VERSION ""

NS_ :

BS_:

BU_:

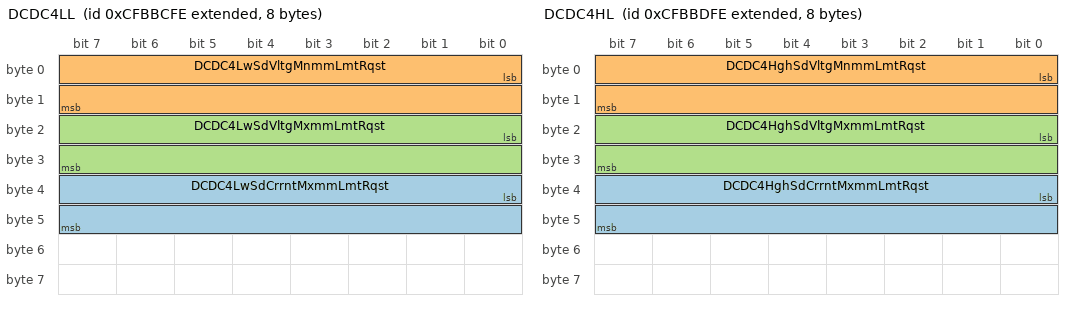
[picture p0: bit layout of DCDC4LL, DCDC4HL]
BO_ 2365308158 DCDC4LL: 8 Vector__XXX
 SG_ DCDC4LwSdCrrntMxmmLmtRqst : 32|16@1+ (0.05,0) [0|3212.75] "A" Vector__XXX
 SG_ DCDC4LwSdVltgMnmmLmtRqst : 0|16@1+ (0.01,0) [0|642.55] "V" Vector__XXX
 SG_ DCDC4LwSdVltgMxmmLmtRqst : 16|16@1+ (0.01,0) [0|642.55] "V" Vector__XXX

BO_ 2365308414 DCDC4HL: 8 Vector__XXX
 SG_ DCDC4HghSdCrrntMxmmLmtRqst : 32|16@1+ (0.05,0) [0|3212.75] "A" Vector__XXX
 SG_ DCDC4HghSdVltgMnmmLmtRqst : 0|16@1+ (0.05,0) [0|3212.75] "V" Vector__XXX
 SG_ DCDC4HghSdVltgMxmmLmtRqst : 16|16@1+ (0.05,0) [0|3212.75] "V" Vector__XXX

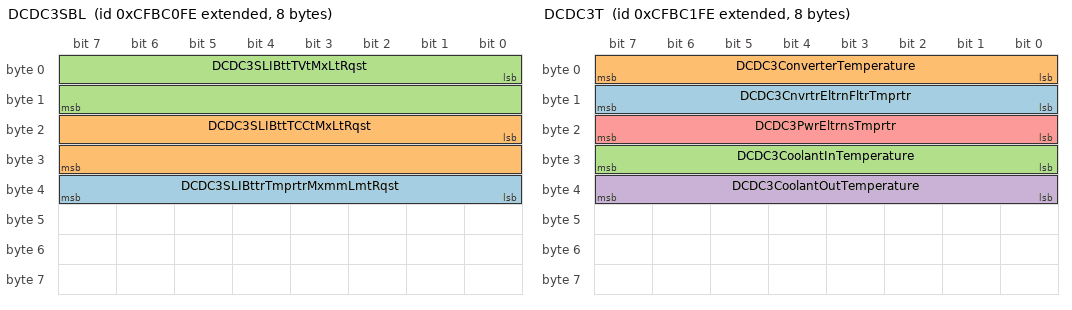
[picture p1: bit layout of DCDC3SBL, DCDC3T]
BO_ 2365309182 DCDC3SBL: 8 Vector__XXX
 SG_ DCDC3SLIBttrTmprtrMxmmLmtRqst : 32|8@1+ (1,-40) [-40|210] "degC" Vector__XXX
 SG_ DCDC3SLIBttTCCtMxLtRqst : 16|16@1+ (0.05,0) [0|3212.75] "A" Vector__XXX
 SG_ DCDC3SLIBttTVtMxLtRqst : 0|16@1+ (0.01,0) [0|642.55] "V" Vector__XXX

BO_ 2365309438 DCDC3T: 8 Vector__XXX
 SG_ DCDC3CnvrtrEltrnFltrTmprtr : 8|8@1+ (1,-40) [-40|210] "degC" Vector__XXX
 SG_ DCDC3ConverterTemperature : 0|8@1+ (1,-40) [-40|210] "degC" Vector__XXX
 SG_ DCDC3CoolantInTemperature : 24|8@1+ (1,-40) [-40|210] "degC" Vector__XXX
 SG_ DCDC3CoolantOutTemperature : 32|8@1+ (1,-40) [-40|210] "degC" Vector__XXX
 SG_ DCDC3PwrEltrnsTmprtr : 16|8@1+ (1,-40) [-40|210] "degC" Vector__XXX

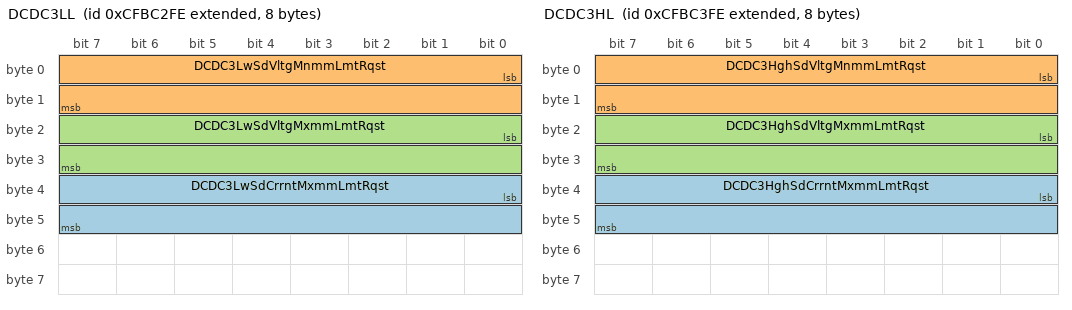
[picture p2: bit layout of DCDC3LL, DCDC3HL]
BO_ 2365309694 DCDC3LL: 8 Vector__XXX
 SG_ DCDC3LwSdCrrntMxmmLmtRqst : 32|16@1+ (0.05,0) [0|3212.75] "A" Vector__XXX
 SG_ DCDC3LwSdVltgMnmmLmtRqst : 0|16@1+ (0.01,0) [0|642.55] "V" Vector__XXX
 SG_ DCDC3LwSdVltgMxmmLmtRqst : 16|16@1+ (0.01,0) [0|642.55] "V" Vector__XXX

BO_ 2365309950 DCDC3HL: 8 Vector__XXX
 SG_ DCDC3HghSdCrrntMxmmLmtRqst : 32|16@1+ (0.05,0) [0|3212.75] "A" Vector__XXX
 SG_ DCDC3HghSdVltgMnmmLmtRqst : 0|16@1+ (0.05,0) [0|3212.75] "V" Vector__XXX
 SG_ DCDC3HghSdVltgMxmmLmtRqst : 16|16@1+ (0.05,0) [0|3212.75] "V" Vector__XXX

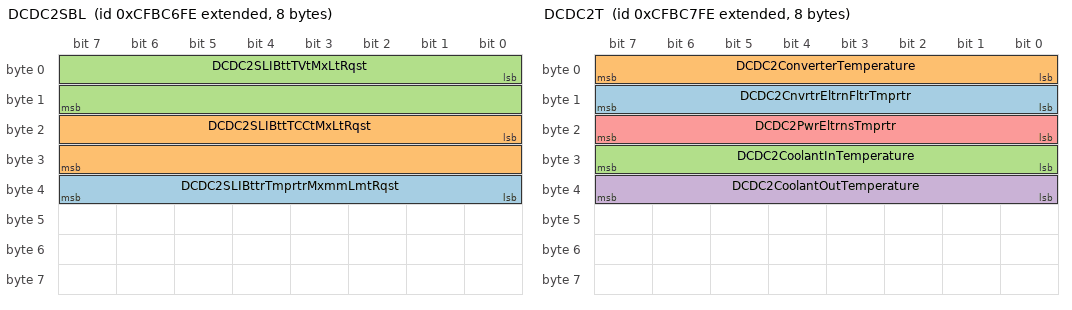
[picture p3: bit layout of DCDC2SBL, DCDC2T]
BO_ 2365310718 DCDC2SBL: 8 Vector__XXX
 SG_ DCDC2SLIBttrTmprtrMxmmLmtRqst : 32|8@1+ (1,-40) [-40|210] "degC" Vector__XXX
 SG_ DCDC2SLIBttTCCtMxLtRqst : 16|16@1+ (0.05,0) [0|3212.75] "A" Vector__XXX
 SG_ DCDC2SLIBttTVtMxLtRqst : 0|16@1+ (0.01,0) [0|642.55] "V" Vector__XXX

BO_ 2365310974 DCDC2T: 8 Vector__XXX
 SG_ DCDC2CnvrtrEltrnFltrTmprtr : 8|8@1+ (1,-40) [-40|210] "degC" Vector__XXX
 SG_ DCDC2ConverterTemperature : 0|8@1+ (1,-40) [-40|210] "degC" Vector__XXX
 SG_ DCDC2CoolantInTemperature : 24|8@1+ (1,-40) [-40|210] "degC" Vector__XXX
 SG_ DCDC2CoolantOutTemperature : 32|8@1+ (1,-40) [-40|210] "degC" Vector__XXX
 SG_ DCDC2PwrEltrnsTmprtr : 16|8@1+ (1,-40) [-40|210] "degC" Vector__XXX

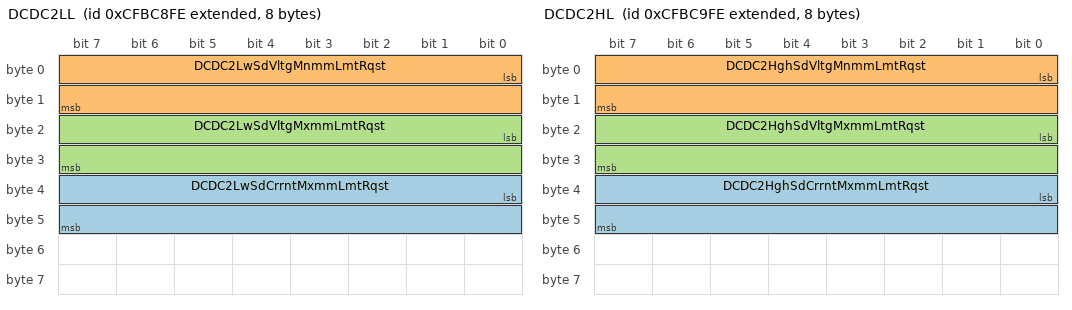
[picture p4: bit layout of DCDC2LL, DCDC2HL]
BO_ 2365311230 DCDC2LL: 8 Vector__XXX
 SG_ DCDC2LwSdCrrntMxmmLmtRqst : 32|16@1+ (0.05,0) [0|3212.75] "A" Vector__XXX
 SG_ DCDC2LwSdVltgMnmmLmtRqst : 0|16@1+ (0.01,0) [0|642.55] "V" Vector__XXX
 SG_ DCDC2LwSdVltgMxmmLmtRqst : 16|16@1+ (0.01,0) [0|642.55] "V" Vector__XXX

BO_ 2365311486 DCDC2HL: 8 Vector__XXX
 SG_ DCDC2HghSdCrrntMxmmLmtRqst : 32|16@1+ (0.05,0) [0|3212.75] "A" Vector__XXX
 SG_ DCDC2HghSdVltgMnmmLmtRqst : 0|16@1+ (0.05,0) [0|3212.75] "V" Vector__XXX
 SG_ DCDC2HghSdVltgMxmmLmtRqst : 16|16@1+ (0.05,0) [0|3212.75] "V" Vector__XXX

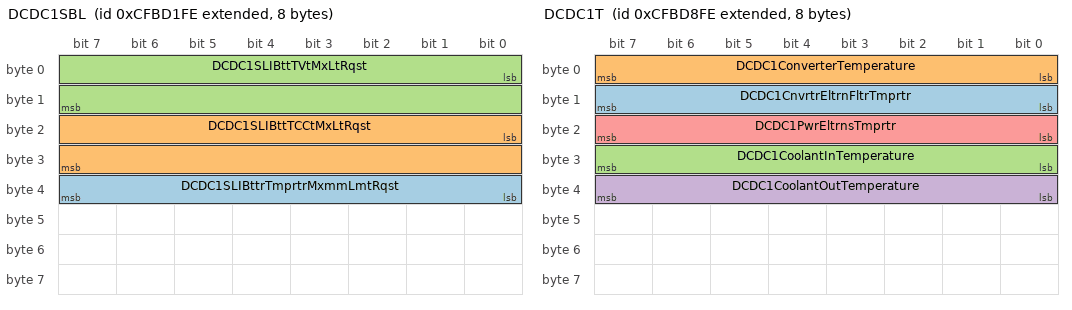
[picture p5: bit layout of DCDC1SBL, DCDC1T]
BO_ 2365313534 DCDC1SBL: 8 Vector__XXX
 SG_ DCDC1SLIBttrTmprtrMxmmLmtRqst : 32|8@1+ (1,-40) [-40|210] "degC" Vector__XXX
 SG_ DCDC1SLIBttTCCtMxLtRqst : 16|16@1+ (0.05,0) [0|3212.75] "A" Vector__XXX
 SG_ DCDC1SLIBttTVtMxLtRqst : 0|16@1+ (0.01,0) [0|642.55] "V" Vector__XXX

BO_ 2365315326 DCDC1T: 8 Vector__XXX
 SG_ DCDC1CnvrtrEltrnFltrTmprtr : 8|8@1+ (1,-40) [-40|210] "degC" Vector__XXX
 SG_ DCDC1ConverterTemperature : 0|8@1+ (1,-40) [-40|210] "degC" Vector__XXX
 SG_ DCDC1CoolantInTemperature : 24|8@1+ (1,-40) [-40|210] "degC" Vector__XXX
 SG_ DCDC1CoolantOutTemperature : 32|8@1+ (1,-40) [-40|210] "degC" Vector__XXX
 SG_ DCDC1PwrEltrnsTmprtr : 16|8@1+ (1,-40) [-40|210] "degC" Vector__XXX

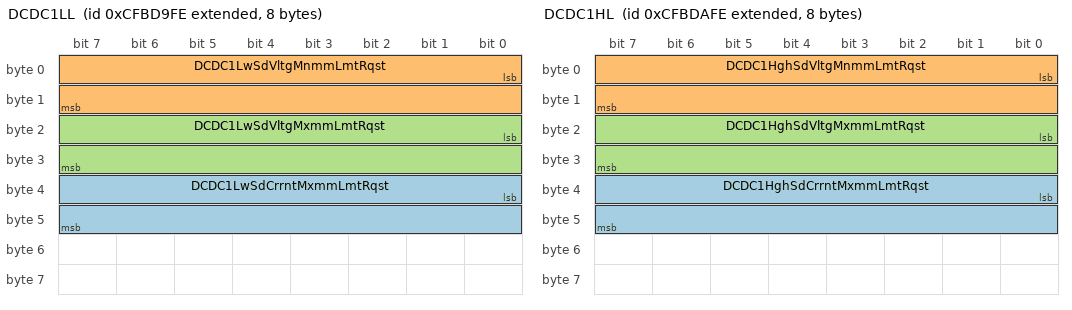
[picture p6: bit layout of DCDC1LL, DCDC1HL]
BO_ 2365315582 DCDC1LL: 8 Vector__XXX
 SG_ DCDC1LwSdCrrntMxmmLmtRqst : 32|16@1+ (0.05,0) [0|3212.75] "A" Vector__XXX
 SG_ DCDC1LwSdVltgMnmmLmtRqst : 0|16@1+ (0.01,0) [0|642.55] "V" Vector__XXX
 SG_ DCDC1LwSdVltgMxmmLmtRqst : 16|16@1+ (0.01,0) [0|642.55] "V" Vector__XXX

BO_ 2365315838 DCDC1HL: 8 Vector__XXX
 SG_ DCDC1HghSdCrrntMxmmLmtRqst : 32|16@1+ (0.05,0) [0|3212.75] "A" Vector__XXX
 SG_ DCDC1HghSdVltgMnmmLmtRqst : 0|16@1+ (0.05,0) [0|3212.75] "V" Vector__XXX
 SG_ DCDC1HghSdVltgMxmmLmtRqst : 16|16@1+ (0.05,0) [0|3212.75] "V" Vector__XXX

BO_ 2365318910 HVESSFC: 8 Vector__XXX
 SG_ HVESSFanEnableCommand : 0|2@1+ (1,0) [0|3] "" Vector__XXX
 SG_ HVESSFanPowerHold : 2|2@1+ (1,0) [0|3] "" Vector__XXX
 SG_ HVESSFanSpeedCommand : 8|16@1+ (0.5,0) [0|32127.5] "rpm" Vector__XXX
 SG_ HVESSFanPercentSpeedCommand : 24|8@1+ (0.4,0) [0|100] "%" Vector__XXX
 SG_ HVESSFanInstance1 : 32|1@1+ (1,0) [0|1] "" Vector__XXX
 SG_ HVESSFanInstance2 : 33|1@1+ (1,0) [0|1] "" Vector__XXX
 SG_ HVESSFanInstance3 : 34|1@1+ (1,0) [0|1] "" Vector__XXX
 SG_ HVESSFanInstance4 : 35|1@1+ (1,0) [0|1] "" Vector__XXX
 SG_ HVESSFanInstance5 : 36|1@1+ (1,0) [0|1] "" Vector__XXX
 SG_ HVESSFanInstance6 : 37|1@1+ (1,0) [0|1] "" Vector__XXX
 SG_ HVESSFanInstance7 : 38|1@1+ (1,0) [0|1] "" Vector__XXX
 SG_ HVESSFanInstance8 : 39|1@1+ (1,0) [0|1] "" Vector__XXX
 SG_ HVESSFanInstance9 : 40|1@1+ (1,0) [0|1] "" Vector__XXX
 SG_ HVESSFanInstance10 : 41|1@1+ (1,0) [0|1] "" Vector__XXX
 SG_ HVESSFanInstance11 : 42|1@1+ (1,0) [0|1] "" Vector__XXX
 SG_ HVESSFanInstance12 : 43|1@1+ (1,0) [0|1] "" Vector__XXX
 SG_ HVESSFanInstance13 : 44|1@1+ (1,0) [0|1] "" Vector__XXX
 SG_ HVESSFanInstance14 : 45|1@1+ (1,0) [0|1] "" Vector__XXX
 SG_ HVESSFanInstance15 : 46|1@1+ (1,0) [0|1] "" Vector__XXX

BO_ 2365322238 CCVS5: 8 Vector__XXX
 SG_ DirectionalVehicleSpeed : 0|16@1+ (0.0078125,-250) [-250|251.992] "km/h" Vector__XXX

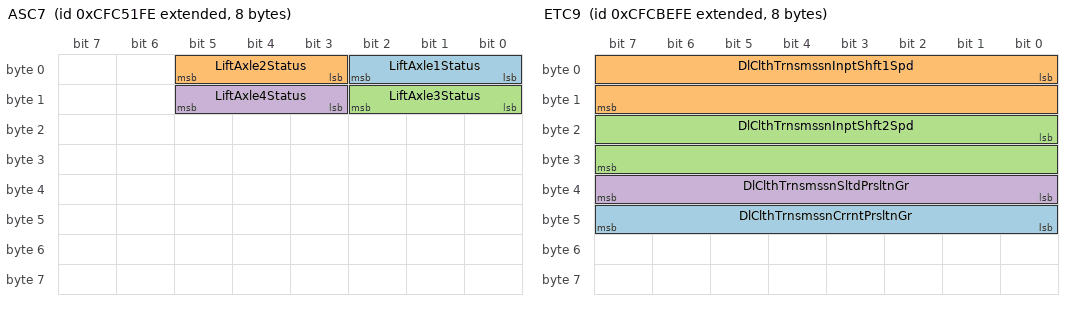
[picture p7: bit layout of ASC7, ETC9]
BO_ 2365346302 ASC7: 8 Vector__XXX
 SG_ LiftAxle1Status : 0|3@1+ (1,0) [0|7] "" Vector__XXX
 SG_ LiftAxle2Status : 3|3@1+ (1,0) [0|7] "" Vector__XXX
 SG_ LiftAxle3Status : 8|3@1+ (1,0) [0|7] "" Vector__XXX
 SG_ LiftAxle4Status : 11|3@1+ (1,0) [0|7] "" Vector__XXX

BO_ 2365348350 ELS: 8 Vector__XXX
 SG_ EngineLoadShareStatus : 2|4@1+ (1,0) [0|15] "" Vector__XXX
 SG_ EngineUnloadStatus : 0|2@1+ (1,0) [0|3] "" Vector__XXX

BO_ 2365363710 ECPMSI: 8 Vector__XXX
 SG_ EngnClndrPrssrMntr1PrlmnrFMI : 0|5@1+ (1,0) [0|31] "binary" Vector__XXX
 SG_ EngnClndrPrssrMntr2PrlmnrFMI : 8|5@1+ (1,0) [0|31] "binary" Vector__XXX

BO_ 2365374206 ETC9: 8 Vector__XXX
 SG_ DlClthTrnsmssnCrrntPrsltnGr : 40|8@1+ (1,-125) [-125|125] "gear value" Vector__XXX
 SG_ DlClthTrnsmssnInptShft1Spd : 0|16@1+ (0.125,0) [0|8031.875] "rpm" Vector__XXX
 SG_ DlClthTrnsmssnInptShft2Spd : 16|16@1+ (0.125,0) [0|8031.875] "rpm" Vector__XXX
 SG_ DlClthTrnsmssnSltdPrsltnGr : 32|8@1+ (1,-125) [-125|125] "gear value" Vector__XXX

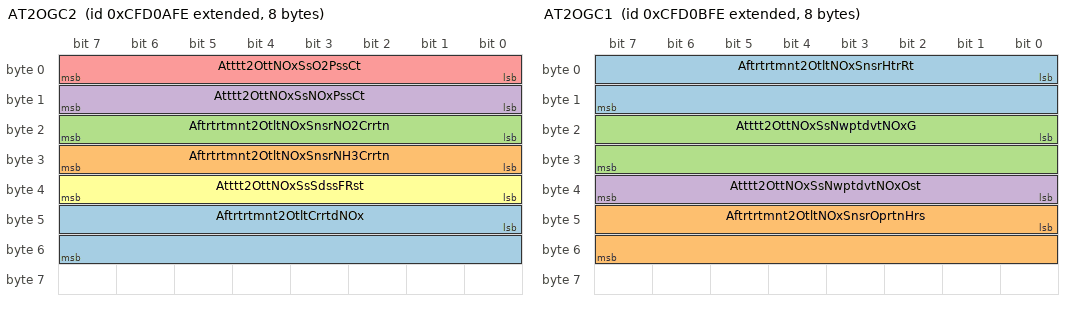
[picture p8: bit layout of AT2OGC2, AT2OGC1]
BO_ 2365393662 AT2OGC2: 8 Vector__XXX
 SG_ Aftrtrtmnt2OtltCrrtdNOx : 40|16@1+ (0.05,-200) [-200|3012.75] "ppm" Vector__XXX
 SG_ Aftrtrtmnt2OtltNOxSnsrNH3Crrtn : 24|8@1+ (0.5,0) [0|125] "%" Vector__XXX
 SG_ Aftrtrtmnt2OtltNOxSnsrNO2Crrtn : 16|8@1+ (0.5,0) [0|125] "%" Vector__XXX
 SG_ Atttt2OttNOxSsNOxPssCt : 8|8@1+ (0.5,0) [0|125] "%/bar" Vector__XXX
 SG_ Atttt2OttNOxSsO2PssCt : 0|8@1+ (0.5,0) [0|125] "%/bar" Vector__XXX
 SG_ Atttt2OttNOxSsSdssFRst : 32|8@1+ (1,0) [0|250] "Ratio" Vector__XXX

BO_ 2365393918 AT2OGC1: 8 Vector__XXX
 SG_ Aftrtrtmnt2OtltNOxSnsrHtrRt : 0|16@1+ (0.001,0) [0|64.255] "Ratio" Vector__XXX
 SG_ Aftrtrtmnt2OtltNOxSnsrOprtnHrs : 40|16@1+ (1,0) [0|64255] "h" Vector__XXX
 SG_ Atttt2OttNOxSsNwptdvtNOxG : 16|16@1+ (0.1,-100) [-100|6325.5] "%" Vector__XXX
 SG_ Atttt2OttNOxSsNwptdvtNOxOst : 32|8@1+ (1,-125) [-125|125] "ppm" Vector__XXX

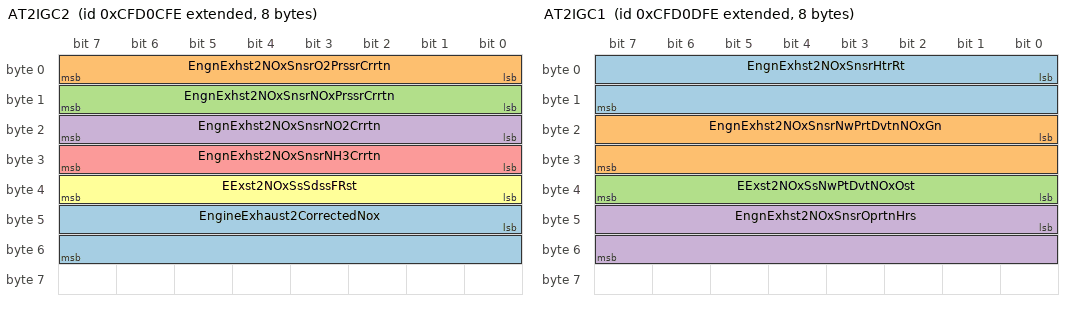
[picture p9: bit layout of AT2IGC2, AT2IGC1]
BO_ 2365394174 AT2IGC2: 8 Vector__XXX
 SG_ EngineExhaust2CorrectedNox : 40|16@1+ (0.05,-200) [-200|3012.75] "ppm" Vector__XXX
 SG_ EngnExhst2NOxSnsrO2PrssrCrrtn : 0|8@1+ (0.5,0) [0|125] "%/bar" Vector__XXX
 SG_ EngnExhst2NOxSnsrNOxPrssrCrrtn : 8|8@1+ (0.5,0) [0|125] "%/bar" Vector__XXX
 SG_ EngnExhst2NOxSnsrNO2Crrtn : 16|8@1+ (0.5,0) [0|125] "%" Vector__XXX
 SG_ EngnExhst2NOxSnsrNH3Crrtn : 24|8@1+ (0.5,0) [0|125] "%" Vector__XXX
 SG_ EExst2NOxSsSdssFRst : 32|8@1+ (1,0) [0|250] "Ratio" Vector__XXX

BO_ 2365394430 AT2IGC1: 8 Vector__XXX
 SG_ EngnExhst2NOxSnsrHtrRt : 0|16@1+ (0.001,0) [0|64.255] "Ratio" Vector__XXX
 SG_ EngnExhst2NOxSnsrNwPrtDvtnNOxGn : 16|16@1+ (0.1,-100) [-100|6325.5] "%" Vector__XXX
 SG_ EExst2NOxSsNwPtDvtNOxOst : 32|8@1+ (1,-125) [-125|125] "ppm" Vector__XXX
 SG_ EngnExhst2NOxSnsrOprtnHrs : 40|16@1+ (1,0) [0|64255] "h" Vector__XXX

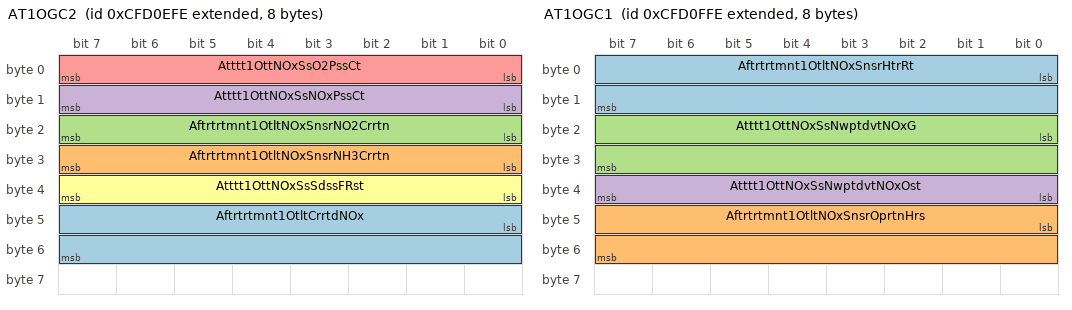
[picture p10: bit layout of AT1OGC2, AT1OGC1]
BO_ 2365394686 AT1OGC2: 8 Vector__XXX
 SG_ Aftrtrtmnt1OtltCrrtdNOx : 40|16@1+ (0.05,-200) [-200|3012.75] "ppm" Vector__XXX
 SG_ Aftrtrtmnt1OtltNOxSnsrNH3Crrtn : 24|8@1+ (0.5,0) [0|125] "%" Vector__XXX
 SG_ Aftrtrtmnt1OtltNOxSnsrNO2Crrtn : 16|8@1+ (0.5,0) [0|125] "%" Vector__XXX
 SG_ Atttt1OttNOxSsNOxPssCt : 8|8@1+ (0.5,0) [0|125] "%/bar" Vector__XXX
 SG_ Atttt1OttNOxSsO2PssCt : 0|8@1+ (0.5,0) [0|125] "%/bar" Vector__XXX
 SG_ Atttt1OttNOxSsSdssFRst : 32|8@1+ (1,0) [0|250] "Ratio" Vector__XXX

BO_ 2365394942 AT1OGC1: 8 Vector__XXX
 SG_ Aftrtrtmnt1OtltNOxSnsrHtrRt : 0|16@1+ (0.001,0) [0|64.255] "Ratio" Vector__XXX
 SG_ Aftrtrtmnt1OtltNOxSnsrOprtnHrs : 40|16@1+ (1,0) [0|64255] "h" Vector__XXX
 SG_ Atttt1OttNOxSsNwptdvtNOxG : 16|16@1+ (0.1,-100) [-100|6325.5] "%" Vector__XXX
 SG_ Atttt1OttNOxSsNwptdvtNOxOst : 32|8@1+ (1,-125) [-125|125] "ppm" Vector__XXX

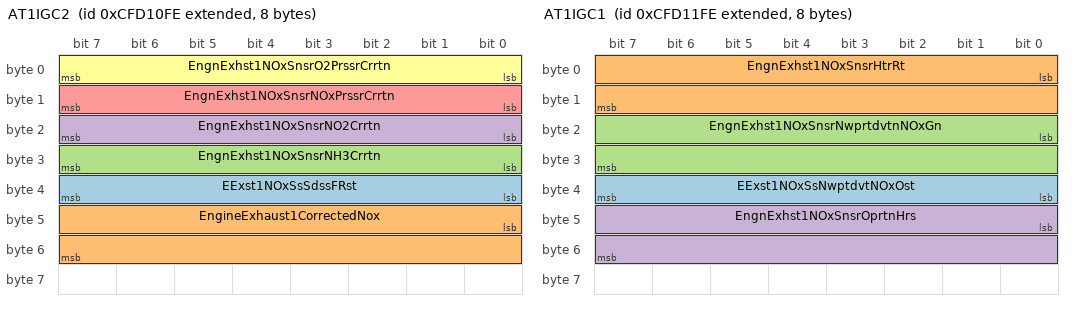
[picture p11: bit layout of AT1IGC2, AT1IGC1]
BO_ 2365395198 AT1IGC2: 8 Vector__XXX
 SG_ EExst1NOxSsSdssFRst : 32|8@1+ (1,0) [0|250] "Ratio" Vector__XXX
 SG_ EngineExhaust1CorrectedNox : 40|16@1+ (0.05,-200) [-200|3012.75] "ppm" Vector__XXX
 SG_ EngnExhst1NOxSnsrNH3Crrtn : 24|8@1+ (0.5,0) [0|125] "%" Vector__XXX
 SG_ EngnExhst1NOxSnsrNO2Crrtn : 16|8@1+ (0.5,0) [0|125] "%" Vector__XXX
 SG_ EngnExhst1NOxSnsrNOxPrssrCrrtn : 8|8@1+ (0.5,0) [0|125] "%/bar" Vector__XXX
 SG_ EngnExhst1NOxSnsrO2PrssrCrrtn : 0|8@1+ (0.5,0) [0|125] "%/bar" Vector__XXX

BO_ 2365395454 AT1IGC1: 8 Vector__XXX
 SG_ EExst1NOxSsNwptdvtNOxOst : 32|8@1+ (1,-125) [-125|125] "ppm" Vector__XXX
 SG_ EngnExhst1NOxSnsrHtrRt : 0|16@1+ (0.001,0) [0|64.255] "Ratio" Vector__XXX
 SG_ EngnExhst1NOxSnsrNwprtdvtnNOxGn : 16|16@1+ (0.1,-100) [-100|6325.5] "%" Vector__XXX
 SG_ EngnExhst1NOxSnsrOprtnHrs : 40|16@1+ (1,0) [0|64255] "h" Vector__XXX

BO_ 2365400062 EJM10: 8 Vector__XXX
 SG_ Joystick10Button13PressedStatus : 62|2@1+ (1,0) [0|3] "" Vector__XXX
 SG_ Joystick10Button14PressedStatus : 60|2@1+ (1,0) [0|3] "" Vector__XXX
 SG_ Joystick10Button15PressedStatus : 58|2@1+ (1,0) [0|3] "" Vector__XXX
 SG_ Joystick10Button16PressedStatus : 56|2@1+ (1,0) [0|3] "" Vector__XXX
 SG_ Joystick10GripXAxisPosition : 6|10@1+ (0.1,0) [0|102] "%" Vector__XXX
 SG_ Joystick10GripYAxisPosition : 22|10@1+ (0.1,0) [0|102] "%" Vector__XXX
 SG_ Joystick10ThetaAxisPosition : 38|10@1+ (0.1,0) [0|102] "%" Vector__XXX
 SG_ Jst10GpXAxsLvRtPstvPstStts : 4|2@1+ (1,0) [0|3] "" Vector__XXX
 SG_ Jst10GpYAxsLvFwdPstvPstStts : 20|2@1+ (1,0) [0|3] "" Vector__XXX
 SG_ Jst10TtAxsCtCwsNtvPstStts : 34|2@1+ (1,0) [0|3] "" Vector__XXX
 SG_ Jstk10GrpXAxsDtntPstnStts : 54|2@1+ (1,0) [0|3] "" Vector__XXX
 SG_ Jstk10GrpXAxsLvrLftNgtvPstnStts : 2|2@1+ (1,0) [0|3] "" Vector__XXX
 SG_ Jstk10GrpXAxsNtrlPstnStts : 0|2@1+ (1,0) [0|3] "" Vector__XXX
 SG_ Jstk10GrpYAxsDtntPstnStts : 52|2@1+ (1,0) [0|3] "" Vector__XXX
 SG_ Jstk10GrpYAxsLvrBkNgtvPstnStts : 18|2@1+ (1,0) [0|3] "" Vector__XXX
 SG_ Jstk10GrpYAxsNtrlPstnStts : 16|2@1+ (1,0) [0|3] "" Vector__XXX
 SG_ Jstk10ThtAxsClkwsPstvPstnStts : 36|2@1+ (1,0) [0|3] "" Vector__XXX
 SG_ Jstk10ThtAxsDtntPstnStts : 50|2@1+ (1,0) [0|3] "" Vector__XXX
 SG_ Jstk10ThtAxsNtrlPstnStts : 32|2@1+ (1,0) [0|3] "" Vector__XXX

BO_ 2365400318 BJM10: 8 Vector__XXX
 SG_ Joystick10Button10PressedStatus : 60|2@1+ (1,0) [0|3] "" Vector__XXX
 SG_ Joystick10Button11PressedStatus : 58|2@1+ (1,0) [0|3] "" Vector__XXX
 SG_ Joystick10Button12PressedStatus : 56|2@1+ (1,0) [0|3] "" Vector__XXX
 SG_ Joystick10Button1PressedStatus : 46|2@1+ (1,0) [0|3] "" Vector__XXX
 SG_ Joystick10Button2PressedStatus : 44|2@1+ (1,0) [0|3] "" Vector__XXX
 SG_ Joystick10Button3PressedStatus : 42|2@1+ (1,0) [0|3] "" Vector__XXX
 SG_ Joystick10Button4PressedStatus : 40|2@1+ (1,0) [0|3] "" Vector__XXX
 SG_ Joystick10Button5PressedStatus : 54|2@1+ (1,0) [0|3] "" Vector__XXX
 SG_ Joystick10Button6PressedStatus : 52|2@1+ (1,0) [0|3] "" Vector__XXX
 SG_ Joystick10Button7PressedStatus : 50|2@1+ (1,0) [0|3] "" Vector__XXX
 SG_ Joystick10Button8PressedStatus : 48|2@1+ (1,0) [0|3] "" Vector__XXX
 SG_ Joystick10Button9PressedStatus : 62|2@1+ (1,0) [0|3] "" Vector__XXX
 SG_ Joystick10XAxisPosition : 6|10@1+ (0.1,0) [0|102] "%" Vector__XXX
 SG_ Joystick10YAxisPosition : 22|10@1+ (0.1,0) [0|102] "%" Vector__XXX
 SG_ Jstk10XAxsDtntPstnStts : 38|2@1+ (1,0) [0|3] "" Vector__XXX
 SG_ Jstk10XAxsLvrLftNgtvPstnStts : 2|2@1+ (1,0) [0|3] "" Vector__XXX
 SG_ Jstk10XAxsLvrRghtPstvPstnStts : 4|2@1+ (1,0) [0|3] "" Vector__XXX
 SG_ Jstk10XAxsNtrlPstnStts : 0|2@1+ (1,0) [0|3] "" Vector__XXX
 SG_ Jstk10YAxsDtntPstnStts : 36|2@1+ (1,0) [0|3] "" Vector__XXX
 SG_ Jstk10YAxsLvrBkNgtvPstnStts : 18|2@1+ (1,0) [0|3] "" Vector__XXX
 SG_ Jstk10YAxsLvrFrwrdPstvPstnStts : 20|2@1+ (1,0) [0|3] "" Vector__XXX
 SG_ Jstk10YAxsNtrlPstnStts : 16|2@1+ (1,0) [0|3] "" Vector__XXX

BO_ 2365400574 EJM9: 8 Vector__XXX
 SG_ Joystick9Button13PressedStatus : 62|2@1+ (1,0) [0|3] "" Vector__XXX
 SG_ Joystick9Button14PressedStatus : 60|2@1+ (1,0) [0|3] "" Vector__XXX
 SG_ Joystick9Button15PressedStatus : 58|2@1+ (1,0) [0|3] "" Vector__XXX
 SG_ Joystick9Button16PressedStatus : 56|2@1+ (1,0) [0|3] "" Vector__XXX
 SG_ Joystick9GripXAxisPosition : 6|10@1+ (0.1,0) [0|102] "%" Vector__XXX
 SG_ Joystick9GripYAxisPosition : 22|10@1+ (0.1,0) [0|102] "%" Vector__XXX
 SG_ Joystick9ThetaAxisPosition : 38|10@1+ (0.1,0) [0|102] "%" Vector__XXX
 SG_ Jst9GpYAxsLvFwdPstvPstStts : 20|2@1+ (1,0) [0|3] "" Vector__XXX
 SG_ Jst9TtAxsCtCwsNtvPstStts : 34|2@1+ (1,0) [0|3] "" Vector__XXX
 SG_ Jstk9GrpXAxsDtntPstnStts : 54|2@1+ (1,0) [0|3] "" Vector__XXX
 SG_ Jstk9GrpXAxsLvrLftNgtvPstnStts : 2|2@1+ (1,0) [0|3] "" Vector__XXX
 SG_ Jstk9GrpXAxsLvrRghtPstvPstnStts : 4|2@1+ (1,0) [0|3] "" Vector__XXX
 SG_ Jstk9GrpXAxsNtrlPstnStts : 0|2@1+ (1,0) [0|3] "" Vector__XXX
 SG_ Jstk9GrpYAxsDtntPstnStts : 52|2@1+ (1,0) [0|3] "" Vector__XXX
 SG_ Jstk9GrpYAxsLvrBkNgtvPstnStts : 18|2@1+ (1,0) [0|3] "" Vector__XXX
 SG_ Jstk9GrpYAxsNtrlPstnStts : 16|2@1+ (1,0) [0|3] "" Vector__XXX
 SG_ Jstk9ThtAxsClkwsPstvPstnStts : 36|2@1+ (1,0) [0|3] "" Vector__XXX
 SG_ Jstk9ThtAxsDtntPstnStts : 50|2@1+ (1,0) [0|3] "" Vector__XXX
 SG_ Jstk9ThtAxsNtrlPstnStts : 32|2@1+ (1,0) [0|3] "" Vector__XXX

BO_ 2365400830 BJM9: 8 Vector__XXX
 SG_ Joystick9Button10PressedStatus : 60|2@1+ (1,0) [0|3] "" Vector__XXX
 SG_ Joystick9Button11PressedStatus : 58|2@1+ (1,0) [0|3] "" Vector__XXX
 SG_ Joystick9Button12PressedStatus : 56|2@1+ (1,0) [0|3] "" Vector__XXX
 SG_ Joystick9Button1PressedStatus : 46|2@1+ (1,0) [0|3] "" Vector__XXX
 SG_ Joystick9Button2PressedStatus : 44|2@1+ (1,0) [0|3] "" Vector__XXX
 SG_ Joystick9Button3PressedStatus : 42|2@1+ (1,0) [0|3] "" Vector__XXX
 SG_ Joystick9Button4PressedStatus : 40|2@1+ (1,0) [0|3] "" Vector__XXX
 SG_ Joystick9Button5PressedStatus : 54|2@1+ (1,0) [0|3] "" Vector__XXX
 SG_ Joystick9Button6PressedStatus : 52|2@1+ (1,0) [0|3] "" Vector__XXX
 SG_ Joystick9Button7PressedStatus : 50|2@1+ (1,0) [0|3] "" Vector__XXX
 SG_ Joystick9Button8PressedStatus : 48|2@1+ (1,0) [0|3] "" Vector__XXX
 SG_ Joystick9Button9PressedStatus : 62|2@1+ (1,0) [0|3] "" Vector__XXX
 SG_ Joystick9XAxisPosition : 6|10@1+ (0.1,0) [0|102] "%" Vector__XXX
 SG_ Joystick9YAxisPosition : 22|10@1+ (0.1,0) [0|102] "%" Vector__XXX
 SG_ Jstk9XAxsDtntPstnStts : 38|2@1+ (1,0) [0|3] "" Vector__XXX
 SG_ Jstk9XAxsLvrLftNgtvPstnStts : 2|2@1+ (1,0) [0|3] "" Vector__XXX
 SG_ Jstk9XAxsLvrRghtPstvPstnStts : 4|2@1+ (1,0) [0|3] "" Vector__XXX
 SG_ Jstk9XAxsNtrlPstnStts : 0|2@1+ (1,0) [0|3] "" Vector__XXX
 SG_ Jstk9YAxsDtntPstnStts : 36|2@1+ (1,0) [0|3] "" Vector__XXX
 SG_ Jstk9YAxsLvrBkNgtvPstnStts : 18|2@1+ (1,0) [0|3] "" Vector__XXX
 SG_ Jstk9YAxsLvrFrwrdPstvPstnStts : 20|2@1+ (1,0) [0|3] "" Vector__XXX
 SG_ Jstk9YAxsNtrlPstnStts : 16|2@1+ (1,0) [0|3] "" Vector__XXX

BO_ 2365401086 EJM8: 8 Vector__XXX
 SG_ Joystick8Button13PressedStatus : 62|2@1+ (1,0) [0|3] "" Vector__XXX
 SG_ Joystick8Button14PressedStatus : 60|2@1+ (1,0) [0|3] "" Vector__XXX
 SG_ Joystick8Button15PressedStatus : 58|2@1+ (1,0) [0|3] "" Vector__XXX
 SG_ Joystick8Button16PressedStatus : 56|2@1+ (1,0) [0|3] "" Vector__XXX
 SG_ Joystick8GripXAxisPosition : 6|10@1+ (0.1,0) [0|102] "%" Vector__XXX
 SG_ Joystick8GripYAxisPosition : 22|10@1+ (0.1,0) [0|102] "%" Vector__XXX
 SG_ Joystick8ThetaAxisPosition : 38|10@1+ (0.1,0) [0|102] "%" Vector__XXX
 SG_ Jst8GpYAxsLvFwdPstvPstStts : 20|2@1+ (1,0) [0|3] "" Vector__XXX
 SG_ Jst8TtAxsCtCwsNtvPstStts : 34|2@1+ (1,0) [0|3] "" Vector__XXX
 SG_ Jstk8GrpXAxsDtntPstnStts : 54|2@1+ (1,0) [0|3] "" Vector__XXX
 SG_ Jstk8GrpXAxsLvrLftNgtvPstnStts : 2|2@1+ (1,0) [0|3] "" Vector__XXX
 SG_ Jstk8GrpXAxsLvrRghtPstvPstnStts : 4|2@1+ (1,0) [0|3] "" Vector__XXX
 SG_ Jstk8GrpXAxsNtrlPstnStts : 0|2@1+ (1,0) [0|3] "" Vector__XXX
 SG_ Jstk8GrpYAxsDtntPstnStts : 52|2@1+ (1,0) [0|3] "" Vector__XXX
 SG_ Jstk8GrpYAxsLvrBkNgtvPstnStts : 18|2@1+ (1,0) [0|3] "" Vector__XXX
 SG_ Jstk8GrpYAxsNtrlPstnStts : 16|2@1+ (1,0) [0|3] "" Vector__XXX
 SG_ Jstk8ThtAxsClkwsPstvPstnStts : 36|2@1+ (1,0) [0|3] "" Vector__XXX
 SG_ Jstk8ThtAxsDtntPstnStts : 50|2@1+ (1,0) [0|3] "" Vector__XXX
 SG_ Jstk8ThtAxsNtrlPstnStts : 32|2@1+ (1,0) [0|3] "" Vector__XXX

BO_ 2365401342 BJM8: 8 Vector__XXX
 SG_ Joystick8Button10PressedStatus : 60|2@1+ (1,0) [0|3] "" Vector__XXX
 SG_ Joystick8Button11PressedStatus : 58|2@1+ (1,0) [0|3] "" Vector__XXX
 SG_ Joystick8Button12PressedStatus : 56|2@1+ (1,0) [0|3] "" Vector__XXX
 SG_ Joystick8Button1PressedStatus : 46|2@1+ (1,0) [0|3] "" Vector__XXX
 SG_ Joystick8Button2PressedStatus : 44|2@1+ (1,0) [0|3] "" Vector__XXX
 SG_ Joystick8Button3PressedStatus : 42|2@1+ (1,0) [0|3] "" Vector__XXX
 SG_ Joystick8Button4PressedStatus : 40|2@1+ (1,0) [0|3] "" Vector__XXX
 SG_ Joystick8Button5PressedStatus : 54|2@1+ (1,0) [0|3] "" Vector__XXX
 SG_ Joystick8Button6PressedStatus : 52|2@1+ (1,0) [0|3] "" Vector__XXX
 SG_ Joystick8Button7PressedStatus : 50|2@1+ (1,0) [0|3] "" Vector__XXX
 SG_ Joystick8Button8PressedStatus : 48|2@1+ (1,0) [0|3] "" Vector__XXX
 SG_ Joystick8Button9PressedStatus : 62|2@1+ (1,0) [0|3] "" Vector__XXX
 SG_ Joystick8XAxisPosition : 6|10@1+ (0.1,0) [0|102] "%" Vector__XXX
 SG_ Joystick8YAxisPosition : 22|10@1+ (0.1,0) [0|102] "%" Vector__XXX
 SG_ Jstk8XAxsDtntPstnStts : 38|2@1+ (1,0) [0|3] "" Vector__XXX
 SG_ Jstk8XAxsLvrLftNgtvPstnStts : 2|2@1+ (1,0) [0|3] "" Vector__XXX
 SG_ Jstk8XAxsLvrRghtPstvPstnStts : 4|2@1+ (1,0) [0|3] "" Vector__XXX
 SG_ Jstk8XAxsNtrlPstnStts : 0|2@1+ (1,0) [0|3] "" Vector__XXX
 SG_ Jstk8YAxsDtntPstnStts : 36|2@1+ (1,0) [0|3] "" Vector__XXX
 SG_ Jstk8YAxsLvrBkNgtvPstnStts : 18|2@1+ (1,0) [0|3] "" Vector__XXX
 SG_ Jstk8YAxsLvrFrwrdPstvPstnStts : 20|2@1+ (1,0) [0|3] "" Vector__XXX
 SG_ Jstk8YAxsNtrlPstnStts : 16|2@1+ (1,0) [0|3] "" Vector__XXX

BO_ 2365401598 EJM7: 8 Vector__XXX
 SG_ Joystick7Button13PressedStatus : 62|2@1+ (1,0) [0|3] "" Vector__XXX
 SG_ Joystick7Button14PressedStatus : 60|2@1+ (1,0) [0|3] "" Vector__XXX
 SG_ Joystick7Button15PressedStatus : 58|2@1+ (1,0) [0|3] "" Vector__XXX
 SG_ Joystick7Button16PressedStatus : 56|2@1+ (1,0) [0|3] "" Vector__XXX
 SG_ Joystick7GripXAxisPosition : 6|10@1+ (0.1,0) [0|102] "%" Vector__XXX
 SG_ Joystick7GripYAxisPosition : 22|10@1+ (0.1,0) [0|102] "%" Vector__XXX
 SG_ Joystick7ThetaAxisPosition : 38|10@1+ (0.1,0) [0|102] "%" Vector__XXX
 SG_ Jst7GpYAxsLvFwdPstvPstStts : 20|2@1+ (1,0) [0|3] "" Vector__XXX
 SG_ Jst7TtAxsCtCwsNtvPstStts : 34|2@1+ (1,0) [0|3] "" Vector__XXX
 SG_ Jstk7GrpXAxsDtntPstnStts : 54|2@1+ (1,0) [0|3] "" Vector__XXX
 SG_ Jstk7GrpXAxsLvrLftNgtvPstnStts : 2|2@1+ (1,0) [0|3] "" Vector__XXX
 SG_ Jstk7GrpXAxsLvrRghtPstvPstnStts : 4|2@1+ (1,0) [0|3] "" Vector__XXX
 SG_ Jstk7GrpXAxsNtrlPstnStts : 0|2@1+ (1,0) [0|3] "" Vector__XXX
 SG_ Jstk7GrpYAxsDtntPstnStts : 52|2@1+ (1,0) [0|3] "" Vector__XXX
 SG_ Jstk7GrpYAxsLvrBkNgtvPstnStts : 18|2@1+ (1,0) [0|3] "" Vector__XXX
 SG_ Jstk7GrpYAxsNtrlPstnStts : 16|2@1+ (1,0) [0|3] "" Vector__XXX
 SG_ Jstk7ThtAxsClkwsPstvPstnStts : 36|2@1+ (1,0) [0|3] "" Vector__XXX
 SG_ Jstk7ThtAxsDtntPstnStts : 50|2@1+ (1,0) [0|3] "" Vector__XXX
 SG_ Jstk7ThtAxsNtrlPstnStts : 32|2@1+ (1,0) [0|3] "" Vector__XXX

BO_ 2365401854 BJM7: 8 Vector__XXX
 SG_ Joystick7Button10PressedStatus : 60|2@1+ (1,0) [0|3] "" Vector__XXX
 SG_ Joystick7Button11PressedStatus : 58|2@1+ (1,0) [0|3] "" Vector__XXX
 SG_ Joystick7Button12PressedStatus : 56|2@1+ (1,0) [0|3] "" Vector__XXX
 SG_ Joystick7Button1PressedStatus : 46|2@1+ (1,0) [0|3] "" Vector__XXX
 SG_ Joystick7Button2PressedStatus : 44|2@1+ (1,0) [0|3] "" Vector__XXX
 SG_ Joystick7Button3PressedStatus : 42|2@1+ (1,0) [0|3] "" Vector__XXX
 SG_ Joystick7Button4PressedStatus : 40|2@1+ (1,0) [0|3] "" Vector__XXX
 SG_ Joystick7Button5PressedStatus : 54|2@1+ (1,0) [0|3] "" Vector__XXX
 SG_ Joystick7Button6PressedStatus : 52|2@1+ (1,0) [0|3] "" Vector__XXX
 SG_ Joystick7Button7PressedStatus : 50|2@1+ (1,0) [0|3] "" Vector__XXX
 SG_ Joystick7Button8PressedStatus : 48|2@1+ (1,0) [0|3] "" Vector__XXX
 SG_ Joystick7Button9PressedStatus : 62|2@1+ (1,0) [0|3] "" Vector__XXX
 SG_ Joystick7XAxisPosition : 6|10@1+ (0.1,0) [0|102] "%" Vector__XXX
 SG_ Joystick7YAxisPosition : 22|10@1+ (0.1,0) [0|102] "%" Vector__XXX
 SG_ Jstk7XAxsDtntPstnStts : 38|2@1+ (1,0) [0|3] "" Vector__XXX
 SG_ Jstk7XAxsLvrLftNgtvPstnStts : 2|2@1+ (1,0) [0|3] "" Vector__XXX
 SG_ Jstk7XAxsLvrRghtPstvPstnStts : 4|2@1+ (1,0) [0|3] "" Vector__XXX
 SG_ Jstk7XAxsNtrlPstnStts : 0|2@1+ (1,0) [0|3] "" Vector__XXX
 SG_ Jstk7YAxsDtntPstnStts : 36|2@1+ (1,0) [0|3] "" Vector__XXX
 SG_ Jstk7YAxsLvrBkNgtvPstnStts : 18|2@1+ (1,0) [0|3] "" Vector__XXX
 SG_ Jstk7YAxsLvrFrwrdPstvPstnStts : 20|2@1+ (1,0) [0|3] "" Vector__XXX
 SG_ Jstk7YAxsNtrlPstnStts : 16|2@1+ (1,0) [0|3] "" Vector__XXX

BO_ 2365402110 EJM6: 8 Vector__XXX
 SG_ Joystick6Button13PressedStatus : 62|2@1+ (1,0) [0|3] "" Vector__XXX
 SG_ Joystick6Button14PressedStatus : 60|2@1+ (1,0) [0|3] "" Vector__XXX
 SG_ Joystick6Button15PressedStatus : 58|2@1+ (1,0) [0|3] "" Vector__XXX
 SG_ Joystick6Button16PressedStatus : 56|2@1+ (1,0) [0|3] "" Vector__XXX
 SG_ Joystick6GripXAxisPosition : 6|10@1+ (0.1,0) [0|102] "%" Vector__XXX
 SG_ Joystick6GripYAxisPosition : 22|10@1+ (0.1,0) [0|102] "%" Vector__XXX
 SG_ Joystick6ThetaAxisPosition : 38|10@1+ (0.1,0) [0|102] "%" Vector__XXX
 SG_ Jst6GpYAxsLvFwdPstvPstStts : 20|2@1+ (1,0) [0|3] "" Vector__XXX
 SG_ Jst6TtAxsCtCwsNtvPstStts : 34|2@1+ (1,0) [0|3] "" Vector__XXX
 SG_ Jstk6GrpXAxsDtntPstnStts : 54|2@1+ (1,0) [0|3] "" Vector__XXX
 SG_ Jstk6GrpXAxsLvrLftNgtvPstnStts : 2|2@1+ (1,0) [0|3] "" Vector__XXX
 SG_ Jstk6GrpXAxsLvrRghtPstvPstnStts : 4|2@1+ (1,0) [0|3] "" Vector__XXX
 SG_ Jstk6GrpXAxsNtrlPstnStts : 0|2@1+ (1,0) [0|3] "" Vector__XXX
 SG_ Jstk6GrpYAxsDtntPstnStts : 52|2@1+ (1,0) [0|3] "" Vector__XXX
 SG_ Jstk6GrpYAxsLvrBkNgtvPstnStts : 18|2@1+ (1,0) [0|3] "" Vector__XXX
 SG_ Jstk6GrpYAxsNtrlPstnStts : 16|2@1+ (1,0) [0|3] "" Vector__XXX
 SG_ Jstk6ThtAxsClkwsPstvPstnStts : 36|2@1+ (1,0) [0|3] "" Vector__XXX
 SG_ Jstk6ThtAxsDtntPstnStts : 50|2@1+ (1,0) [0|3] "" Vector__XXX
 SG_ Jstk6ThtAxsNtrlPstnStts : 32|2@1+ (1,0) [0|3] "" Vector__XXX

BO_ 2365402366 BJM6: 8 Vector__XXX
 SG_ Joystick6Button10PressedStatus : 60|2@1+ (1,0) [0|3] "" Vector__XXX
 SG_ Joystick6Button11PressedStatus : 58|2@1+ (1,0) [0|3] "" Vector__XXX
 SG_ Joystick6Button12PressedStatus : 56|2@1+ (1,0) [0|3] "" Vector__XXX
 SG_ Joystick6Button1PressedStatus : 46|2@1+ (1,0) [0|3] "" Vector__XXX
 SG_ Joystick6Button2PressedStatus : 44|2@1+ (1,0) [0|3] "" Vector__XXX
 SG_ Joystick6Button3PressedStatus : 42|2@1+ (1,0) [0|3] "" Vector__XXX
 SG_ Joystick6Button4PressedStatus : 40|2@1+ (1,0) [0|3] "" Vector__XXX
 SG_ Joystick6Button5PressedStatus : 54|2@1+ (1,0) [0|3] "" Vector__XXX
 SG_ Joystick6Button6PressedStatus : 52|2@1+ (1,0) [0|3] "" Vector__XXX
 SG_ Joystick6Button7PressedStatus : 50|2@1+ (1,0) [0|3] "" Vector__XXX
 SG_ Joystick6Button8PressedStatus : 48|2@1+ (1,0) [0|3] "" Vector__XXX
 SG_ Joystick6Button9PressedStatus : 62|2@1+ (1,0) [0|3] "" Vector__XXX
 SG_ Joystick6XAxisPosition : 6|10@1+ (0.1,0) [0|102] "%" Vector__XXX
 SG_ Joystick6YAxisPosition : 22|10@1+ (0.1,0) [0|102] "%" Vector__XXX
 SG_ Jstk6XAxsDtntPstnStts : 38|2@1+ (1,0) [0|3] "" Vector__XXX
 SG_ Jstk6XAxsLvrLftNgtvPstnStts : 2|2@1+ (1,0) [0|3] "" Vector__XXX
 SG_ Jstk6XAxsLvrRghtPstvPstnStts : 4|2@1+ (1,0) [0|3] "" Vector__XXX
 SG_ Jstk6XAxsNtrlPstnStts : 0|2@1+ (1,0) [0|3] "" Vector__XXX
 SG_ Jstk6YAxsDtntPstnStts : 36|2@1+ (1,0) [0|3] "" Vector__XXX
 SG_ Jstk6YAxsLvrBkNgtvPstnStts : 18|2@1+ (1,0) [0|3] "" Vector__XXX
 SG_ Jstk6YAxsLvrFrwrdPstvPstnStts : 20|2@1+ (1,0) [0|3] "" Vector__XXX
 SG_ Jstk6YAxsNtrlPstnStts : 16|2@1+ (1,0) [0|3] "" Vector__XXX

BO_ 2365402622 EJM5: 8 Vector__XXX
 SG_ Joystick5Button13PressedStatus : 62|2@1+ (1,0) [0|3] "" Vector__XXX
 SG_ Joystick5Button14PressedStatus : 60|2@1+ (1,0) [0|3] "" Vector__XXX
 SG_ Joystick5Button15PressedStatus : 58|2@1+ (1,0) [0|3] "" Vector__XXX
 SG_ Joystick5Button16PressedStatus : 56|2@1+ (1,0) [0|3] "" Vector__XXX
 SG_ Joystick5GripXAxisPosition : 6|10@1+ (0.1,0) [0|102] "%" Vector__XXX
 SG_ Joystick5GripYAxisPosition : 22|10@1+ (0.1,0) [0|102] "%" Vector__XXX
 SG_ Joystick5ThetaAxisPosition : 38|10@1+ (0.1,0) [0|102] "%" Vector__XXX
 SG_ Jst5GpYAxsLvFwdPstvPstStts : 20|2@1+ (1,0) [0|3] "" Vector__XXX
 SG_ Jst5TtAxsCtCwsNtvPstStts : 34|2@1+ (1,0) [0|3] "" Vector__XXX
 SG_ Jstk5GrpXAxsDtntPstnStts : 54|2@1+ (1,0) [0|3] "" Vector__XXX
 SG_ Jstk5GrpXAxsLvrLftNgtvPstnStts : 2|2@1+ (1,0) [0|3] "" Vector__XXX
 SG_ Jstk5GrpXAxsLvrRghtPstvPstnStts : 4|2@1+ (1,0) [0|3] "" Vector__XXX
 SG_ Jstk5GrpXAxsNtrlPstnStts : 0|2@1+ (1,0) [0|3] "" Vector__XXX
 SG_ Jstk5GrpYAxsDtntPstnStts : 52|2@1+ (1,0) [0|3] "" Vector__XXX
 SG_ Jstk5GrpYAxsLvrBkNgtvPstnStts : 18|2@1+ (1,0) [0|3] "" Vector__XXX
 SG_ Jstk5GrpYAxsNtrlPstnStts : 16|2@1+ (1,0) [0|3] "" Vector__XXX
 SG_ Jstk5ThtAxsClkwsPstvPstnStts : 36|2@1+ (1,0) [0|3] "" Vector__XXX
 SG_ Jstk5ThtAxsDtntPstnStts : 50|2@1+ (1,0) [0|3] "" Vector__XXX
 SG_ Jstk5ThtAxsNtrlPstnStts : 32|2@1+ (1,0) [0|3] "" Vector__XXX

BO_ 2365402878 BJM5: 8 Vector__XXX
 SG_ Joystick5Button10PressedStatus : 60|2@1+ (1,0) [0|3] "" Vector__XXX
 SG_ Joystick5Button11PressedStatus : 58|2@1+ (1,0) [0|3] "" Vector__XXX
 SG_ Joystick5Button12PressedStatus : 56|2@1+ (1,0) [0|3] "" Vector__XXX
 SG_ Joystick5Button1PressedStatus : 46|2@1+ (1,0) [0|3] "" Vector__XXX
 SG_ Joystick5Button2PressedStatus : 44|2@1+ (1,0) [0|3] "" Vector__XXX
 SG_ Joystick5Button3PressedStatus : 42|2@1+ (1,0) [0|3] "" Vector__XXX
 SG_ Joystick5Button4PressedStatus : 40|2@1+ (1,0) [0|3] "" Vector__XXX
 SG_ Joystick5Button5PressedStatus : 54|2@1+ (1,0) [0|3] "" Vector__XXX
 SG_ Joystick5Button6PressedStatus : 52|2@1+ (1,0) [0|3] "" Vector__XXX
 SG_ Joystick5Button7PressedStatus : 50|2@1+ (1,0) [0|3] "" Vector__XXX
 SG_ Joystick5Button8PressedStatus : 48|2@1+ (1,0) [0|3] "" Vector__XXX
 SG_ Joystick5Button9PressedStatus : 62|2@1+ (1,0) [0|3] "" Vector__XXX
 SG_ Joystick5XAxisPosition : 6|10@1+ (0.1,0) [0|102] "%" Vector__XXX
 SG_ Joystick5YAxisPosition : 22|10@1+ (0.1,0) [0|102] "%" Vector__XXX
 SG_ Jstk5XAxsDtntPstnStts : 38|2@1+ (1,0) [0|3] "" Vector__XXX
 SG_ Jstk5XAxsLvrLftNgtvPstnStts : 2|2@1+ (1,0) [0|3] "" Vector__XXX
 SG_ Jstk5XAxsLvrRghtPstvPstnStts : 4|2@1+ (1,0) [0|3] "" Vector__XXX
 SG_ Jstk5XAxsNtrlPstnStts : 0|2@1+ (1,0) [0|3] "" Vector__XXX
 SG_ Jstk5YAxsDtntPstnStts : 36|2@1+ (1,0) [0|3] "" Vector__XXX
 SG_ Jstk5YAxsLvrBkNgtvPstnStts : 18|2@1+ (1,0) [0|3] "" Vector__XXX
 SG_ Jstk5YAxsLvrFrwrdPstvPstnStts : 20|2@1+ (1,0) [0|3] "" Vector__XXX
 SG_ Jstk5YAxsNtrlPstnStts : 16|2@1+ (1,0) [0|3] "" Vector__XXX

BO_ 2365403134 EJM4: 8 Vector__XXX
 SG_ Joystick4Button13PressedStatus : 62|2@1+ (1,0) [0|3] "" Vector__XXX
 SG_ Joystick4Button14PressedStatus : 60|2@1+ (1,0) [0|3] "" Vector__XXX
 SG_ Joystick4Button15PressedStatus : 58|2@1+ (1,0) [0|3] "" Vector__XXX
 SG_ Joystick4Button16PressedStatus : 56|2@1+ (1,0) [0|3] "" Vector__XXX
 SG_ Joystick4GripXAxisPosition : 6|10@1+ (0.1,0) [0|102] "%" Vector__XXX
 SG_ Joystick4GripYAxisPosition : 22|10@1+ (0.1,0) [0|102] "%" Vector__XXX
 SG_ Joystick4ThetaAxisPosition : 38|10@1+ (0.1,0) [0|102] "%" Vector__XXX
 SG_ Jst4GpYAxsLvFwdPstvPstStts : 20|2@1+ (1,0) [0|3] "" Vector__XXX
 SG_ Jst4TtAxsCtCwsNtvPstStts : 34|2@1+ (1,0) [0|3] "" Vector__XXX
 SG_ Jstk4GrpXAxsDtntPstnStts : 54|2@1+ (1,0) [0|3] "" Vector__XXX
 SG_ Jstk4GrpXAxsLvrLftNgtvPstnStts : 2|2@1+ (1,0) [0|3] "" Vector__XXX
 SG_ Jstk4GrpXAxsLvrRghtPstvPstnStts : 4|2@1+ (1,0) [0|3] "" Vector__XXX
 SG_ Jstk4GrpXAxsNtrlPstnStts : 0|2@1+ (1,0) [0|3] "" Vector__XXX
 SG_ Jstk4GrpYAxsDtntPstnStts : 52|2@1+ (1,0) [0|3] "" Vector__XXX
 SG_ Jstk4GrpYAxsLvrBkNgtvPstnStts : 18|2@1+ (1,0) [0|3] "" Vector__XXX
 SG_ Jstk4GrpYAxsNtrlPstnStts : 16|2@1+ (1,0) [0|3] "" Vector__XXX
 SG_ Jstk4ThtAxsClkwsPstvPstnStts : 36|2@1+ (1,0) [0|3] "" Vector__XXX
 SG_ Jstk4ThtAxsDtntPstnStts : 50|2@1+ (1,0) [0|3] "" Vector__XXX
 SG_ Jstk4ThtAxsNtrlPstnStts : 32|2@1+ (1,0) [0|3] "" Vector__XXX

BO_ 2365403390 BJM4: 8 Vector__XXX
 SG_ Joystick4Button10PressedStatus : 60|2@1+ (1,0) [0|3] "" Vector__XXX
 SG_ Joystick4Button11PressedStatus : 58|2@1+ (1,0) [0|3] "" Vector__XXX
 SG_ Joystick4Button12PressedStatus : 56|2@1+ (1,0) [0|3] "" Vector__XXX
 SG_ Joystick4Button1PressedStatus : 46|2@1+ (1,0) [0|3] "" Vector__XXX
 SG_ Joystick4Button2PressedStatus : 44|2@1+ (1,0) [0|3] "" Vector__XXX
 SG_ Joystick4Button3PressedStatus : 42|2@1+ (1,0) [0|3] "" Vector__XXX
 SG_ Joystick4Button4PressedStatus : 40|2@1+ (1,0) [0|3] "" Vector__XXX
 SG_ Joystick4Button5PressedStatus : 54|2@1+ (1,0) [0|3] "" Vector__XXX
 SG_ Joystick4Button6PressedStatus : 52|2@1+ (1,0) [0|3] "" Vector__XXX
 SG_ Joystick4Button7PressedStatus : 50|2@1+ (1,0) [0|3] "" Vector__XXX
 SG_ Joystick4Button8PressedStatus : 48|2@1+ (1,0) [0|3] "" Vector__XXX
 SG_ Joystick4Button9PressedStatus : 62|2@1+ (1,0) [0|3] "" Vector__XXX
 SG_ Joystick4XAxisPosition : 6|10@1+ (0.1,0) [0|102] "%" Vector__XXX
 SG_ Joystick4YAxisPosition : 22|10@1+ (0.1,0) [0|102] "%" Vector__XXX
 SG_ Jstk4XAxsDtntPstnStts : 38|2@1+ (1,0) [0|3] "" Vector__XXX
 SG_ Jstk4XAxsLvrLftNgtvPstnStts : 2|2@1+ (1,0) [0|3] "" Vector__XXX
 SG_ Jstk4XAxsLvrRghtPstvPstnStts : 4|2@1+ (1,0) [0|3] "" Vector__XXX
 SG_ Jstk4XAxsNtrlPstnStts : 0|2@1+ (1,0) [0|3] "" Vector__XXX
 SG_ Jstk4YAxsDtntPstnStts : 36|2@1+ (1,0) [0|3] "" Vector__XXX
 SG_ Jstk4YAxsLvrBkNgtvPstnStts : 18|2@1+ (1,0) [0|3] "" Vector__XXX
 SG_ Jstk4YAxsLvrFrwrdPstvPstnStts : 20|2@1+ (1,0) [0|3] "" Vector__XXX
 SG_ Jstk4YAxsNtrlPstnStts : 16|2@1+ (1,0) [0|3] "" Vector__XXX

BO_ 2365428478 EOI: 8 Vector__XXX
 SG_ EngineControlledShutdownRequest : 42|2@1+ (1,0) [0|3] "" Vector__XXX
 SG_ EngineCoolantPumpControl : 40|2@1+ (1,0) [0|3] "" Vector__XXX
 SG_ EngineDerateRequest : 56|8@1+ (0.4,0) [0|100] "%" Vector__XXX
 SG_ EngineDesiredTorqueRequest : 48|8@1+ (1,-125) [-125|125] "%" Vector__XXX
 SG_ EngineFuelShutoff1Control : 26|2@1+ (1,0) [0|3] "" Vector__XXX
 SG_ EngineFuelShutoff2Control : 28|2@1+ (1,0) [0|3] "" Vector__XXX
 SG_ EngineFuelShutoffVentControl : 24|2@1+ (1,0) [0|3] "" Vector__XXX
 SG_ EngineOilPreheaterControl : 34|2@1+ (1,0) [0|3] "" Vector__XXX
 SG_ EngineOilPrimingPumpControl : 32|2@1+ (1,0) [0|3] "" Vector__XXX
 SG_ EngineOperatingState : 0|4@1+ (1,0) [0|15] "" Vector__XXX
 SG_ EnginePreHeaterControl : 38|2@1+ (1,0) [0|3] "" Vector__XXX
 SG_ EngineStarterMotorRelayControl : 6|2@1+ (1,0) [0|3] "" Vector__XXX
 SG_ EngnCldAmntElvtdIdlStts : 46|2@1+ (1,0) [0|3] "" Vector__XXX
 SG_ EngnEltrlSstmPwrCnsrvtnCntrl : 36|2@1+ (1,0) [0|3] "" Vector__XXX
 SG_ EngnEmrgnImmdtShtdwnIndtn : 44|2@1+ (1,0) [0|3] "" Vector__XXX
 SG_ EngnFlShtffVlvLkTstCntrl : 30|2@1+ (1,0) [0|3] "" Vector__XXX
 SG_ FuelPumpPrimerControl : 4|2@1+ (1,0) [0|3] "" Vector__XXX
 SG_ TmRmnngnEngnOprtngStt : 8|16@1+ (1,0) [0|64255] "s" Vector__XXX

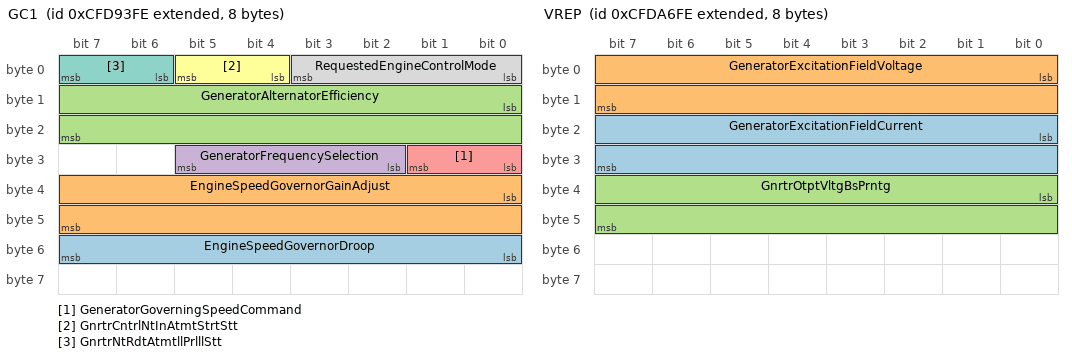
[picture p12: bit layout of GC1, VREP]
BO_ 2365428734 GC1: 8 Vector__XXX
 SG_ EngineSpeedGovernorDroop : 48|8@1+ (0.04,0) [0|10] "%" Vector__XXX
 SG_ EngineSpeedGovernorGainAdjust : 32|16@1+ (1,-32128) [-32128|32127] "count" Vector__XXX
 SG_ GeneratorAlternatorEfficiency : 8|16@1+ (0.0025,0) [0|160.6375] "%" Vector__XXX
 SG_ GeneratorFrequencySelection : 26|4@1+ (1,0) [0|15] "" Vector__XXX
 SG_ GeneratorGoverningSpeedCommand : 24|2@1+ (1,0) [0|3] "" Vector__XXX
 SG_ GnrtrCntrlNtInAtmtStrtStt : 4|2@1+ (1,0) [0|3] "" Vector__XXX
 SG_ GnrtrNtRdtAtmtllPrlllStt : 6|2@1+ (1,0) [0|3] "" Vector__XXX
 SG_ RequestedEngineControlMode : 0|4@1+ (1,0) [0|15] "" Vector__XXX

BO_ 2365433598 VREP: 8 Vector__XXX
 SG_ GeneratorExcitationFieldCurrent : 16|16@1+ (0.05,0) [0|3212.75] "A" Vector__XXX
 SG_ GeneratorExcitationFieldVoltage : 0|16@1+ (0.05,-1606) [-1606|1606.75] "V" Vector__XXX
 SG_ GnrtrOtptVltgBsPrntg : 32|16@1+ (0.1,-3212.75) [-3212.75|3212.75] "%" Vector__XXX

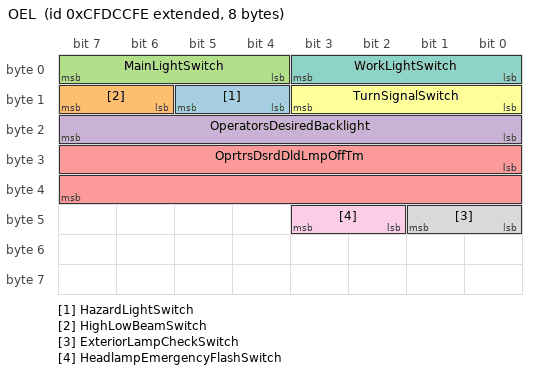
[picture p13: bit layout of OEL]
BO_ 2365443326 OEL: 8 Vector__XXX
 SG_ HazardLightSwitch : 12|2@1+ (1,0) [0|3] "" Vector__XXX
 SG_ HighLowBeamSwitch : 14|2@1+ (1,0) [0|3] "" Vector__XXX
 SG_ MainLightSwitch : 4|4@1+ (1,0) [0|15] "" Vector__XXX
 SG_ OperatorsDesiredBacklight : 16|8@1+ (0.4,0) [0|100] "%" Vector__XXX
 SG_ OprtrsDsrdDldLmpOffTm : 24|16@1+ (1,0) [0|64255] "s" Vector__XXX
 SG_ TurnSignalSwitch : 8|4@1+ (1,0) [0|15] "" Vector__XXX
 SG_ WorkLightSwitch : 0|4@1+ (1,0) [0|15] "" Vector__XXX
 SG_ ExteriorLampCheckSwitch : 40|2@1+ (1,0) [0|3] "" Vector__XXX
 SG_ HeadlampEmergencyFlashSwitch : 42|2@1+ (1,0) [0|3] "" Vector__XXX

BO_ 2365445886 BJM1: 8 Vector__XXX
 SG_ Joystick1Button10PressedStatus : 60|2@1+ (1,0) [0|3] "" Vector__XXX
 SG_ Joystick1Button11PressedStatus : 58|2@1+ (1,0) [0|3] "" Vector__XXX
 SG_ Joystick1Button12PressedStatus : 56|2@1+ (1,0) [0|3] "" Vector__XXX
 SG_ Joystick1Button1PressedStatus : 46|2@1+ (1,0) [0|3] "" Vector__XXX
 SG_ Joystick1Button2PressedStatus : 44|2@1+ (1,0) [0|3] "" Vector__XXX
 SG_ Joystick1Button3PressedStatus : 42|2@1+ (1,0) [0|3] "" Vector__XXX
 SG_ Joystick1Button4PressedStatus : 40|2@1+ (1,0) [0|3] "" Vector__XXX
 SG_ Joystick1Button5PressedStatus : 54|2@1+ (1,0) [0|3] "" Vector__XXX
 SG_ Joystick1Button6PressedStatus : 52|2@1+ (1,0) [0|3] "" Vector__XXX
 SG_ Joystick1Button7PressedStatus : 50|2@1+ (1,0) [0|3] "" Vector__XXX
 SG_ Joystick1Button8PressedStatus : 48|2@1+ (1,0) [0|3] "" Vector__XXX
 SG_ Joystick1Button9PressedStatus : 62|2@1+ (1,0) [0|3] "" Vector__XXX
 SG_ Joystick1XAxisPosition : 6|10@1+ (0.1,0) [0|102] "%" Vector__XXX
 SG_ Joystick1YAxisPosition : 22|10@1+ (0.1,0) [0|102] "%" Vector__XXX
 SG_ Jstk1XAxsDtntPstnStts : 38|2@1+ (1,0) [0|3] "" Vector__XXX
 SG_ Jstk1XAxsLvrLftNgtvPstnStts : 2|2@1+ (1,0) [0|3] "" Vector__XXX
 SG_ Jstk1XAxsLvrRghtPstvPstnStts : 4|2@1+ (1,0) [0|3] "" Vector__XXX
 SG_ Jstk1XAxsNtrlPstnStts : 0|2@1+ (1,0) [0|3] "" Vector__XXX
 SG_ Jstk1YAxsDtntPstnStts : 36|2@1+ (1,0) [0|3] "" Vector__XXX
 SG_ Jstk1YAxsLvrBkNgtvPstnStts : 18|2@1+ (1,0) [0|3] "" Vector__XXX
 SG_ Jstk1YAxsLvrFrwrdPstvPstnStts : 20|2@1+ (1,0) [0|3] "" Vector__XXX
 SG_ Jstk1YAxsNtrlPstnStts : 16|2@1+ (1,0) [0|3] "" Vector__XXX

CM_ BO_ 2365308158 "DC/DC Converter 4 Low Side Limits";
CM_ SG_ 2365308158 DCDC4LwSdCrrntMxmmLmtRqst "DC/DC 4 Low Side Current Maximum Limit Request: The maximum allowed low side current requested by a separate device.   Under normal conditions this requested limit would be reflected in SPN 9039.";
CM_ SG_ 2365308158 DCDC4LwSdVltgMnmmLmtRqst "DC/DC 4 Low Side Voltage Minimum Limit Request: The minimum allowed low side voltage requested by a separate device.  Under normal conditions this requested limit would be reflected in SPN 9037.";
CM_ SG_ 2365308158 DCDC4LwSdVltgMxmmLmtRqst "DC/DC 4 Low Side Voltage Maximum Limit Request: The maximum allowed low side voltage requested by a separate device.   Under normal conditions this requested limit would be reflected in SPN 9038.";
CM_ BO_ 2365308414 "DC/DC Converter 4 High Side Limits";
CM_ SG_ 2365308414 DCDC4HghSdCrrntMxmmLmtRqst "DC/DC 4 High Side Current Maximum Limit Request: The maximum allowed high side current requested by a separate device.   Under normal conditions this requested limit would be reflected in SPN 9036.";
CM_ SG_ 2365308414 DCDC4HghSdVltgMnmmLmtRqst "DC/DC 4 High Side Voltage Minimum Limit Request: The minimum allowed high side voltage requested by a separate device.   Under normal conditions this requested limit would be reflected in SPN 9034.";
CM_ SG_ 2365308414 DCDC4HghSdVltgMxmmLmtRqst "DC/DC 4 High Side Voltage Maximum Limit Request: The maximum allowed high side voltage requested by a separate device.  Under normal conditions this requested limit would be reflected in SPN 9035.";
CM_ BO_ 2365309182 "DC/DC Converter 3 SLI Battery Limits";
CM_ SG_ 2365309182 DCDC3SLIBttrTmprtrMxmmLmtRqst "DC/DC 3 SLI Battery Temperature Maximum Limit Request: The maximum allowed SLI Battery Temperature requested by a separate device.  ";
CM_ SG_ 2365309182 DCDC3SLIBttTCCtMxLtRqst "DC/DC 3 SLI Battery Terminal Charge Current Maximum Limit Request: The maximum allowed SLI Battery charging current (at the battery terminals) requested by a separate device.  ";
CM_ SG_ 2365309182 DCDC3SLIBttTVtMxLtRqst "DC/DC 3 SLI Battery Terminal Voltage Maximum Limit Request: The maximum allowed SLI Battery Voltage (at the battery terminals) requested by a separate system device.  ";
CM_ BO_ 2365309438 "DC/DC Converter 3 Temperatures";
CM_ SG_ 2365309438 DCDC3CnvrtrEltrnFltrTmprtr "DC/DC 3 Converter Electronic Filter Temperature: Parameter indicating the temperature of the electronic components that make up the DC/DC Converter filter.";
CM_ SG_ 2365309438 DCDC3ConverterTemperature "DC/DC 3 Converter Temperature: Parameter indicating the temperature of the DC/DC Converter (e.g, controller, circuit board, enclosure).";
CM_ SG_ 2365309438 DCDC3CoolantInTemperature "DC/DC 3 Coolant  In Temperature: Parameter indicating the temperature of the DC/DC Converter Coolant measured at the input of the converter";
CM_ SG_ 2365309438 DCDC3CoolantOutTemperature "DC/DC 3 Coolant Out Temperature: Parameter indicating the temperature of the DC/DC Converter Coolant measured at the output of the converter";
CM_ SG_ 2365309438 DCDC3PwrEltrnsTmprtr "DC/DC 3 Power Electronics Temperature: Parameter indicating the temperature of the DC/DC Converter power electronics components (e.g, switch or heatsink).";
CM_ BO_ 2365309694 "DC/DC Converter 3 Low Side Limits";
CM_ SG_ 2365309694 DCDC3LwSdCrrntMxmmLmtRqst "DC/DC 3 Low Side Current Maximum Limit Request: The maximum allowed low side current requested by a separate device.   Under normal conditions this requested limit would be reflected in SPN 8984.";
CM_ SG_ 2365309694 DCDC3LwSdVltgMnmmLmtRqst "DC/DC 3 Low Side Voltage Minimum Limit Request: The minimum allowed low side voltage requested by a separate device.   Under normal conditions this requested limit would be reflected in SPN 8982.";
CM_ SG_ 2365309694 DCDC3LwSdVltgMxmmLmtRqst "DC/DC 3 Low Side Voltage Maximum Limit Request: The maximum allowed low side voltage requested by a separate device.   Under normal conditions this requested limit would be reflected in SPN 8983.";
CM_ BO_ 2365309950 "DC/DC Converter 3 High Side Limits";
CM_ SG_ 2365309950 DCDC3HghSdCrrntMxmmLmtRqst "DC/DC 3 High Side Current Maximum Limit Request: The maximum allowed high side current requested by a separate device.   Under normal conditions this requested limit would be reflected in  SPN 8981.";
CM_ SG_ 2365309950 DCDC3HghSdVltgMnmmLmtRqst "DC/DC 3 High Side Voltage Minimum Limit Request: The minimum allowed high side voltage requested by a separate device.   Under normal conditions this requested limit would be reflected in  SPN 8979.";
CM_ SG_ 2365309950 DCDC3HghSdVltgMxmmLmtRqst "DC/DC 3 High Side Voltage Maximum Limit Request: The maximum allowed high side voltage requested by a separate device.   Under normal conditions this requested limit would be reflected in  SPN 8980.";
CM_ BO_ 2365310718 "DC/DC Converter 2 SLI Battery Limits";
CM_ SG_ 2365310718 DCDC2SLIBttrTmprtrMxmmLmtRqst "DC/DC 2 SLI Battery Temperature Maximum Limit Request: The maximum allowed SLI Battery Temperature requested by a separate device.  ";
CM_ SG_ 2365310718 DCDC2SLIBttTCCtMxLtRqst "DC/DC 2 SLI Battery Terminal Charge Current Maximum Limit Request: The maximum allowed SLI Battery charging current (at the battery terminals) requested by a separate device.  ";
CM_ SG_ 2365310718 DCDC2SLIBttTVtMxLtRqst "DC/DC 2 SLI Battery Terminal Voltage Maximum Limit Request: The maximum allowed SLI Battery Voltage (at the battery terminals) requested by a separate system device.  ";
CM_ BO_ 2365310974 "DC/DC Converter 2 Temperatures";
CM_ SG_ 2365310974 DCDC2CnvrtrEltrnFltrTmprtr "DC/DC 2 Converter Electronic Filter Temperature: Parameter indicating the temperature of the electronic components that make up the DC/DC Converter filter.";
CM_ SG_ 2365310974 DCDC2ConverterTemperature "DC/DC 2 Converter Temperature: Parameter indicating the temperature of the DC/DC Converter (e.g, controller, circuit board, enclosure).";
CM_ SG_ 2365310974 DCDC2CoolantInTemperature "DC/DC 2 Coolant  In Temperature: Parameter indicating the temperature of the DC/DC Converter Coolant measured at the input of the converter";
CM_ SG_ 2365310974 DCDC2CoolantOutTemperature "DC/DC 2 Coolant Out Temperature: Parameter indicating the temperature of the DC/DC Converter Coolant measured at the output of the converter";
CM_ SG_ 2365310974 DCDC2PwrEltrnsTmprtr "DC/DC 2 Power Electronics Temperature: Parameter indicating the temperature of the DC/DC Converter power electronics components (e.g, switch or heatsink).";
CM_ BO_ 2365311230 "DC/DC Converter 2 Low Side Limits";
CM_ SG_ 2365311230 DCDC2LwSdCrrntMxmmLmtRqst "DC/DC 2 Low Side Current Maximum Limit Request: The maximum allowed low side current requested by a separate device.  Under normal conditions this requested limit would be reflected in SPN 8929.";
CM_ SG_ 2365311230 DCDC2LwSdVltgMnmmLmtRqst "DC/DC 2 Low Side Voltage Minimum Limit Request: The minimum allowed low side voltage requested by a separate device.  Under normal conditions this requested limit would be reflected in SPN 8927.";
CM_ SG_ 2365311230 DCDC2LwSdVltgMxmmLmtRqst "DC/DC 2 Low Side Voltage Maximum Limit Request: The maximum allowed low side voltage requested by a separate device.  Under normal conditions this requested limit would be reflected in SPN 8928.";
CM_ BO_ 2365311486 "DC/DC Converter 2 High Side Limits";
CM_ SG_ 2365311486 DCDC2HghSdCrrntMxmmLmtRqst "DC/DC 2 High Side Current Maximum Limit Request: The maximum allowed high side current requested by a separate device. Under normal conditions this requested limit would be reflected in SPN 8926.";
CM_ SG_ 2365311486 DCDC2HghSdVltgMnmmLmtRqst "DC/DC 2 High Side Voltage Minimum Limit Request: The minimum allowed high side voltage requested by a separate device. Under normal conditions this requested limit would be reflected in SPN 8924.";
CM_ SG_ 2365311486 DCDC2HghSdVltgMxmmLmtRqst "DC/DC 2 High Side Voltage Maximum Limit Request: The maximum allowed high side voltage requested by a separate device.  Under normal conditions this requested limit would be reflected in SPN 8925.";
CM_ BO_ 2365313534 "DC/DC Converter 1 SLI Battery Limits";
CM_ SG_ 2365313534 DCDC1SLIBttrTmprtrMxmmLmtRqst "DC/DC 1 SLI Battery Temperature Maximum Limit Request: The maximum allowed SLI Battery Temperature requested by a separate device.  ";
CM_ SG_ 2365313534 DCDC1SLIBttTCCtMxLtRqst "DC/DC 1 SLI Battery Terminal Charge Current Maximum Limit Request: The maximum allowed SLI Battery charging current (at the battery terminals) requested by a separate device.  ";
CM_ SG_ 2365313534 DCDC1SLIBttTVtMxLtRqst "DC/DC 1 SLI Battery Terminal Voltage Maximum Limit Request: The maximum allowed SLI Battery Voltage (at the battery terminals) requested by a separate system device.  ";
CM_ BO_ 2365315326 "DC/DC Converter 1 Temperatures";
CM_ SG_ 2365315326 DCDC1CnvrtrEltrnFltrTmprtr "DC/DC 1 Converter Electronic Filter Temperature: Parameter indicating the temperature of the electronic components that make up the DC/DC Converter filter.";
CM_ SG_ 2365315326 DCDC1ConverterTemperature "DC/DC 1 Converter Temperature: Parameter indicating the temperature of the DC/DC Converter (e.g, controller, circuit board, enclosure).";
CM_ SG_ 2365315326 DCDC1CoolantInTemperature "DC/DC 1 Coolant  In Temperature: Parameter indicating the temperature of the DC/DC Converter Coolant measured at the input of the converter";
CM_ SG_ 2365315326 DCDC1CoolantOutTemperature "DC/DC 1 Coolant Out Temperature: Parameter indicating the temperature of the DC/DC Converter Coolant measured at the output of the converter";
CM_ SG_ 2365315326 DCDC1PwrEltrnsTmprtr "DC/DC 1 Power Electronics Temperature: Parameter indicating the temperature of the DC/DC Converter power electronics components (e.g, switch or heatsink).";
CM_ BO_ 2365315582 "DC/DC Converter 1 Low Side Limits";
CM_ SG_ 2365315582 DCDC1LwSdCrrntMxmmLmtRqst "DC/DC 1 Low Side Current Maximum Limit Request: The maximum allowed low side current requested by a separate device.   Under normal conditions this requested limit would be reflected in SPN 8829.";
CM_ SG_ 2365315582 DCDC1LwSdVltgMnmmLmtRqst "DC/DC 1 Low Side Voltage Minimum Limit Request: The minimum allowed low side voltage requested by a separate device.   Under normal conditions this requested limit would be reflected in SPN 8827.";
CM_ SG_ 2365315582 DCDC1LwSdVltgMxmmLmtRqst "DC/DC 1 Low Side Voltage Maximum Limit Request: The maximum allowed low side voltage requested by a separate device.   Under normal conditions this requested limit would be reflected in SPN 8828.";
CM_ BO_ 2365315838 "DC/DC Converter 1 High Side Limits";
CM_ SG_ 2365315838 DCDC1HghSdCrrntMxmmLmtRqst "DC/DC 1 High Side Current Maximum Limit Request: The maximum allowed high side current requested by a separate device.   Under normal conditions this requested limit would be reflected in SPN 8826.";
CM_ SG_ 2365315838 DCDC1HghSdVltgMnmmLmtRqst "DC/DC 1 High Side Voltage Minimum Limit Request: The minimum allowed high side voltage requested by a separate device.   Under normal conditions this requested limit would be reflected in SPN 8824.";
CM_ SG_ 2365315838 DCDC1HghSdVltgMxmmLmtRqst "DC/DC 1 High Side Voltage Maximum Limit Request: The maximum allowed high side voltage requested by a separate device.   Under normal conditions this requested limit would be reflected in SPN 8825.";
CM_ BO_ 2365318910 "High Voltage Energy Storage System Fan Commands";
CM_ SG_ 2365318910 HVESSFanEnableCommand "HVESS Fan Enable Command: Enable and direction command to this HVES fan.00b = Fan Off01b = Fan On Normal/Default Direction10b = Fan On Reverse Direction11b = Don't Care/Take no action";
CM_ SG_ 2365318910 HVESSFanPowerHold "HVESS Fan Power Hold: Command to allow this HVES fan to remain alive independently of the electrical enable input to the fan.  For example, this could allow continued device operation after the keyswitch has turned off.00b = Power Hold Disabled01b = ...";
CM_ SG_ 2365318910 HVESSFanSpeedCommand "HVESS Fan Speed Command: Speed command to this HVES fan.Note: Both SPN 8386 (HVESS Fan Speed Command) and SPN 8387 (HVESS Fan Percent Speed Command) cannot be used at the same time.  Always set the unused speed command to Not Available.  If both comm...";
CM_ SG_ 2365318910 HVESSFanPercentSpeedCommand "HVESS Fan Percent Speed Command: Speed command to this HVES fan in percentage of maximum speed.Note: Both SPN 8386 (HVESS Fan Speed Command) and SPN 8387 (HVESS Fan Percent Speed Command) cannot be used at the same time.  Always set the unused speed ...";
CM_ SG_ 2365318910 HVESSFanInstance1 "HVESS Fan Instance 1: Indicates the HVES Fan Instance that is being commanded.  Multiple instances can be controlled with the same command PG by setting each unique instance parameter to 0b.0b = Command applied to this Fan Instance1b = No Command app...";
CM_ SG_ 2365318910 HVESSFanInstance2 "HVESS Fan Instance 2: Indicates the HVES Fan Instance that is being commanded.  Multiple instances can be controlled with the same command PG by setting each unique instance parameter to 0b.0b = Command applied to this Fan Instance1b = No Command app...";
CM_ SG_ 2365318910 HVESSFanInstance3 "HVESS Fan Instance 3: Indicates the HVES Fan Instance that is being commanded.  Multiple instances can be controlled with the same command PG by setting each unique instance parameter to 0b.0b = Command applied to this Fan Instance1b = No Command app...";
CM_ SG_ 2365318910 HVESSFanInstance4 "HVESS Fan Instance 4: Indicates the HVES Fan Instance that is being commanded.  Multiple instances can be controlled with the same command PG by setting each unique instance parameter to 0b.0b = Command applied to this Fan Instance1b = No Command app...";
CM_ SG_ 2365318910 HVESSFanInstance5 "HVESS Fan Instance 5: Indicates the HVES Fan Instance that is being commanded.  Multiple instances can be controlled with the same command PG by setting each unique instance parameter to 0b.0b = Command applied to this Fan Instance1b = No Command app...";
CM_ SG_ 2365318910 HVESSFanInstance6 "HVESS Fan Instance 6: Indicates the HVES Fan Instance that is being commanded.  Multiple instances can be controlled with the same command PG by setting each unique instance parameter to 0b.0b = Command applied to this Fan Instance1b = No Command app...";
CM_ SG_ 2365318910 HVESSFanInstance7 "HVESS Fan Instance 7: Indicates the HVES Fan Instance that is being commanded.  Multiple instances can be controlled with the same command PG by setting each unique instance parameter to 0b.0b = Command applied to this Fan Instance1b = No Command app...";
CM_ SG_ 2365318910 HVESSFanInstance8 "HVESS Fan Instance 8: Indicates the HVES Fan Instance that is being commanded.  Multiple instances can be controlled with the same command PG by setting each unique instance parameter to 0b.0b = Command applied to this Fan Instance1b = No Command app...";
CM_ SG_ 2365318910 HVESSFanInstance9 "HVESS Fan Instance 9: Indicates the HVES Fan Instance that is being commanded.  Multiple instances can be controlled with the same command PG by setting each unique instance parameter to 0b.0b = Command applied to this Fan Instance1b = No Command app...";
CM_ SG_ 2365318910 HVESSFanInstance10 "HVESS Fan Instance 10: Indicates the HVES Fan Instance that is being commanded.  Multiple instances can be controlled with the same command PG by setting each unique instance parameter to 0b.0b = Command applied to this Fan Instance1b = No Command ap...";
CM_ SG_ 2365318910 HVESSFanInstance11 "HVESS Fan Instance 11: Indicates the HVES Fan Instance that is being commanded.  Multiple instances can be controlled with the same command PG by setting each unique instance parameter to 0b.0b = Command applied to this Fan Instance1b = No Command ap...";
CM_ SG_ 2365318910 HVESSFanInstance12 "HVESS Fan Instance 12: Indicates the HVES Fan Instance that is being commanded.  Multiple instances can be controlled with the same command PG by setting each unique instance parameter to 0b.0b = Command applied to this Fan Instance1b = No Command ap...";
CM_ SG_ 2365318910 HVESSFanInstance13 "HVESS Fan Instance 13: Indicates the HVES Fan Instance that is being commanded.  Multiple instances can be controlled with the same command PG by setting each unique instance parameter to 0b.0b = Command applied to this Fan Instance1b = No Command ap...";
CM_ SG_ 2365318910 HVESSFanInstance14 "HVESS Fan Instance 14: Indicates the HVES Fan Instance that is being commanded.  Multiple instances can be controlled with the same command PG by setting each unique instance parameter to 0b.0b = Command applied to this Fan Instance1b = No Command ap...";
CM_ SG_ 2365318910 HVESSFanInstance15 "HVESS Fan Instance 15: Indicates the HVES Fan Instance that is being commanded.  Multiple instances can be controlled with the same command PG by setting each unique instance parameter to 0b.0b = Command applied to this Fan Instance1b = No Command ap...";
CM_ BO_ 2365322238 "Cruise Control / Vehicle Speed 5";
CM_ SG_ 2365322238 DirectionalVehicleSpeed "Directional Vehicle Speed: The velocity and direction of the vehicle. Positive values are used for forward vehicle motion, negative values for reverse vehicle motion.  This SP is intended for control purposes where vehicle direction is required.  It ...";
CM_ BO_ 2365346302 "Air Suspension Control 7";
CM_ SG_ 2365346302 LiftAxle1Status "Lift Axle 1 Status: Indicates the status of a tag axle 1.  Numbering of lift/tag axles starts at front axle.  SPN 1743 may be used if less detail is acceptable.000b = Down (tag axle is laden)001b = Unloading (load is being transferred from the tag ax...";
CM_ SG_ 2365346302 LiftAxle2Status "Lift Axle 2 Status: Indicates the status of a tag axle 2.  Numbering of lift/tag axles starts at front axle.  SPN 1822 may be used if less detail is acceptable.000b = Down (tag axle is laden)001b = Unloading (load is being transferred from the tag ax...";
CM_ SG_ 2365346302 LiftAxle3Status "Lift Axle 3 Status: Indicates the status of a tag axle 3. Numbering of lift/tag axles starts at front axle.000b = Down (tag axle is laden)001b = Unloading (load is being transferred from the tag axle)010b = Lifting (tag axle is moving up)011b = Up (t...";
CM_ SG_ 2365346302 LiftAxle4Status "Lift Axle 4 Status: Indicates the status of a tag axle 4. Numbering of lift/tag axles starts at front axle.000b = Down (tag axle is laden)001b = Unloading (load is being transferred from the tag axle)010b = Lifting (tag axle is moving up)011b = Up (t...";
CM_ BO_ 2365348350 "Engine Load Sharing Information";
CM_ SG_ 2365348350 EngineLoadShareStatus "Engine Load Share Status: This signal indicates that the status of an engine load sharing feature.0000b = Offline0001b = Master0010b = Slave0011b = Loading0100b = Unloading0101b to 1101b = Reserved1110b = Error1111b = Unavailable";
CM_ SG_ 2365348350 EngineUnloadStatus "Engine Unload Status: This signal indicates the status of an external request to unload the engine, such as the external unload request switch.00b = Not Requested01b = Requested10b = Error11b = Not Available";
CM_ BO_ 2365363710 "Engine Cylinder Pressure Monitor Status Information";
CM_ SG_ 2365363710 EngnClndrPrssrMntr1PrlmnrFMI "Engine Cylinder Pressure Monitor 1 Preliminary FMI: Used to identify the applicable J1939-73 FMI detected in the Engine Cylinder Pressure Monitor 1. In the case of multiple failures the most severe is communicated.A value of 31 is sent to indicate th...";
CM_ SG_ 2365363710 EngnClndrPrssrMntr2PrlmnrFMI "Engine Cylinder Pressure Monitor 2 Preliminary FMI: Used to identify the applicable J1939-73 FMI detected in the Engine Cylinder Pressure Monitor 2.  In the case of multiple failures the most severe is communicated.A value of 31 is sent to indicate t...";
CM_ BO_ 2365374206 "Electronic Transmission Controller #9";
CM_ SG_ 2365374206 DlClthTrnsmssnCrrntPrsltnGr "Dual Clutch Transmission Current Pre-selection Gear: The gear currently engaged on the non-engaged clutch of a dual clutch transmission (DCT) or the last gear engaged on the non-engaged clutch while the transmission is in the process of pre-selecting...";
CM_ SG_ 2365374206 DlClthTrnsmssnInptShft1Spd "Dual Clutch Transmission Input Shaft 1 Speed: Rotational velocity of the primary shaft transferring power through clutch 1 into the dual clutch transmission (DCT).";
CM_ SG_ 2365374206 DlClthTrnsmssnInptShft2Spd "Dual Clutch Transmission Input Shaft 2 Speed: Rotational velocity of the primary shaft transferring power through clutch 2 into the dual clutch transmission (DCT).";
CM_ SG_ 2365374206 DlClthTrnsmssnSltdPrsltnGr "Dual Clutch Transmission Selected Pre-selection Gear: The gear that the transmission will attempt to achieve during the current pre-selection event (shifting to a new gear on the non-engaged clutch of a dual clutch transmission (DCT)).";
CM_ BO_ 2365393662 "Aftertreatment 2 Outlet Gas NOx Sensor Correction Data 2";
CM_ SG_ 2365393662 Aftrtrtmnt2OtltCrrtdNOx "Aftertreatment 2 Outlet Corrected NOx: The corrected outlet NOx value  for aftertreatment 2 shall include all learned adaptions and offsets that are used to adjust the raw signal.2016 MY and later engines with NOx sensors may be required to output a ...";
CM_ SG_ 2365393662 Aftrtrtmnt2OtltNOxSnsrNH3Crrtn "Aftertreatment 2 Outlet NOx Sensor NH3 Correction: Correction of NH3 at the NOx-signal to correct (recalculate) sensor signal on the Engine ECU side.";
CM_ SG_ 2365393662 Aftrtrtmnt2OtltNOxSnsrNO2Crrtn "Aftertreatment 2 Outlet NOx Sensor NO2 Correction: Correction of NO2 at the NOx-signal to correct (recalculate) sensor signal on the Engine ECU side.";
CM_ SG_ 2365393662 Atttt2OttNOxSsNOxPssCt "Aftertreatment 2 Outlet NOx Sensor NOx Pressure Correction: Correction of pressure NOx-signal to correct (recalculate) sensor signal on the Engine ECU side.";
CM_ SG_ 2365393662 Atttt2OttNOxSsO2PssCt "Aftertreatment 2 Outlet NOx Sensor O2 Pressure Correction: Correction of pressure Lambda-signal to correct (recalculate) sensor signal on the Engine ECU side.";
CM_ SG_ 2365393662 Atttt2OttNOxSsSdssFRst "Aftertreatment 2 Outlet NOx Sensor Self-diagnosis Final Result: Self-diagnosis result for NOx sensor ATO2 (Aftertreatment Outlet Bank 2) as a ratio of detected value to reference value defined by supplier.This result is used to determine if the signa...";
CM_ BO_ 2365393918 "Aftertreatment 2 Outlet Gas NOx Sensor Correction Data 1";
CM_ SG_ 2365393918 Aftrtrtmnt2OtltNOxSnsrHtrRt "Aftertreatment 2 Outlet NOx Sensor Heater Ratio: Heater ratio to determine temperature at sensor tip.";
CM_ SG_ 2365393918 Aftrtrtmnt2OtltNOxSnsrOprtnHrs "Aftertreatment 2 Outlet NOx Sensor Operation Hours: Counted hours that the NOx-sensor was operated with status dewpoint reached";
CM_ SG_ 2365393918 Atttt2OttNOxSsNwptdvtNOxG "Aftertreatment 2 Outlet NOx Sensor New part deviation NOx Gain: New part deviation NOx_Gain to correct (recalculate) sensor signal on the Engine ECU side.";
CM_ SG_ 2365393918 Atttt2OttNOxSsNwptdvtNOxOst "Aftertreatment 2 Outlet NOx Sensor New part deviation NOx Offset: New part deviation NOx_Offset to correct (recalculate) sensor signal on the Engine ECU side.";
CM_ BO_ 2365394174 "Aftertreatment 2 Intake Gas NOx Sensor Correction Data 2";
CM_ SG_ 2365394174 EngineExhaust2CorrectedNox "Engine Exhaust 2 Corrected Nox: The corrected intake Selective Catalytic Reduction NOx value for aftertreatment 2 shall include all learned adaptions and offsets that are used to adjust the raw signal.  This sensor is located at the intake of the SCR...";
CM_ SG_ 2365394174 EngnExhst2NOxSnsrO2PrssrCrrtn "Engine Exhaust 2 NOx Sensor O2 Pressure Correction: Correction of pressure Lambda-signal to correct (recalculate) sensor signal on the Engine ECU side.  This sensor is located at the intake of the aftertreatment system if an aftertreatment system exi...";
CM_ SG_ 2365394174 EngnExhst2NOxSnsrNOxPrssrCrrtn "Engine Exhaust 2 NOx Sensor NOx Pressure Correction: Correction of pressure NOx-signal to correct (recalculate) sensor signal on the Engine ECU side.  This sensor is located at the intake of the aftertreatment system if an aftertreatment system exist...";
CM_ SG_ 2365394174 EngnExhst2NOxSnsrNO2Crrtn "Engine Exhaust 2 NOx Sensor NO2 Correction: Correction of NO2 at the NOx-signal to correct (recalculate) sensor signal on the Engine ECU side.  This sensor is located at the intake of the aftertreatment system if an aftertreatment system exists.";
CM_ SG_ 2365394174 EngnExhst2NOxSnsrNH3Crrtn "Engine Exhaust 2 NOx Sensor NH3 Correction: Correction of NH3 at the NOx-signal to correct (recalculate) sensor signal on the Engine ECU side.  This sensor is located at the intake of the aftertreatment system if an aftertreatment system exists.";
CM_ SG_ 2365394174 EExst2NOxSsSdssFRst "Engine Exhaust 2 NOx Sensor Self-diagnosis Final Result: Self-diagnosis result for NOx sensor Engine Exhaust Bank 2 (EEB2) as a ratio of detected value to reference value defined by supplier.  This sensor is located at the intake of the aftertreatmen...";
CM_ BO_ 2365394430 "Aftertreatment 2 Intake Gas NOx Sensor Correction Data 1";
CM_ SG_ 2365394430 EngnExhst2NOxSnsrHtrRt "Engine Exhaust 2 NOx Sensor Heater Ratio: Heater ratio to determine temperature at sensor tip.  This sensor is located at the intake of the aftertreatment system if an aftertreatment system exists.";
CM_ SG_ 2365394430 EngnExhst2NOxSnsrNwPrtDvtnNOxGn "Engine Exhaust 2 NOx Sensor New Part Deviation NOx Gain: New part deviation NOx_Gain to correct (recalculate) sensor signal on the Engine ECU side.  This sensor is located at the intake of the aftertreatment system if an aftertreatment system exists.";
CM_ SG_ 2365394430 EExst2NOxSsNwPtDvtNOxOst "Engine Exhaust 2 NOx Sensor New Part Deviation NOx Offset: New part deviation NOx_Offset to correct (recalculate) sensor signal on the Engine ECU side.  This sensor is located at the intake of the aftertreatment system if an aftertreatment system exi...";
CM_ SG_ 2365394430 EngnExhst2NOxSnsrOprtnHrs "Engine Exhaust 2 NOx Sensor Operation Hours: Counted hours that the NOx-sensor was operated with status dewpoint reached.  This sensor is located at the intake of the aftertreatment system if an aftertreatment system exists.";
CM_ BO_ 2365394686 "Aftertreatment 1 Outlet Gas NOx Sensor Correction Data 2";
CM_ SG_ 2365394686 Aftrtrtmnt1OtltCrrtdNOx "Aftertreatment 1 Outlet Corrected NOx: The corrected outlet NOx value for aftertreatment 1 shall include all learned adaptions and offsets that are used to adjust the raw signal.2016 MY and later engines with NOx sensors may be required to output a '...";
CM_ SG_ 2365394686 Aftrtrtmnt1OtltNOxSnsrNH3Crrtn "Aftertreatment 1 Outlet NOx Sensor NH3 Correction: Correction of NH3 at the NOx-signal to correct (recalculate) sensor signal on the Engine ECU side.";
CM_ SG_ 2365394686 Aftrtrtmnt1OtltNOxSnsrNO2Crrtn "Aftertreatment 1 Outlet NOx Sensor NO2 Correction: Correction of NO2 at the NOx-signal to correct (recalculate) sensor signal on the Engine ECU side.";
CM_ SG_ 2365394686 Atttt1OttNOxSsNOxPssCt "Aftertreatment 1 Outlet NOx Sensor NOx Pressure Correction: Correction of pressure NOx-signal to correct (recalculate) sensor signal on the Engine ECU side.";
CM_ SG_ 2365394686 Atttt1OttNOxSsO2PssCt "Aftertreatment 1 Outlet NOx Sensor O2 Pressure Correction: Correction of pressure Lambda-signal to correct (recalculate) sensor signal on the Engine ECU side.";
CM_ SG_ 2365394686 Atttt1OttNOxSsSdssFRst "Aftertreatment 1 Outlet NOx Sensor Self-diagnosis Final Result: Self-diagnosis result for NOx sensor ATO1 (Aftertreatment Outlet Bank 1) as a ratio of detected value to reference value defined by supplier.This result is used to determine if the signa...";
CM_ BO_ 2365394942 "Aftertreatment 1 Outlet Gas NOx Sensor Correction Data 1";
CM_ SG_ 2365394942 Aftrtrtmnt1OtltNOxSnsrHtrRt "Aftertreatment 1 Outlet NOx Sensor Heater Ratio: Heater ratio to determine temperature at sensor tip.";
CM_ SG_ 2365394942 Aftrtrtmnt1OtltNOxSnsrOprtnHrs "Aftertreatment 1 Outlet NOx Sensor Operation Hours: Counted hours that the NOx-sensor was operated with status dewpoint reached";
CM_ SG_ 2365394942 Atttt1OttNOxSsNwptdvtNOxG "Aftertreatment 1 Outlet NOx Sensor New part deviation NOx Gain: New part deviation NOx_Gain to correct (recalculate) sensor signal on the Engine ECU side.";
CM_ SG_ 2365394942 Atttt1OttNOxSsNwptdvtNOxOst "Aftertreatment 1 Outlet NOx Sensor New part deviation NOx Offset: New part deviation NOx_Offset to correct (recalculate) sensor signal on the Engine ECU side.";
CM_ BO_ 2365395198 "Aftertreatment 1 Intake Gas NOx Sensor Correction Data 2";
CM_ SG_ 2365395198 EExst1NOxSsSdssFRst "Engine Exhaust 1 NOx Sensor Self-diagnosis Final Result: Self-diagnosis result for NOx sensor Engine Exhaust Bank 1 (EEB1) as a ratio of detected value to reference value defined by supplier.  This sensor is located at the intake of the aftertreatmen...";
CM_ SG_ 2365395198 EngineExhaust1CorrectedNox "Engine Exhaust 1 Corrected Nox: The corrected NOx value for exhaust bank 1 shall include all learned adaptions and offsets that are used to adjust the raw signal.  This sensor is located at the intake of the SCR system if an SCR system exists. 2016 M...";
CM_ SG_ 2365395198 EngnExhst1NOxSnsrNH3Crrtn "Engine Exhaust 1 NOx Sensor NH3 Correction: Correction of NH3 at the NOx-signal to correct (recalculate) sensor signal on the Engine ECU side.  This sensor is located at the intake of the aftertreatment system if an aftertreatment system exists.";
CM_ SG_ 2365395198 EngnExhst1NOxSnsrNO2Crrtn "Engine Exhaust 1 NOx Sensor NO2 Correction: Correction of NO2 at the NOx-signal to correct (recalculate) sensor signal on the Engine ECU side.  This sensor is located at the intake of the aftertreatment system if an aftertreatment system exists.";
CM_ SG_ 2365395198 EngnExhst1NOxSnsrNOxPrssrCrrtn "Engine Exhaust 1 NOx Sensor NOx Pressure Correction: Correction of pressure NOx-signal to correct (recalculate) sensor signal on the Engine ECU side.  This sensor is located at the intake of the aftertreatment system if an aftertreatment system exist...";
CM_ SG_ 2365395198 EngnExhst1NOxSnsrO2PrssrCrrtn "Engine Exhaust 1 NOx Sensor O2 Pressure Correction: Correction of pressure Lambda-signal to correct (recalculate) sensor signal on the Engine ECU side.  This sensor is located at the intake of the aftertreatment system if an aftertreatment system exi...";
CM_ BO_ 2365395454 "Aftertreatment 1 Intake Gas NOx Sensor Correction Data 1";
CM_ SG_ 2365395454 EExst1NOxSsNwptdvtNOxOst "Engine Exhaust 1 NOx Sensor New part deviation NOx Offset: New part deviation NOx_Offset to correct (recalculate) sensor signal on the Engine ECU side.  This sensor is located at the intake of the aftertreatment system if an aftertreatment system exi...";
CM_ SG_ 2365395454 EngnExhst1NOxSnsrHtrRt "Engine Exhaust 1 NOx Sensor Heater Ratio: Heater ratio to determine temperature at sensor tip.  This sensor is located at the intake of the aftertreatment system if an aftertreatment system exists.";
CM_ SG_ 2365395454 EngnExhst1NOxSnsrNwprtdvtnNOxGn "Engine Exhaust 1 NOx Sensor New part deviation NOx Gain: New part deviation NOx_Gain to correct (recalculate) sensor signal on the Engine ECU side.  This sensor is located at the intake of the aftertreatment system if an aftertreatment system exists.";
CM_ SG_ 2365395454 EngnExhst1NOxSnsrOprtnHrs "Engine Exhaust 1 NOx Sensor Operation Hours: Counted hours that the NOx-sensor was operated with status dewpoint reached.  This sensor is located at the intake of the aftertreatment system if an aftertreatment system exists.";
CM_ BO_ 2365400062 "Extended Joystick Message 10";
CM_ SG_ 2365400062 Joystick10Button13PressedStatus "Joystick 10 Button 13 Pressed Status: Reports when the joystick button has been pressed.00b = Button not pressed01b = Button pressed10b = Error Indicator11b = Not Available";
CM_ SG_ 2365400062 Joystick10Button14PressedStatus "Joystick 10 Button 14 Pressed Status: Reports when the joystick button has been pressed.00b = Button not pressed01b = Button pressed10b = Error Indicator11b = Not Available";
CM_ SG_ 2365400062 Joystick10Button15PressedStatus "Joystick 10 Button 15 Pressed Status: Reports when the joystick button has been pressed.00b = Button not pressed01b = Button pressed10b = Error Indicator11b = Not Available";
CM_ SG_ 2365400062 Joystick10Button16PressedStatus "Joystick 10 Button 16 Pressed Status: Reports when the joystick button has been pressed.00b = Button not pressed01b = Button pressed10b = Error Indicator11b = Not Available";
CM_ SG_ 2365400062 Joystick10GripXAxisPosition "Joystick 10 Grip X-Axis Position: The position of the joystick grip in the relative motion of travel from the neutral position.  Position value of 0 is Neutral and position value 1000 (100%) is the end of linear zone.  Value of 1022 indicates an erro...";
CM_ SG_ 2365400062 Joystick10GripYAxisPosition "Joystick 10 Grip Y-Axis Position: The position of the joystick grip in the relative motion of travel from the neutral position.  Position value of 0 is Neutral and position value 1000 (100%) is the end of linear zone.  Value of 1022 indicates an erro...";
CM_ SG_ 2365400062 Joystick10ThetaAxisPosition "Joystick 10 Theta-Axis Position: The position of the joystick in the relative motion of travel from the neutral position.  Position value of 0 is Neutral and position value 1000 (100%) is the end of linear zone.  Value of 1022 indicates an error has ...";
CM_ SG_ 2365400062 Jst10GpXAxsLvRtPstvPstStts "Joystick 10 Grip X-Axis Lever Right Positive Position Status: Reports when the current joystick grip position is on the positive travel side (forward, right, clockwise, up) relative to the neutral position for that axis of travel. 00b = Not on Positi...";
CM_ SG_ 2365400062 Jst10GpYAxsLvFwdPstvPstStts "Joystick 10 Grip Y-Axis Lever Forward Positive Position Status: Reports when the current joystick grip position is on the positive travel side (forward, right, clockwise, up) relative to the neutral position for that axis of travel. 00b = Not on Posi...";
CM_ SG_ 2365400062 Jst10TtAxsCtCwsNtvPstStts "Joystick 10 Theta-Axis Counter Clockwise Negative Position Status: Reports when the current joystick position is on the negative travel side (back, left, counterclockwise, down) relative to the neutral position for that axis of travel. 00b = Not on n...";
CM_ SG_ 2365400062 Jstk10GrpXAxsDtntPstnStts "Joystick 10 Grip X-Axis Detent Position Status: Reports when the current joystick grip position is in the detent position for that axis of travel.00b = Not in the Detent Position01b = In the Detent Position10b = Error Indicator11b = Not Available...";
CM_ SG_ 2365400062 Jstk10GrpXAxsLvrLftNgtvPstnStts "Joystick 10 Grip X-Axis Lever Left Negative Position Status: Reports when the current joystick grip position is on the negative travel side (back, left, counterclockwise, down) relative to the neutral position for that axis of travel. 00b = Not on ne...";
CM_ SG_ 2365400062 Jstk10GrpXAxsNtrlPstnStts "Joystick 10 Grip X-Axis Neutral Position Status: Reports when the current joystick grip position is in the neutral position for that axis of travel.  The neutral position measurement must be determined from some mechanism other than the axis position...";
CM_ SG_ 2365400062 Jstk10GrpYAxsDtntPstnStts "Joystick 10 Grip Y-Axis Detent Position Status: Reports when the current joystick grip position is in the detent position for that axis of travel.00b = Not in the Detent Position01b = In the Detent Position10b = Error Indicator11b = Not Available...";
CM_ SG_ 2365400062 Jstk10GrpYAxsLvrBkNgtvPstnStts "Joystick 10 Grip Y-Axis Lever Back Negative Position Status: Reports when the current joystick grip position is on the negative travel side (back, left, counterclockwise, down) relative to the neutral position for that axis of travel. 00b = Not on ne...";
CM_ SG_ 2365400062 Jstk10GrpYAxsNtrlPstnStts "Joystick 10 Grip Y-Axis Neutral Position Status: Reports when the current joystick grip position is in the neutral position for that axis of travel.  The neutral position measurement must be determined from some mechanism other than the axis position...";
CM_ SG_ 2365400062 Jstk10ThtAxsClkwsPstvPstnStts "Joystick 10 Theta-Axis Clockwise Positive Position Status: Reports when the current joystick position is on the positive travel side (forward, right, clockwise, up) relative to the neutral position for that axis of travel. 00b = Not on Positive side ...";
CM_ SG_ 2365400062 Jstk10ThtAxsDtntPstnStts "Joystick 10 Theta-Axis Detent Position Status: Reports when the current joystick position is in the detent position for that axis of travel.00b = Not in the Detent Position01b = In the Detent Position10b = Error Indicator11b = Not Available";
CM_ SG_ 2365400062 Jstk10ThtAxsNtrlPstnStts "Joystick 10 Theta-Axis Neutral Position Status: Reports when the current joystick position is in the neutral position for that axis of travel.  The neutral position measurement must be determined from some mechanism other than the axis position measu...";
CM_ BO_ 2365400318 "Basic Joystick Message 10";
CM_ SG_ 2365400318 Joystick10Button10PressedStatus "Joystick 10 Button 10 Pressed Status: Reports when the joystick button has been pressed.00b = Button not pressed01b = Button pressed10b = Error Indicator11b = Not Available";
CM_ SG_ 2365400318 Joystick10Button11PressedStatus "Joystick 10 Button 11 Pressed Status: Reports when the joystick button has been pressed.00b = Button not pressed01b = Button pressed10b = Error Indicator11b = Not Available";
CM_ SG_ 2365400318 Joystick10Button12PressedStatus "Joystick 10 Button 12 Pressed Status: Reports when the joystick button has been pressed.00b = Button not pressed01b = Button pressed10b = Error Indicator11b = Not Available";
CM_ SG_ 2365400318 Joystick10Button1PressedStatus "Joystick 10 Button 1 Pressed Status: Reports when the joystick button has been pressed.00b = Button not pressed01b = Button pressed10b = Error Indicator11b = Not Available";
CM_ SG_ 2365400318 Joystick10Button2PressedStatus "Joystick 10 Button 2 Pressed Status: Reports when the joystick button has been pressed.00b = Button not pressed01b = Button pressed10b = Error Indicator11b = Not Available";
CM_ SG_ 2365400318 Joystick10Button3PressedStatus "Joystick 10 Button 3 Pressed Status: Reports when the joystick button has been pressed.00b = Button not pressed01b = Button pressed10b = Error Indicator11b = Not Available";
CM_ SG_ 2365400318 Joystick10Button4PressedStatus "Joystick 10 Button 4 Pressed Status: Reports when the joystick button has been pressed.00b = Button not pressed01b = Button pressed10b = Error Indicator11b = Not Available";
CM_ SG_ 2365400318 Joystick10Button5PressedStatus "Joystick 10 Button 5 Pressed Status: Reports when the joystick button has been pressed.00b = Button not pressed01b = Button pressed10b = Error Indicator11b = Not Available";
CM_ SG_ 2365400318 Joystick10Button6PressedStatus "Joystick 10 Button 6 Pressed Status: Reports when the joystick button has been pressed.00b = Button not pressed01b = Button pressed10b = Error Indicator11b = Not Available";
CM_ SG_ 2365400318 Joystick10Button7PressedStatus "Joystick 10 Button 7 Pressed Status: Reports when the joystick button has been pressed.00b = Button not pressed01b = Button pressed10b = Error Indicator11b = Not Available";
CM_ SG_ 2365400318 Joystick10Button8PressedStatus "Joystick 10 Button 8 Pressed Status: Reports when the joystick button has been pressed.00b = Button not pressed01b = Button pressed10b = Error Indicator11b = Not Available";
CM_ SG_ 2365400318 Joystick10Button9PressedStatus "Joystick 10 Button 9 Pressed Status: Reports when the joystick button has been pressed.00b = Button not pressed01b = Button pressed10b = Error Indicator11b = Not Available";
CM_ SG_ 2365400318 Joystick10XAxisPosition "Joystick 10 X-Axis Position: The position of the joystick in the relative motion of travel from the neutral position.  Position value of 0 is Neutral and position value 1000 (100%) is the end of linear zone.  Value of 1022 indicates an error has occu...";
CM_ SG_ 2365400318 Joystick10YAxisPosition "Joystick 10 Y-Axis Position: The position of the joystick in the relative motion of travel from the neutral position.  Position value of 0 is Neutral and position value 1000 (100%) is the end of linear zone.  Value of 1022 indicates an error has occu...";
CM_ SG_ 2365400318 Jstk10XAxsDtntPstnStts "Joystick 10 X-Axis Detent Position Status: Reports when the current joystick position is in the detent position for that axis of travel.00b = Not in the Detent Position01b = In the Detent Position10b = Error Indicator11b = Not Available";
CM_ SG_ 2365400318 Jstk10XAxsLvrLftNgtvPstnStts "Joystick 10 X-Axis Lever Left Negative Position Status: Reports when the current joystick position is on the negative travel side (back, left, counterclockwise, down) relative to the neutral position for that axis of travel. 00b = Not on negative sid...";
CM_ SG_ 2365400318 Jstk10XAxsLvrRghtPstvPstnStts "Joystick 10 X-Axis Lever Right Positive Position Status: Reports when the current joystick position is on the positive travel side (forward, right, clockwise, up) relative to the neutral position for that axis of travel. 00b = Not on Positive side of...";
CM_ SG_ 2365400318 Jstk10XAxsNtrlPstnStts "Joystick 10 X-Axis Neutral Position Status: Reports when the current joystick position is in the neutral position for that axis of travel.  The neutral position measurement must be determined from some mechanism other than the axis position measureme...";
CM_ SG_ 2365400318 Jstk10YAxsDtntPstnStts "Joystick 10 Y-Axis Detent Position Status: Reports when the current joystick position is in the detent position for that axis of travel.00b = Not in the Detent Position01b = In the Detent Position10b = Error Indicator11b = Not Available";
CM_ SG_ 2365400318 Jstk10YAxsLvrBkNgtvPstnStts "Joystick 10 Y-Axis Lever Back Negative Position Status: Reports when the current joystick position is on the negative travel side (back, left, counterclockwise, down) relative to the neutral position for that axis of travel. 00b = Not on negative sid...";
CM_ SG_ 2365400318 Jstk10YAxsLvrFrwrdPstvPstnStts "Joystick 10 Y-Axis Lever Forward Positive Position Status: Reports when the current joystick position is on the positive travel side (forward, right, clockwise, up) relative to the neutral position for that axis of travel. 00b = Not on Positive side ...";
CM_ SG_ 2365400318 Jstk10YAxsNtrlPstnStts "Joystick 10 Y-Axis Neutral Position Status: Reports when the current joystick position is in the neutral position for that axis of travel.  The neutral position measurement must be determined from some mechanism other than the axis position measureme...";
CM_ BO_ 2365400574 "Extended Joystick Message 9";
CM_ SG_ 2365400574 Joystick9Button13PressedStatus "Joystick 9 Button 13 Pressed Status: Reports when the joystick button has been pressed.00b = Button not pressed01b = Button pressed10b = Error Indicator11b = Not Available";
CM_ SG_ 2365400574 Joystick9Button14PressedStatus "Joystick 9 Button 14 Pressed Status: Reports when the joystick button has been pressed.00b = Button not pressed01b = Button pressed10b = Error Indicator11b = Not Available";
CM_ SG_ 2365400574 Joystick9Button15PressedStatus "Joystick 9 Button 15 Pressed Status: Reports when the joystick button has been pressed.00b = Button not pressed01b = Button pressed10b = Error Indicator11b = Not Available";
CM_ SG_ 2365400574 Joystick9Button16PressedStatus "Joystick 9 Button 16 Pressed Status: Reports when the joystick button has been pressed.00b = Button not pressed01b = Button pressed10b = Error Indicator11b = Not Available";
CM_ SG_ 2365400574 Joystick9GripXAxisPosition "Joystick 9 Grip X-Axis Position: The position of the joystick grip in the relative motion of travel from the neutral position.  Position value of 0 is Neutral and position value 1000 (100%) is the end of linear zone.  Value of 1022 indicates an error...";
CM_ SG_ 2365400574 Joystick9GripYAxisPosition "Joystick 9 Grip Y-Axis Position: The position of the joystick grip in the relative motion of travel from the neutral position.  Position value of 0 is Neutral and position value 1000 (100%) is the end of linear zone.  Value of 1022 indicates an error...";
CM_ SG_ 2365400574 Joystick9ThetaAxisPosition "Joystick 9 Theta-Axis Position: The position of the joystick in the relative motion of travel from the neutral position.  Position value of 0 is Neutral and position value 1000 (100%) is the end of linear zone.  Value of 1022 indicates an error has o...";
CM_ SG_ 2365400574 Jst9GpYAxsLvFwdPstvPstStts "Joystick 9 Grip Y-Axis Lever Forward Positive Position Status: Reports when the current joystick grip position is on the positive travel side (forward, right, clockwise, up) relative to the neutral position for that axis of travel. 00b = Not on Posit...";
CM_ SG_ 2365400574 Jst9TtAxsCtCwsNtvPstStts "Joystick 9 Theta-Axis Counter Clockwise Negative Position Status: Reports when the current joystick position is on the negative travel side (back, left, counterclockwise, down) relative to the neutral position for that axis of travel. 00b = Not on ne...";
CM_ SG_ 2365400574 Jstk9GrpXAxsDtntPstnStts "Joystick 9 Grip X-Axis Detent Position Status: Reports when the current joystick grip position is in the detent position for that axis of travel.00b = Not in the Detent Position01b = In the Detent Position10b = Error Indicator11b = Not Available...";
CM_ SG_ 2365400574 Jstk9GrpXAxsLvrLftNgtvPstnStts "Joystick 9 Grip X-Axis Lever Left Negative Position Status: Reports when the current joystick grip position is on the negative travel side (back, left, counterclockwise, down) relative to the neutral position for that axis of travel. 00b = Not on neg...";
CM_ SG_ 2365400574 Jstk9GrpXAxsLvrRghtPstvPstnStts "Joystick 9 Grip X-Axis Lever Right Positive Position Status: Reports when the current joystick grip position is on the positive travel side (forward, right, clockwise, up) relative to the neutral position for that axis of travel. 00b = Not on Positiv...";
CM_ SG_ 2365400574 Jstk9GrpXAxsNtrlPstnStts "Joystick 9 Grip X-Axis Neutral Position Status: Reports when the current joystick grip position is in the neutral position for that axis of travel.  The neutral position measurement must be determined from some mechanism other than the axis position ...";
CM_ SG_ 2365400574 Jstk9GrpYAxsDtntPstnStts "Joystick 9 Grip Y-Axis Detent Position Status: Reports when the current joystick grip position is in the detent position for that axis of travel.00b = Not in the Detent Position01b = In the Detent Position10b = Error Indicator11b = Not Available...";
CM_ SG_ 2365400574 Jstk9GrpYAxsLvrBkNgtvPstnStts "Joystick 9 Grip Y-Axis Lever Back Negative Position Status: Reports when the current joystick grip position is on the negative travel side (back, left, counterclockwise, down) relative to the neutral position for that axis of travel. 00b = Not on neg...";
CM_ SG_ 2365400574 Jstk9GrpYAxsNtrlPstnStts "Joystick 9 Grip Y-Axis Neutral Position Status: Reports when the current joystick grip position is in the neutral position for that axis of travel.  The neutral position measurement must be determined from some mechanism other than the axis position ...";
CM_ SG_ 2365400574 Jstk9ThtAxsClkwsPstvPstnStts "Joystick 9 Theta-Axis Clockwise Positive Position Status: Reports when the current joystick position is on the positive travel side (forward, right, clockwise, up) relative to the neutral position for that axis of travel. 00b = Not on Positive side o...";
CM_ SG_ 2365400574 Jstk9ThtAxsDtntPstnStts "Joystick 9 Theta-Axis Detent Position Status: Reports when the current joystick position is in the detent position for that axis of travel.00b = Not in the Detent Position01b = In the Detent Position10b = Error Indicator11b = Not Available";
CM_ SG_ 2365400574 Jstk9ThtAxsNtrlPstnStts "Joystick 9 Theta-Axis Neutral Position Status: Reports when the current joystick position is in the neutral position for that axis of travel.  The neutral position measurement must be determined from some mechanism other than the axis position measur...";
CM_ BO_ 2365400830 "Basic Joystick Message 9";
CM_ SG_ 2365400830 Joystick9Button10PressedStatus "Joystick 9 Button 10 Pressed Status: Reports when the joystick button has been pressed.00b = Button not pressed01b = Button pressed10b = Error Indicator11b = Not Available";
CM_ SG_ 2365400830 Joystick9Button11PressedStatus "Joystick 9 Button 11 Pressed Status: Reports when the joystick button has been pressed.00b = Button not pressed01b = Button pressed10b = Error Indicator11b = Not Available";
CM_ SG_ 2365400830 Joystick9Button12PressedStatus "Joystick 9 Button 12 Pressed Status: Reports when the joystick button has been pressed.00b = Button not pressed01b = Button pressed10b = Error Indicator11b = Not Available";
CM_ SG_ 2365400830 Joystick9Button1PressedStatus "Joystick 9 Button 1 Pressed Status: Reports when the joystick button has been pressed.00b = Button not pressed01b = Button pressed10b = Error Indicator11b = Not Available";
CM_ SG_ 2365400830 Joystick9Button2PressedStatus "Joystick 9 Button 2 Pressed Status: Reports when the joystick button has been pressed.00b = Button not pressed01b = Button pressed10b = Error Indicator11b = Not Available";
CM_ SG_ 2365400830 Joystick9Button3PressedStatus "Joystick 9 Button 3 Pressed Status: Reports when the joystick button has been pressed.00b = Button not pressed01b = Button pressed10b = Error Indicator11b = Not Available";
CM_ SG_ 2365400830 Joystick9Button4PressedStatus "Joystick 9 Button 4 Pressed Status: Reports when the joystick button has been pressed.00b = Button not pressed01b = Button pressed10b = Error Indicator11b = Not Available";
CM_ SG_ 2365400830 Joystick9Button5PressedStatus "Joystick 9 Button 5 Pressed Status: Reports when the joystick button has been pressed.00b = Button not pressed01b = Button pressed10b = Error Indicator11b = Not Available";
CM_ SG_ 2365400830 Joystick9Button6PressedStatus "Joystick 9 Button 6 Pressed Status: Reports when the joystick button has been pressed.00b = Button not pressed01b = Button pressed10b = Error Indicator11b = Not Available";
CM_ SG_ 2365400830 Joystick9Button7PressedStatus "Joystick 9 Button 7 Pressed Status: Reports when the joystick button has been pressed.00b = Button not pressed01b = Button pressed10b = Error Indicator11b = Not Available";
CM_ SG_ 2365400830 Joystick9Button8PressedStatus "Joystick 9 Button 8 Pressed Status: Reports when the joystick button has been pressed.00b = Button not pressed01b = Button pressed10b = Error Indicator11b = Not Available";
CM_ SG_ 2365400830 Joystick9Button9PressedStatus "Joystick 9 Button 9 Pressed Status: Reports when the joystick button has been pressed.00b = Button not pressed01b = Button pressed10b = Error Indicator11b = Not Available";
CM_ SG_ 2365400830 Joystick9XAxisPosition "Joystick 9 X-Axis Position: The position of the joystick in the relative motion of travel from the neutral position.  Position value of 0 is Neutral and position value 1000 (100%) is the end of linear zone.  Value of 1022 indicates an error has occur...";
CM_ SG_ 2365400830 Joystick9YAxisPosition "Joystick 9 Y-Axis Position: The position of the joystick in the relative motion of travel from the neutral position.  Position value of 0 is Neutral and position value 1000 (100%) is the end of linear zone.  Value of 1022 indicates an error has occur...";
CM_ SG_ 2365400830 Jstk9XAxsDtntPstnStts "Joystick 9 X-Axis Detent Position Status: Reports when the current joystick position is in the detent position for that axis of travel.00b = Not in the Detent Position01b = In the Detent Position10b = Error Indicator11b = Not Available";
CM_ SG_ 2365400830 Jstk9XAxsLvrLftNgtvPstnStts "Joystick 9 X-Axis Lever Left Negative Position Status: Reports when the current joystick position is on the negative travel side (back, left, counterclockwise, down) relative to the neutral position for that axis of travel. 00b = Not on negative side...";
CM_ SG_ 2365400830 Jstk9XAxsLvrRghtPstvPstnStts "Joystick 9 X-Axis Lever Right Positive Position Status: Reports when the current joystick position is on the positive travel side (forward, right, clockwise, up) relative to the neutral position for that axis of travel. 00b = Not on Positive side of ...";
CM_ SG_ 2365400830 Jstk9XAxsNtrlPstnStts "Joystick 9 X-Axis Neutral Position Status: Reports when the current joystick position is in the neutral position for that axis of travel.  The neutral position measurement must be determined from some mechanism other than the axis position measuremen...";
CM_ SG_ 2365400830 Jstk9YAxsDtntPstnStts "Joystick 9 Y-Axis Detent Position Status: Reports when the current joystick position is in the detent position for that axis of travel.00b = Not in the Detent Position01b = In the Detent Position10b = Error Indicator11b = Not Available";
CM_ SG_ 2365400830 Jstk9YAxsLvrBkNgtvPstnStts "Joystick 9 Y-Axis Lever Back Negative Position Status: Reports when the current joystick position is on the negative travel side (back, left, counterclockwise, down) relative to the neutral position for that axis of travel. 00b = Not on negative side...";
CM_ SG_ 2365400830 Jstk9YAxsLvrFrwrdPstvPstnStts "Joystick 9 Y-Axis Lever Forward Positive Position Status: Reports when the current joystick position is on the positive travel side (forward, right, clockwise, up) relative to the neutral position for that axis of travel. 00b = Not on Positive side o...";
CM_ SG_ 2365400830 Jstk9YAxsNtrlPstnStts "Joystick 9 Y-Axis Neutral Position Status: Reports when the current joystick position is in the neutral position for that axis of travel.  The neutral position measurement must be determined from some mechanism other than the axis position measuremen...";
CM_ BO_ 2365401086 "Extended Joystick Message 8";
CM_ SG_ 2365401086 Joystick8Button13PressedStatus "Joystick 8 Button 13 Pressed Status: Reports when the joystick button has been pressed.00b = Button not pressed01b = Button pressed10b = Error Indicator11b = Not Available";
CM_ SG_ 2365401086 Joystick8Button14PressedStatus "Joystick 8 Button 14 Pressed Status: Reports when the joystick button has been pressed.00b = Button not pressed01b = Button pressed10b = Error Indicator11b = Not Available";
CM_ SG_ 2365401086 Joystick8Button15PressedStatus "Joystick 8 Button 15 Pressed Status: Reports when the joystick button has been pressed.00b = Button not pressed01b = Button pressed10b = Error Indicator11b = Not Available";
CM_ SG_ 2365401086 Joystick8Button16PressedStatus "Joystick 8 Button 16 Pressed Status: Reports when the joystick button has been pressed.00b = Button not pressed01b = Button pressed10b = Error Indicator11b = Not Available";
CM_ SG_ 2365401086 Joystick8GripXAxisPosition "Joystick 8 Grip X-Axis Position: The position of the joystick grip in the relative motion of travel from the neutral position.  Position value of 0 is Neutral and position value 1000 (100%) is the end of linear zone.  Value of 1022 indicates an error...";
CM_ SG_ 2365401086 Joystick8GripYAxisPosition "Joystick 8 Grip Y-Axis Position: The position of the joystick grip in the relative motion of travel from the neutral position.  Position value of 0 is Neutral and position value 1000 (100%) is the end of linear zone.  Value of 1022 indicates an error...";
CM_ SG_ 2365401086 Joystick8ThetaAxisPosition "Joystick 8 Theta-Axis Position: The position of the joystick in the relative motion of travel from the neutral position.  Position value of 0 is Neutral and position value 1000 (100%) is the end of linear zone.  Value of 1022 indicates an error has o...";
CM_ SG_ 2365401086 Jst8GpYAxsLvFwdPstvPstStts "Joystick 8 Grip Y-Axis Lever Forward Positive Position Status: Reports when the current joystick grip position is on the positive travel side (forward, right, clockwise, up) relative to the neutral position for that axis of travel. 00b = Not on Posit...";
CM_ SG_ 2365401086 Jst8TtAxsCtCwsNtvPstStts "Joystick 8 Theta-Axis Counter Clockwise Negative Position Status: Reports when the current joystick position is on the negative travel side (back, left, counterclockwise, down) relative to the neutral position for that axis of travel. 00b = Not on ne...";
CM_ SG_ 2365401086 Jstk8GrpXAxsDtntPstnStts "Joystick 8 Grip X-Axis Detent Position Status: Reports when the current joystick grip position is in the detent position for that axis of travel.00b = Not in the Detent Position01b = In the Detent Position10b = Error Indicator11b = Not Available...";
CM_ SG_ 2365401086 Jstk8GrpXAxsLvrLftNgtvPstnStts "Joystick 8 Grip X-Axis Lever Left Negative Position Status: Reports when the current joystick grip position is on the negative travel side (back, left, counterclockwise, down) relative to the neutral position for that axis of travel. 00b = Not on neg...";
CM_ SG_ 2365401086 Jstk8GrpXAxsLvrRghtPstvPstnStts "Joystick 8 Grip X-Axis Lever Right Positive Position Status: Reports when the current joystick grip position is on the positive travel side (forward, right, clockwise, up) relative to the neutral position for that axis of travel. 00b = Not on Positiv...";
CM_ SG_ 2365401086 Jstk8GrpXAxsNtrlPstnStts "Joystick 8 Grip X-Axis Neutral Position Status: Reports when the current joystick grip position is in the neutral position for that axis of travel.  The neutral position measurement must be determined from some mechanism other than the axis position ...";
CM_ SG_ 2365401086 Jstk8GrpYAxsDtntPstnStts "Joystick 8 Grip Y-Axis Detent Position Status: Reports when the current joystick grip position is in the detent position for that axis of travel.00b = Not in the Detent Position01b = In the Detent Position10b = Error Indicator11b = Not Available...";
CM_ SG_ 2365401086 Jstk8GrpYAxsLvrBkNgtvPstnStts "Joystick 8 Grip Y-Axis Lever Back Negative Position Status: Reports when the current joystick grip position is on the negative travel side (back, left, counterclockwise, down) relative to the neutral position for that axis of travel. 00b = Not on neg...";
CM_ SG_ 2365401086 Jstk8GrpYAxsNtrlPstnStts "Joystick 8 Grip Y-Axis Neutral Position Status: Reports when the current joystick grip position is in the neutral position for that axis of travel.  The neutral position measurement must be determined from some mechanism other than the axis position ...";
CM_ SG_ 2365401086 Jstk8ThtAxsClkwsPstvPstnStts "Joystick 8 Theta-Axis Clockwise Positive Position Status: Reports when the current joystick position is on the positive travel side (forward, right, clockwise, up) relative to the neutral position for that axis of travel. 00b = Not on Positive side o...";
CM_ SG_ 2365401086 Jstk8ThtAxsDtntPstnStts "Joystick 8 Theta-Axis Detent Position Status: Reports when the current joystick position is in the detent position for that axis of travel.00b = Not in the Detent Position01b = In the Detent Position10b = Error Indicator11b = Not Available";
CM_ SG_ 2365401086 Jstk8ThtAxsNtrlPstnStts "Joystick 8 Theta-Axis Neutral Position Status: Reports when the current joystick position is in the neutral position for that axis of travel.  The neutral position measurement must be determined from some mechanism other than the axis position measur...";
CM_ BO_ 2365401342 "Basic Joystick Message 8";
CM_ SG_ 2365401342 Joystick8Button10PressedStatus "Joystick 8 Button 10 Pressed Status: Reports when the joystick button has been pressed.00b = Button not pressed01b = Button pressed10b = Error Indicator11b = Not Available";
CM_ SG_ 2365401342 Joystick8Button11PressedStatus "Joystick 8 Button 11 Pressed Status: Reports when the joystick button has been pressed.00b = Button not pressed01b = Button pressed10b = Error Indicator11b = Not Available";
CM_ SG_ 2365401342 Joystick8Button12PressedStatus "Joystick 8 Button 12 Pressed Status: Reports when the joystick button has been pressed.00b = Button not pressed01b = Button pressed10b = Error Indicator11b = Not Available";
CM_ SG_ 2365401342 Joystick8Button1PressedStatus "Joystick 8 Button 1 Pressed Status: Reports when the joystick button has been pressed.00b = Button not pressed01b = Button pressed10b = Error Indicator11b = Not Available";
CM_ SG_ 2365401342 Joystick8Button2PressedStatus "Joystick 8 Button 2 Pressed Status: Reports when the joystick button has been pressed.00b = Button not pressed01b = Button pressed10b = Error Indicator11b = Not Available";
CM_ SG_ 2365401342 Joystick8Button3PressedStatus "Joystick 8 Button 3 Pressed Status: Reports when the joystick button has been pressed.00b = Button not pressed01b = Button pressed10b = Error Indicator11b = Not Available";
CM_ SG_ 2365401342 Joystick8Button4PressedStatus "Joystick 8 Button 4 Pressed Status: Reports when the joystick button has been pressed.00b = Button not pressed01b = Button pressed10b = Error Indicator11b = Not Available";
CM_ SG_ 2365401342 Joystick8Button5PressedStatus "Joystick 8 Button 5 Pressed Status: Reports when the joystick button has been pressed.00b = Button not pressed01b = Button pressed10b = Error Indicator11b = Not Available";
CM_ SG_ 2365401342 Joystick8Button6PressedStatus "Joystick 8 Button 6 Pressed Status: Reports when the joystick button has been pressed.00b = Button not pressed01b = Button pressed10b = Error Indicator11b = Not Available";
CM_ SG_ 2365401342 Joystick8Button7PressedStatus "Joystick 8 Button 7 Pressed Status: Reports when the joystick button has been pressed.00b = Button not pressed01b = Button pressed10b = Error Indicator11b = Not Available";
CM_ SG_ 2365401342 Joystick8Button8PressedStatus "Joystick 8 Button 8 Pressed Status: Reports when the joystick button has been pressed.00b = Button not pressed01b = Button pressed10b = Error Indicator11b = Not Available";
CM_ SG_ 2365401342 Joystick8Button9PressedStatus "Joystick 8 Button 9 Pressed Status: Reports when the joystick button has been pressed.00b = Button not pressed01b = Button pressed10b = Error Indicator11b = Not Available";
CM_ SG_ 2365401342 Joystick8XAxisPosition "Joystick 8 X-Axis Position: The position of the joystick in the relative motion of travel from the neutral position.  Position value of 0 is Neutral and position value 1000 (100%) is the end of linear zone.  Value of 1022 indicates an error has occur...";
CM_ SG_ 2365401342 Joystick8YAxisPosition "Joystick 8 Y-Axis Position: The position of the joystick in the relative motion of travel from the neutral position.  Position value of 0 is Neutral and position value 1000 (100%) is the end of linear zone.  Value of 1022 indicates an error has occur...";
CM_ SG_ 2365401342 Jstk8XAxsDtntPstnStts "Joystick 8 X-Axis Detent Position Status: Reports when the current joystick position is in the detent position for that axis of travel.00b = Not in the Detent Position01b = In the Detent Position10b = Error Indicator11b = Not Available";
CM_ SG_ 2365401342 Jstk8XAxsLvrLftNgtvPstnStts "Joystick 8 X-Axis Lever Left Negative Position Status: Reports when the current joystick position is on the negative travel side (back, left, counterclockwise, down) relative to the neutral position for that axis of travel. 00b = Not on negative side...";
CM_ SG_ 2365401342 Jstk8XAxsLvrRghtPstvPstnStts "Joystick 8 X-Axis Lever Right Positive Position Status: Reports when the current joystick position is on the positive travel side (forward, right, clockwise, up) relative to the neutral position for that axis of travel. 00b = Not on Positive side of ...";
CM_ SG_ 2365401342 Jstk8XAxsNtrlPstnStts "Joystick 8 X-Axis Neutral Position Status: Reports when the current joystick position is in the neutral position for that axis of travel.  The neutral position measurement must be determined from some mechanism other than the axis position measuremen...";
CM_ SG_ 2365401342 Jstk8YAxsDtntPstnStts "Joystick 8 Y-Axis Detent Position Status: Reports when the current joystick position is in the detent position for that axis of travel.00b = Not in the Detent Position01b = In the Detent Position10b = Error Indicator11b = Not Available";
CM_ SG_ 2365401342 Jstk8YAxsLvrBkNgtvPstnStts "Joystick 8 Y-Axis Lever Back Negative Position Status: Reports when the current joystick position is on the negative travel side (back, left, counterclockwise, down) relative to the neutral position for that axis of travel. 00b = Not on negative side...";
CM_ SG_ 2365401342 Jstk8YAxsLvrFrwrdPstvPstnStts "Joystick 8 Y-Axis Lever Forward Positive Position Status: Reports when the current joystick position is on the positive travel side (forward, right, clockwise, up) relative to the neutral position for that axis of travel. 00b = Not on Positive side o...";
CM_ SG_ 2365401342 Jstk8YAxsNtrlPstnStts "Joystick 8 Y-Axis Neutral Position Status: Reports when the current joystick position is in the neutral position for that axis of travel.  The neutral position measurement must be determined from some mechanism other than the axis position measuremen...";
CM_ BO_ 2365401598 "Extended Joystick Message 7";
CM_ SG_ 2365401598 Joystick7Button13PressedStatus "Joystick 7 Button 13 Pressed Status: Reports when the joystick button has been pressed.00b = Button not pressed01b = Button pressed10b = Error Indicator11b = Not Available";
CM_ SG_ 2365401598 Joystick7Button14PressedStatus "Joystick 7 Button 14 Pressed Status: Reports when the joystick button has been pressed.00b = Button not pressed01b = Button pressed10b = Error Indicator11b = Not Available";
CM_ SG_ 2365401598 Joystick7Button15PressedStatus "Joystick 7 Button 15 Pressed Status: Reports when the joystick button has been pressed.00b = Button not pressed01b = Button pressed10b = Error Indicator11b = Not Available";
CM_ SG_ 2365401598 Joystick7Button16PressedStatus "Joystick 7 Button 16 Pressed Status: Reports when the joystick button has been pressed.00b = Button not pressed01b = Button pressed10b = Error Indicator11b = Not Available";
CM_ SG_ 2365401598 Joystick7GripXAxisPosition "Joystick 7 Grip X-Axis Position: The position of the joystick grip in the relative motion of travel from the neutral position.  Position value of 0 is Neutral and position value 1000 (100%) is the end of linear zone.  Value of 1022 indicates an error...";
CM_ SG_ 2365401598 Joystick7GripYAxisPosition "Joystick 7 Grip Y-Axis Position: The position of the joystick grip in the relative motion of travel from the neutral position.  Position value of 0 is Neutral and position value 1000 (100%) is the end of linear zone.  Value of 1022 indicates an error...";
CM_ SG_ 2365401598 Joystick7ThetaAxisPosition "Joystick 7 Theta-Axis Position: The position of the joystick in the relative motion of travel from the neutral position.  Position value of 0 is Neutral and position value 1000 (100%) is the end of linear zone.  Value of 1022 indicates an error has o...";
CM_ SG_ 2365401598 Jst7GpYAxsLvFwdPstvPstStts "Joystick 7 Grip Y-Axis Lever Forward Positive Position Status: Reports when the current joystick grip position is on the positive travel side (forward, right, clockwise, up) relative to the neutral position for that axis of travel. 00b = Not on Posit...";
CM_ SG_ 2365401598 Jst7TtAxsCtCwsNtvPstStts "Joystick 7 Theta-Axis Counter Clockwise Negative Position Status: Reports when the current joystick position is on the negative travel side (back, left, counterclockwise, down) relative to the neutral position for that axis of travel. 00b = Not on ne...";
CM_ SG_ 2365401598 Jstk7GrpXAxsDtntPstnStts "Joystick 7 Grip X-Axis Detent Position Status: Reports when the current joystick grip position is in the detent position for that axis of travel.00b = Not in the Detent Position01b = In the Detent Position10b = Error Indicator11b = Not Available...";
CM_ SG_ 2365401598 Jstk7GrpXAxsLvrLftNgtvPstnStts "Joystick 7 Grip X-Axis Lever Left Negative Position Status: Reports when the current joystick grip position is on the negative travel side (back, left, counterclockwise, down) relative to the neutral position for that axis of travel. 00b = Not on neg...";
CM_ SG_ 2365401598 Jstk7GrpXAxsLvrRghtPstvPstnStts "Joystick 7 Grip X-Axis Lever Right Positive Position Status: Reports when the current joystick grip position is on the positive travel side (forward, right, clockwise, up) relative to the neutral position for that axis of travel. 00b = Not on Positiv...";
CM_ SG_ 2365401598 Jstk7GrpXAxsNtrlPstnStts "Joystick 7 Grip X-Axis Neutral Position Status: Reports when the current joystick grip position is in the neutral position for that axis of travel.  The neutral position measurement must be determined from some mechanism other than the axis position ...";
CM_ SG_ 2365401598 Jstk7GrpYAxsDtntPstnStts "Joystick 7 Grip Y-Axis Detent Position Status: Reports when the current joystick grip position is in the detent position for that axis of travel.00b = Not in the Detent Position01b = In the Detent Position10b = Error Indicator11b = Not Available...";
CM_ SG_ 2365401598 Jstk7GrpYAxsLvrBkNgtvPstnStts "Joystick 7 Grip Y-Axis Lever Back Negative Position Status: Reports when the current joystick grip position is on the negative travel side (back, left, counterclockwise, down) relative to the neutral position for that axis of travel. 00b = Not on neg...";
CM_ SG_ 2365401598 Jstk7GrpYAxsNtrlPstnStts "Joystick 7 Grip Y-Axis Neutral Position Status: Reports when the current joystick grip position is in the neutral position for that axis of travel.  The neutral position measurement must be determined from some mechanism other than the axis position ...";
CM_ SG_ 2365401598 Jstk7ThtAxsClkwsPstvPstnStts "Joystick 7 Theta-Axis Clockwise Positive Position Status: Reports when the current joystick position is on the positive travel side (forward, right, clockwise, up) relative to the neutral position for that axis of travel. 00b = Not on Positive side o...";
CM_ SG_ 2365401598 Jstk7ThtAxsDtntPstnStts "Joystick 7 Theta-Axis Detent Position Status: Reports when the current joystick position is in the detent position for that axis of travel.00b = Not in the Detent Position01b = In the Detent Position10b = Error Indicator11b = Not Available";
CM_ SG_ 2365401598 Jstk7ThtAxsNtrlPstnStts "Joystick 7 Theta-Axis Neutral Position Status: Reports when the current joystick position is in the neutral position for that axis of travel.  The neutral position measurement must be determined from some mechanism other than the axis position measur...";
CM_ BO_ 2365401854 "Basic Joystick Message 7";
CM_ SG_ 2365401854 Joystick7Button10PressedStatus "Joystick 7 Button 10 Pressed Status: Reports when the joystick button has been pressed.00b = Button not pressed01b = Button pressed10b = Error Indicator11b = Not Available";
CM_ SG_ 2365401854 Joystick7Button11PressedStatus "Joystick 7 Button 11 Pressed Status: Reports when the joystick button has been pressed.00b = Button not pressed01b = Button pressed10b = Error Indicator11b = Not Available";
CM_ SG_ 2365401854 Joystick7Button12PressedStatus "Joystick 7 Button 12 Pressed Status: Reports when the joystick button has been pressed.00b = Button not pressed01b = Button pressed10b = Error Indicator11b = Not Available";
CM_ SG_ 2365401854 Joystick7Button1PressedStatus "Joystick 7 Button 1 Pressed Status: Reports when the joystick button has been pressed.00b = Button not pressed01b = Button pressed10b = Error Indicator11b = Not Available";
CM_ SG_ 2365401854 Joystick7Button2PressedStatus "Joystick 7 Button 2 Pressed Status: Reports when the joystick button has been pressed.00b = Button not pressed01b = Button pressed10b = Error Indicator11b = Not Available";
CM_ SG_ 2365401854 Joystick7Button3PressedStatus "Joystick 7 Button 3 Pressed Status: Reports when the joystick button has been pressed.00b = Button not pressed01b = Button pressed10b = Error Indicator11b = Not Available";
CM_ SG_ 2365401854 Joystick7Button4PressedStatus "Joystick 7 Button 4 Pressed Status: Reports when the joystick button has been pressed.00b = Button not pressed01b = Button pressed10b = Error Indicator11b = Not Available";
CM_ SG_ 2365401854 Joystick7Button5PressedStatus "Joystick 7 Button 5 Pressed Status: Reports when the joystick button has been pressed.00b = Button not pressed01b = Button pressed10b = Error Indicator11b = Not Available";
CM_ SG_ 2365401854 Joystick7Button6PressedStatus "Joystick 7 Button 6 Pressed Status: Reports when the joystick button has been pressed.00b = Button not pressed01b = Button pressed10b = Error Indicator11b = Not Available";
CM_ SG_ 2365401854 Joystick7Button7PressedStatus "Joystick 7 Button 7 Pressed Status: Reports when the joystick button has been pressed.00b = Button not pressed01b = Button pressed10b = Error Indicator11b = Not Available";
CM_ SG_ 2365401854 Joystick7Button8PressedStatus "Joystick 7 Button 8 Pressed Status: Reports when the joystick button has been pressed.00b = Button not pressed01b = Button pressed10b = Error Indicator11b = Not Available";
CM_ SG_ 2365401854 Joystick7Button9PressedStatus "Joystick 7 Button 9 Pressed Status: Reports when the joystick button has been pressed.00b = Button not pressed01b = Button pressed10b = Error Indicator11b = Not Available";
CM_ SG_ 2365401854 Joystick7XAxisPosition "Joystick 7 X-Axis Position: The position of the joystick in the relative motion of travel from the neutral position.  Position value of 0 is Neutral and position value 1000 (100%) is the end of linear zone.  Value of 1022 indicates an error has occur...";
CM_ SG_ 2365401854 Joystick7YAxisPosition "Joystick 7 Y-Axis Position: The position of the joystick in the relative motion of travel from the neutral position.  Position value of 0 is Neutral and position value 1000 (100%) is the end of linear zone.  Value of 1022 indicates an error has occur...";
CM_ SG_ 2365401854 Jstk7XAxsDtntPstnStts "Joystick 7 X-Axis Detent Position Status: Reports when the current joystick position is in the detent position for that axis of travel.00b = Not in the Detent Position01b = In the Detent Position10b = Error Indicator11b = Not Available";
CM_ SG_ 2365401854 Jstk7XAxsLvrLftNgtvPstnStts "Joystick 7 X-Axis Lever Left Negative Position Status: Reports when the current joystick position is on the negative travel side (back, left, counterclockwise, down) relative to the neutral position for that axis of travel. 00b = Not on negative side...";
CM_ SG_ 2365401854 Jstk7XAxsLvrRghtPstvPstnStts "Joystick 7 X-Axis Lever Right Positive Position Status: Reports when the current joystick position is on the positive travel side (forward, right, clockwise, up) relative to the neutral position for that axis of travel. 00b = Not on Positive side of ...";
CM_ SG_ 2365401854 Jstk7XAxsNtrlPstnStts "Joystick 7 X-Axis Neutral Position Status: Reports when the current joystick position is in the neutral position for that axis of travel.  The neutral position measurement must be determined from some mechanism other than the axis position measuremen...";
CM_ SG_ 2365401854 Jstk7YAxsDtntPstnStts "Joystick 7 Y-Axis Detent Position Status: Reports when the current joystick position is in the detent position for that axis of travel.00b = Not in the Detent Position01b = In the Detent Position10b = Error Indicator11b = Not Available";
CM_ SG_ 2365401854 Jstk7YAxsLvrBkNgtvPstnStts "Joystick 7 Y-Axis Lever Back Negative Position Status: Reports when the current joystick position is on the negative travel side (back, left, counterclockwise, down) relative to the neutral position for that axis of travel. 00b = Not on negative side...";
CM_ SG_ 2365401854 Jstk7YAxsLvrFrwrdPstvPstnStts "Joystick 7 Y-Axis Lever Forward Positive Position Status: Reports when the current joystick position is on the positive travel side (forward, right, clockwise, up) relative to the neutral position for that axis of travel. 00b = Not on Positive side o...";
CM_ SG_ 2365401854 Jstk7YAxsNtrlPstnStts "Joystick 7 Y-Axis Neutral Position Status: Reports when the current joystick position is in the neutral position for that axis of travel.  The neutral position measurement must be determined from some mechanism other than the axis position measuremen...";
CM_ BO_ 2365402110 "Extended Joystick Message 6";
CM_ SG_ 2365402110 Joystick6Button13PressedStatus "Joystick 6 Button 13 Pressed Status: Reports when the joystick button has been pressed.00b = Button not pressed01b = Button pressed10b = Error Indicator11b = Not Available";
CM_ SG_ 2365402110 Joystick6Button14PressedStatus "Joystick 6 Button 14 Pressed Status: Reports when the joystick button has been pressed.00b = Button not pressed01b = Button pressed10b = Error Indicator11b = Not Available";
CM_ SG_ 2365402110 Joystick6Button15PressedStatus "Joystick 6 Button 15 Pressed Status: Reports when the joystick button has been pressed.00b = Button not pressed01b = Button pressed10b = Error Indicator11b = Not Available";
CM_ SG_ 2365402110 Joystick6Button16PressedStatus "Joystick 6 Button 16 Pressed Status: Reports when the joystick button has been pressed.00b = Button not pressed01b = Button pressed10b = Error Indicator11b = Not Available";
CM_ SG_ 2365402110 Joystick6GripXAxisPosition "Joystick 6 Grip X-Axis Position: The position of the joystick grip in the relative motion of travel from the neutral position.  Position value of 0 is Neutral and position value 1000 (100%) is the end of linear zone.  Value of 1022 indicates an error...";
CM_ SG_ 2365402110 Joystick6GripYAxisPosition "Joystick 6 Grip Y-Axis Position: The position of the joystick grip in the relative motion of travel from the neutral position.  Position value of 0 is Neutral and position value 1000 (100%) is the end of linear zone.  Value of 1022 indicates an error...";
CM_ SG_ 2365402110 Joystick6ThetaAxisPosition "Joystick 6 Theta-Axis Position: The position of the joystick in the relative motion of travel from the neutral position.  Position value of 0 is Neutral and position value 1000 (100%) is the end of linear zone.  Value of 1022 indicates an error has o...";
CM_ SG_ 2365402110 Jst6GpYAxsLvFwdPstvPstStts "Joystick 6 Grip Y-Axis Lever Forward Positive Position Status: Reports when the current joystick grip position is on the positive travel side (forward, right, clockwise, up) relative to the neutral position for that axis of travel. 00b = Not on Posit...";
CM_ SG_ 2365402110 Jst6TtAxsCtCwsNtvPstStts "Joystick 6 Theta-Axis Counter Clockwise Negative Position Status: Reports when the current joystick position is on the negative travel side (back, left, counterclockwise, down) relative to the neutral position for that axis of travel. 00b = Not on ne...";
CM_ SG_ 2365402110 Jstk6GrpXAxsDtntPstnStts "Joystick 6 Grip X-Axis Detent Position Status: Reports when the current joystick grip position is in the detent position for that axis of travel.00b = Not in the Detent Position01b = In the Detent Position10b = Error Indicator11b = Not Available...";
CM_ SG_ 2365402110 Jstk6GrpXAxsLvrLftNgtvPstnStts "Joystick 6 Grip X-Axis Lever Left Negative Position Status: Reports when the current joystick grip position is on the negative travel side (back, left, counterclockwise, down) relative to the neutral position for that axis of travel. 00b = Not on neg...";
CM_ SG_ 2365402110 Jstk6GrpXAxsLvrRghtPstvPstnStts "Joystick 6 Grip X-Axis Lever Right Positive Position Status: Reports when the current joystick grip position is on the positive travel side (forward, right, clockwise, up) relative to the neutral position for that axis of travel. 00b = Not on Positiv...";
CM_ SG_ 2365402110 Jstk6GrpXAxsNtrlPstnStts "Joystick 6 Grip X-Axis Neutral Position Status: Reports when the current joystick grip position is in the neutral position for that axis of travel.  The neutral position measurement must be determined from some mechanism other than the axis position ...";
CM_ SG_ 2365402110 Jstk6GrpYAxsDtntPstnStts "Joystick 6 Grip Y-Axis Detent Position Status: Reports when the current joystick grip position is in the detent position for that axis of travel.00b = Not in the Detent Position01b = In the Detent Position10b = Error Indicator11b = Not Available...";
CM_ SG_ 2365402110 Jstk6GrpYAxsLvrBkNgtvPstnStts "Joystick 6 Grip Y-Axis Lever Back Negative Position Status: Reports when the current joystick grip position is on the negative travel side (back, left, counterclockwise, down) relative to the neutral position for that axis of travel. 00b = Not on neg...";
CM_ SG_ 2365402110 Jstk6GrpYAxsNtrlPstnStts "Joystick 6 Grip Y-Axis Neutral Position Status: Reports when the current joystick grip position is in the neutral position for that axis of travel.  The neutral position measurement must be determined from some mechanism other than the axis position ...";
CM_ SG_ 2365402110 Jstk6ThtAxsClkwsPstvPstnStts "Joystick 6 Theta-Axis Clockwise Positive Position Status: Reports when the current joystick position is on the positive travel side (forward, right, clockwise, up) relative to the neutral position for that axis of travel. 00b = Not on Positive side o...";
CM_ SG_ 2365402110 Jstk6ThtAxsDtntPstnStts "Joystick 6 Theta-Axis Detent Position Status: Reports when the current joystick position is in the detent position for that axis of travel.00b = Not in the Detent Position01b = In the Detent Position10b = Error Indicator11b = Not Available";
CM_ SG_ 2365402110 Jstk6ThtAxsNtrlPstnStts "Joystick 6 Theta-Axis Neutral Position Status: Reports when the current joystick position is in the neutral position for that axis of travel.  The neutral position measurement must be determined from some mechanism other than the axis position measur...";
CM_ BO_ 2365402366 "Basic Joystick Message 6";
CM_ SG_ 2365402366 Joystick6Button10PressedStatus "Joystick 6 Button 10 Pressed Status: Reports when the joystick button has been pressed.00b = Button not pressed01b = Button pressed10b = Error Indicator11b = Not Available";
CM_ SG_ 2365402366 Joystick6Button11PressedStatus "Joystick 6 Button 11 Pressed Status: Reports when the joystick button has been pressed.00b = Button not pressed01b = Button pressed10b = Error Indicator11b = Not Available";
CM_ SG_ 2365402366 Joystick6Button12PressedStatus "Joystick 6 Button 12 Pressed Status: Reports when the joystick button has been pressed.00b = Button not pressed01b = Button pressed10b = Error Indicator11b = Not Available";
CM_ SG_ 2365402366 Joystick6Button1PressedStatus "Joystick 6 Button 1 Pressed Status: Reports when the joystick button has been pressed.00b = Button not pressed01b = Button pressed10b = Error Indicator11b = Not Available";
CM_ SG_ 2365402366 Joystick6Button2PressedStatus "Joystick 6 Button 2 Pressed Status: Reports when the joystick button has been pressed.00b = Button not pressed01b = Button pressed10b = Error Indicator11b = Not Available";
CM_ SG_ 2365402366 Joystick6Button3PressedStatus "Joystick 6 Button 3 Pressed Status: Reports when the joystick button has been pressed.00b = Button not pressed01b = Button pressed10b = Error Indicator11b = Not Available";
CM_ SG_ 2365402366 Joystick6Button4PressedStatus "Joystick 6 Button 4 Pressed Status: Reports when the joystick button has been pressed.00b = Button not pressed01b = Button pressed10b = Error Indicator11b = Not Available";
CM_ SG_ 2365402366 Joystick6Button5PressedStatus "Joystick 6 Button 5 Pressed Status: Reports when the joystick button has been pressed.00b = Button not pressed01b = Button pressed10b = Error Indicator11b = Not Available";
CM_ SG_ 2365402366 Joystick6Button6PressedStatus "Joystick 6 Button 6 Pressed Status: Reports when the joystick button has been pressed.00b = Button not pressed01b = Button pressed10b = Error Indicator11b = Not Available";
CM_ SG_ 2365402366 Joystick6Button7PressedStatus "Joystick 6 Button 7 Pressed Status: Reports when the joystick button has been pressed.00b = Button not pressed01b = Button pressed10b = Error Indicator11b = Not Available";
CM_ SG_ 2365402366 Joystick6Button8PressedStatus "Joystick 6 Button 8 Pressed Status: Reports when the joystick button has been pressed.00b = Button not pressed01b = Button pressed10b = Error Indicator11b = Not Available";
CM_ SG_ 2365402366 Joystick6Button9PressedStatus "Joystick 6 Button 9 Pressed Status: Reports when the joystick button has been pressed.00b = Button not pressed01b = Button pressed10b = Error Indicator11b = Not Available";
CM_ SG_ 2365402366 Joystick6XAxisPosition "Joystick 6 X-Axis Position: The position of the joystick in the relative motion of travel from the neutral position.  Position value of 0 is Neutral and position value 1000 (100%) is the end of linear zone.  Value of 1022 indicates an error has occur...";
CM_ SG_ 2365402366 Joystick6YAxisPosition "Joystick 6 Y-Axis Position: The position of the joystick in the relative motion of travel from the neutral position.  Position value of 0 is Neutral and position value 1000 (100%) is the end of linear zone.  Value of 1022 indicates an error has occur...";
CM_ SG_ 2365402366 Jstk6XAxsDtntPstnStts "Joystick 6 X-Axis Detent Position Status: Reports when the current joystick position is in the detent position for that axis of travel.00b = Not in the Detent Position01b = In the Detent Position10b = Error Indicator11b = Not Available";
CM_ SG_ 2365402366 Jstk6XAxsLvrLftNgtvPstnStts "Joystick 6 X-Axis Lever Left Negative Position Status: Reports when the current joystick position is on the negative travel side (back, left, counterclockwise, down) relative to the neutral position for that axis of travel. 00b = Not on negative side...";
CM_ SG_ 2365402366 Jstk6XAxsLvrRghtPstvPstnStts "Joystick 6 X-Axis Lever Right Positive Position Status: Reports when the current joystick position is on the positive travel side (forward, right, clockwise, up) relative to the neutral position for that axis of travel. 00b = Not on Positive side of ...";
CM_ SG_ 2365402366 Jstk6XAxsNtrlPstnStts "Joystick 6 X-Axis Neutral Position Status: Reports when the current joystick position is in the neutral position for that axis of travel.  The neutral position measurement must be determined from some mechanism other than the axis position measuremen...";
CM_ SG_ 2365402366 Jstk6YAxsDtntPstnStts "Joystick 6 Y-Axis Detent Position Status: Reports when the current joystick position is in the detent position for that axis of travel.00b = Not in the Detent Position01b = In the Detent Position10b = Error Indicator11b = Not Available";
CM_ SG_ 2365402366 Jstk6YAxsLvrBkNgtvPstnStts "Joystick 6 Y-Axis Lever Back Negative Position Status: Reports when the current joystick position is on the negative travel side (back, left, counterclockwise, down) relative to the neutral position for that axis of travel. 00b = Not on negative side...";
CM_ SG_ 2365402366 Jstk6YAxsLvrFrwrdPstvPstnStts "Joystick 6 Y-Axis Lever Forward Positive Position Status: Reports when the current joystick position is on the positive travel side (forward, right, clockwise, up) relative to the neutral position for that axis of travel. 00b = Not on Positive side o...";
CM_ SG_ 2365402366 Jstk6YAxsNtrlPstnStts "Joystick 6 Y-Axis Neutral Position Status: Reports when the current joystick position is in the neutral position for that axis of travel.  The neutral position measurement must be determined from some mechanism other than the axis position measuremen...";
CM_ BO_ 2365402622 "Extended Joystick Message 5";
CM_ SG_ 2365402622 Joystick5Button13PressedStatus "Joystick 5 Button 13 Pressed Status: Reports when the joystick button has been pressed.00b = Button not pressed01b = Button pressed10b = Error Indicator11b = Not Available";
CM_ SG_ 2365402622 Joystick5Button14PressedStatus "Joystick 5 Button 14 Pressed Status: Reports when the joystick button has been pressed.00b = Button not pressed01b = Button pressed10b = Error Indicator11b = Not Available";
CM_ SG_ 2365402622 Joystick5Button15PressedStatus "Joystick 5 Button 15 Pressed Status: Reports when the joystick button has been pressed.00b = Button not pressed01b = Button pressed10b = Error Indicator11b = Not Available";
CM_ SG_ 2365402622 Joystick5Button16PressedStatus "Joystick 5 Button 16 Pressed Status: Reports when the joystick button has been pressed.00b = Button not pressed01b = Button pressed10b = Error Indicator11b = Not Available";
CM_ SG_ 2365402622 Joystick5GripXAxisPosition "Joystick 5 Grip X-Axis Position: The position of the joystick grip in the relative motion of travel from the neutral position.  Position value of 0 is Neutral and position value 1000 (100%) is the end of linear zone.  Value of 1022 indicates an error...";
CM_ SG_ 2365402622 Joystick5GripYAxisPosition "Joystick 5 Grip Y-Axis Position: The position of the joystick grip in the relative motion of travel from the neutral position.  Position value of 0 is Neutral and position value 1000 (100%) is the end of linear zone.  Value of 1022 indicates an error...";
CM_ SG_ 2365402622 Joystick5ThetaAxisPosition "Joystick 5 Theta-Axis Position: The position of the joystick in the relative motion of travel from the neutral position.  Position value of 0 is Neutral and position value 1000 (100%) is the end of linear zone.  Value of 1022 indicates an error has o...";
CM_ SG_ 2365402622 Jst5GpYAxsLvFwdPstvPstStts "Joystick 5 Grip Y-Axis Lever Forward Positive Position Status: Reports when the current joystick grip position is on the positive travel side (forward, right, clockwise, up) relative to the neutral position for that axis of travel. 00b = Not on Posit...";
CM_ SG_ 2365402622 Jst5TtAxsCtCwsNtvPstStts "Joystick 5 Theta-Axis Counter Clockwise Negative Position Status: Reports when the current joystick position is on the negative travel side (back, left, counterclockwise, down) relative to the neutral position for that axis of travel. 00b = Not on ne...";
CM_ SG_ 2365402622 Jstk5GrpXAxsDtntPstnStts "Joystick 5 Grip X-Axis Detent Position Status: Reports when the current joystick grip position is in the detent position for that axis of travel.00b = Not in the Detent Position01b = In the Detent Position10b = Error Indicator11b = Not Available...";
CM_ SG_ 2365402622 Jstk5GrpXAxsLvrLftNgtvPstnStts "Joystick 5 Grip X-Axis Lever Left Negative Position Status: Reports when the current joystick grip position is on the negative travel side (back, left, counterclockwise, down) relative to the neutral position for that axis of travel. 00b = Not on neg...";
CM_ SG_ 2365402622 Jstk5GrpXAxsLvrRghtPstvPstnStts "Joystick 5 Grip X-Axis Lever Right Positive Position Status: Reports when the current joystick grip position is on the positive travel side (forward, right, clockwise, up) relative to the neutral position for that axis of travel. 00b = Not on Positiv...";
CM_ SG_ 2365402622 Jstk5GrpXAxsNtrlPstnStts "Joystick 5 Grip X-Axis Neutral Position Status: Reports when the current joystick grip position is in the neutral position for that axis of travel.  The neutral position measurement must be determined from some mechanism other than the axis position ...";
CM_ SG_ 2365402622 Jstk5GrpYAxsDtntPstnStts "Joystick 5 Grip Y-Axis Detent Position Status: Reports when the current joystick grip position is in the detent position for that axis of travel.00b = Not in the Detent Position01b = In the Detent Position10b = Error Indicator11b = Not Available...";
CM_ SG_ 2365402622 Jstk5GrpYAxsLvrBkNgtvPstnStts "Joystick 5 Grip Y-Axis Lever Back Negative Position Status: Reports when the current joystick grip position is on the negative travel side (back, left, counterclockwise, down) relative to the neutral position for that axis of travel. 00b = Not on neg...";
CM_ SG_ 2365402622 Jstk5GrpYAxsNtrlPstnStts "Joystick 5 Grip Y-Axis Neutral Position Status: Reports when the current joystick grip position is in the neutral position for that axis of travel.  The neutral position measurement must be determined from some mechanism other than the axis position ...";
CM_ SG_ 2365402622 Jstk5ThtAxsClkwsPstvPstnStts "Joystick 5 Theta-Axis Clockwise Positive Position Status: Reports when the current joystick position is on the positive travel side (forward, right, clockwise, up) relative to the neutral position for that axis of travel. 00b = Not on Positive side o...";
CM_ SG_ 2365402622 Jstk5ThtAxsDtntPstnStts "Joystick 5 Theta-Axis Detent Position Status: Reports when the current joystick position is in the detent position for that axis of travel.00b = Not in the Detent Position01b = In the Detent Position10b = Error Indicator11b = Not Available";
CM_ SG_ 2365402622 Jstk5ThtAxsNtrlPstnStts "Joystick 5 Theta-Axis Neutral Position Status: Reports when the current joystick position is in the neutral position for that axis of travel.  The neutral position measurement must be determined from some mechanism other than the axis position measur...";
CM_ BO_ 2365402878 "Basic Joystick Message 5";
CM_ SG_ 2365402878 Joystick5Button10PressedStatus "Joystick 5 Button 10 Pressed Status: Reports when the joystick button has been pressed.00b = Button not pressed01b = Button pressed10b = Error Indicator11b = Not Available";
CM_ SG_ 2365402878 Joystick5Button11PressedStatus "Joystick 5 Button 11 Pressed Status: Reports when the joystick button has been pressed.00b = Button not pressed01b = Button pressed10b = Error Indicator11b = Not Available";
CM_ SG_ 2365402878 Joystick5Button12PressedStatus "Joystick 5 Button 12 Pressed Status: Reports when the joystick button has been pressed.00b = Button not pressed01b = Button pressed10b = Error Indicator11b = Not Available";
CM_ SG_ 2365402878 Joystick5Button1PressedStatus "Joystick 5 Button 1 Pressed Status: Reports when the joystick button has been pressed.00b = Button not pressed01b = Button pressed10b = Error Indicator11b = Not Available";
CM_ SG_ 2365402878 Joystick5Button2PressedStatus "Joystick 5 Button 2 Pressed Status: Reports when the joystick button has been pressed.00b = Button not pressed01b = Button pressed10b = Error Indicator11b = Not Available";
CM_ SG_ 2365402878 Joystick5Button3PressedStatus "Joystick 5 Button 3 Pressed Status: Reports when the joystick button has been pressed.00b = Button not pressed01b = Button pressed10b = Error Indicator11b = Not Available";
CM_ SG_ 2365402878 Joystick5Button4PressedStatus "Joystick 5 Button 4 Pressed Status: Reports when the joystick button has been pressed.00b = Button not pressed01b = Button pressed10b = Error Indicator11b = Not Available";
CM_ SG_ 2365402878 Joystick5Button5PressedStatus "Joystick 5 Button 5 Pressed Status: Reports when the joystick button has been pressed.00b = Button not pressed01b = Button pressed10b = Error Indicator11b = Not Available";
CM_ SG_ 2365402878 Joystick5Button6PressedStatus "Joystick 5 Button 6 Pressed Status: Reports when the joystick button has been pressed.00b = Button not pressed01b = Button pressed10b = Error Indicator11b = Not Available";
CM_ SG_ 2365402878 Joystick5Button7PressedStatus "Joystick 5 Button 7 Pressed Status: Reports when the joystick button has been pressed.00b = Button not pressed01b = Button pressed10b = Error Indicator11b = Not Available";
CM_ SG_ 2365402878 Joystick5Button8PressedStatus "Joystick 5 Button 8 Pressed Status: Reports when the joystick button has been pressed.00b = Button not pressed01b = Button pressed10b = Error Indicator11b = Not Available";
CM_ SG_ 2365402878 Joystick5Button9PressedStatus "Joystick 5 Button 9 Pressed Status: Reports when the joystick button has been pressed.00b = Button not pressed01b = Button pressed10b = Error Indicator11b = Not Available";
CM_ SG_ 2365402878 Joystick5XAxisPosition "Joystick 5 X-Axis Position: The position of the joystick in the relative motion of travel from the neutral position.  Position value of 0 is Neutral and position value 1000 (100%) is the end of linear zone.  Value of 1022 indicates an error has occur...";
CM_ SG_ 2365402878 Joystick5YAxisPosition "Joystick 5 Y-Axis Position: The position of the joystick in the relative motion of travel from the neutral position.  Position value of 0 is Neutral and position value 1000 (100%) is the end of linear zone.  Value of 1022 indicates an error has occur...";
CM_ SG_ 2365402878 Jstk5XAxsDtntPstnStts "Joystick 5 X-Axis Detent Position Status: Reports when the current joystick position is in the detent position for that axis of travel.00b = Not in the Detent Position01b = In the Detent Position10b = Error Indicator11b = Not Available";
CM_ SG_ 2365402878 Jstk5XAxsLvrLftNgtvPstnStts "Joystick 5 X-Axis Lever Left Negative Position Status: Reports when the current joystick position is on the negative travel side (back, left, counterclockwise, down) relative to the neutral position for that axis of travel. 00b = Not on negative side...";
CM_ SG_ 2365402878 Jstk5XAxsLvrRghtPstvPstnStts "Joystick 5 X-Axis Lever Right Positive Position Status: Reports when the current joystick position is on the positive travel side (forward, right, clockwise, up) relative to the neutral position for that axis of travel. 00b = Not on Positive side of ...";
CM_ SG_ 2365402878 Jstk5XAxsNtrlPstnStts "Joystick 5 X-Axis Neutral Position Status: Reports when the current joystick position is in the neutral position for that axis of travel.  The neutral position measurement must be determined from some mechanism other than the axis position measuremen...";
CM_ SG_ 2365402878 Jstk5YAxsDtntPstnStts "Joystick 5 Y-Axis Detent Position Status: Reports when the current joystick position is in the detent position for that axis of travel.00b = Not in the Detent Position01b = In the Detent Position10b = Error Indicator11b = Not Available";
CM_ SG_ 2365402878 Jstk5YAxsLvrBkNgtvPstnStts "Joystick 5 Y-Axis Lever Back Negative Position Status: Reports when the current joystick position is on the negative travel side (back, left, counterclockwise, down) relative to the neutral position for that axis of travel. 00b = Not on negative side...";
CM_ SG_ 2365402878 Jstk5YAxsLvrFrwrdPstvPstnStts "Joystick 5 Y-Axis Lever Forward Positive Position Status: Reports when the current joystick position is on the positive travel side (forward, right, clockwise, up) relative to the neutral position for that axis of travel. 00b = Not on Positive side o...";
CM_ SG_ 2365402878 Jstk5YAxsNtrlPstnStts "Joystick 5 Y-Axis Neutral Position Status: Reports when the current joystick position is in the neutral position for that axis of travel.  The neutral position measurement must be determined from some mechanism other than the axis position measuremen...";
CM_ BO_ 2365403134 "Extended Joystick Message 4";
CM_ SG_ 2365403134 Joystick4Button13PressedStatus "Joystick 4 Button 13 Pressed Status: Reports when the joystick button has been pressed.00b = Button not pressed01b = Button pressed10b = Error Indicator11b = Not Available";
CM_ SG_ 2365403134 Joystick4Button14PressedStatus "Joystick 4 Button 14 Pressed Status: Reports when the joystick button has been pressed.00b = Button not pressed01b = Button pressed10b = Error Indicator11b = Not Available";
CM_ SG_ 2365403134 Joystick4Button15PressedStatus "Joystick 4 Button 15 Pressed Status: Reports when the joystick button has been pressed.00b = Button not pressed01b = Button pressed10b = Error Indicator11b = Not Available";
CM_ SG_ 2365403134 Joystick4Button16PressedStatus "Joystick 4 Button 16 Pressed Status: Reports when the joystick button has been pressed.00b = Button not pressed01b = Button pressed10b = Error Indicator11b = Not Available";
CM_ SG_ 2365403134 Joystick4GripXAxisPosition "Joystick 4 Grip X-Axis Position: The position of the joystick grip in the relative motion of travel from the neutral position.  Position value of 0 is Neutral and position value 1000 (100%) is the end of linear zone.  Value of 1022 indicates an error...";
CM_ SG_ 2365403134 Joystick4GripYAxisPosition "Joystick 4 Grip Y-Axis Position: The position of the joystick grip in the relative motion of travel from the neutral position.  Position value of 0 is Neutral and position value 1000 (100%) is the end of linear zone.  Value of 1022 indicates an error...";
CM_ SG_ 2365403134 Joystick4ThetaAxisPosition "Joystick 4 Theta-Axis Position: The position of the joystick in the relative motion of travel from the neutral position.  Position value of 0 is Neutral and position value 1000 (100%) is the end of linear zone.  Value of 1022 indicates an error has o...";
CM_ SG_ 2365403134 Jst4GpYAxsLvFwdPstvPstStts "Joystick 4 Grip Y-Axis Lever Forward Positive Position Status: Reports when the current joystick grip position is on the positive travel side (forward, right, clockwise, up) relative to the neutral position for that axis of travel. 00b = Not on Posit...";
CM_ SG_ 2365403134 Jst4TtAxsCtCwsNtvPstStts "Joystick 4 Theta-Axis Counter Clockwise Negative Position Status: Reports when the current joystick position is on the negative travel side (back, left, counterclockwise, down) relative to the neutral position for that axis of travel. 00b = Not on ne...";
CM_ SG_ 2365403134 Jstk4GrpXAxsDtntPstnStts "Joystick 4 Grip X-Axis Detent Position Status: Reports when the current joystick grip position is in the detent position for that axis of travel.00b = Not in the Detent Position01b = In the Detent Position10b = Error Indicator11b = Not Available...";
CM_ SG_ 2365403134 Jstk4GrpXAxsLvrLftNgtvPstnStts "Joystick 4 Grip X-Axis Lever Left Negative Position Status: Reports when the current joystick grip position is on the negative travel side (back, left, counterclockwise, down) relative to the neutral position for that axis of travel. 00b = Not on neg...";
CM_ SG_ 2365403134 Jstk4GrpXAxsLvrRghtPstvPstnStts "Joystick 4 Grip X-Axis Lever Right Positive Position Status: Reports when the current joystick grip position is on the positive travel side (forward, right, clockwise, up) relative to the neutral position for that axis of travel. 00b = Not on Positiv...";
CM_ SG_ 2365403134 Jstk4GrpXAxsNtrlPstnStts "Joystick 4 Grip X-Axis Neutral Position Status: Reports when the current joystick grip position is in the neutral position for that axis of travel.  The neutral position measurement must be determined from some mechanism other than the axis position ...";
CM_ SG_ 2365403134 Jstk4GrpYAxsDtntPstnStts "Joystick 4 Grip Y-Axis Detent Position Status: Reports when the current joystick grip position is in the detent position for that axis of travel.00b = Not in the Detent Position01b = In the Detent Position10b = Error Indicator11b = Not Available...";
CM_ SG_ 2365403134 Jstk4GrpYAxsLvrBkNgtvPstnStts "Joystick 4 Grip Y-Axis Lever Back Negative Position Status: Reports when the current joystick grip position is on the negative travel side (back, left, counterclockwise, down) relative to the neutral position for that axis of travel. 00b = Not on neg...";
CM_ SG_ 2365403134 Jstk4GrpYAxsNtrlPstnStts "Joystick 4 Grip Y-Axis Neutral Position Status: Reports when the current joystick grip position is in the neutral position for that axis of travel.  The neutral position measurement must be determined from some mechanism other than the axis position ...";
CM_ SG_ 2365403134 Jstk4ThtAxsClkwsPstvPstnStts "Joystick 4 Theta-Axis Clockwise Positive Position Status: Reports when the current joystick position is on the positive travel side (forward, right, clockwise, up) relative to the neutral position for that axis of travel. 00b = Not on Positive side o...";
CM_ SG_ 2365403134 Jstk4ThtAxsDtntPstnStts "Joystick 4 Theta-Axis Detent Position Status: Reports when the current joystick position is in the detent position for that axis of travel.00b = Not in the Detent Position01b = In the Detent Position10b = Error Indicator11b = Not Available";
CM_ SG_ 2365403134 Jstk4ThtAxsNtrlPstnStts "Joystick 4 Theta-Axis Neutral Position Status: Reports when the current joystick position is in the neutral position for that axis of travel.  The neutral position measurement must be determined from some mechanism other than the axis position measur...";
CM_ BO_ 2365403390 "Basic Joystick Message 4";
CM_ SG_ 2365403390 Joystick4Button10PressedStatus "Joystick 4 Button 10 Pressed Status: Reports when the joystick button has been pressed.00b = Button not pressed01b = Button pressed10b = Error Indicator11b = Not Available";
CM_ SG_ 2365403390 Joystick4Button11PressedStatus "Joystick 4 Button 11 Pressed Status: Reports when the joystick button has been pressed.00b = Button not pressed01b = Button pressed10b = Error Indicator11b = Not Available";
CM_ SG_ 2365403390 Joystick4Button12PressedStatus "Joystick 4 Button 12 Pressed Status: Reports when the joystick button has been pressed.00b = Button not pressed01b = Button pressed10b = Error Indicator11b = Not Available";
CM_ SG_ 2365403390 Joystick4Button1PressedStatus "Joystick 4 Button 1 Pressed Status: Reports when the joystick button has been pressed.00b = Button not pressed01b = Button pressed10b = Error Indicator11b = Not Available";
CM_ SG_ 2365403390 Joystick4Button2PressedStatus "Joystick 4 Button 2 Pressed Status: Reports when the joystick button has been pressed.00b = Button not pressed01b = Button pressed10b = Error Indicator11b = Not Available";
CM_ SG_ 2365403390 Joystick4Button3PressedStatus "Joystick 4 Button 3 Pressed Status: Reports when the joystick button has been pressed.00b = Button not pressed01b = Button pressed10b = Error Indicator11b = Not Available";
CM_ SG_ 2365403390 Joystick4Button4PressedStatus "Joystick 4 Button 4 Pressed Status: Reports when the joystick button has been pressed.00b = Button not pressed01b = Button pressed10b = Error Indicator11b = Not Available";
CM_ SG_ 2365403390 Joystick4Button5PressedStatus "Joystick 4 Button 5 Pressed Status: Reports when the joystick button has been pressed.00b = Button not pressed01b = Button pressed10b = Error Indicator11b = Not Available";
CM_ SG_ 2365403390 Joystick4Button6PressedStatus "Joystick 4 Button 6 Pressed Status: Reports when the joystick button has been pressed.00b = Button not pressed01b = Button pressed10b = Error Indicator11b = Not Available";
CM_ SG_ 2365403390 Joystick4Button7PressedStatus "Joystick 4 Button 7 Pressed Status: Reports when the joystick button has been pressed.00b = Button not pressed01b = Button pressed10b = Error Indicator11b = Not Available";
CM_ SG_ 2365403390 Joystick4Button8PressedStatus "Joystick 4 Button 8 Pressed Status: Reports when the joystick button has been pressed.00b = Button not pressed01b = Button pressed10b = Error Indicator11b = Not Available";
CM_ SG_ 2365403390 Joystick4Button9PressedStatus "Joystick 4 Button 9 Pressed Status: Reports when the joystick button has been pressed.00b = Button not pressed01b = Button pressed10b = Error Indicator11b = Not Available";
CM_ SG_ 2365403390 Joystick4XAxisPosition "Joystick 4 X-Axis Position: The position of the joystick in the relative motion of travel from the neutral position.  Position value of 0 is Neutral and position value 1000 (100%) is the end of linear zone.  Value of 1022 indicates an error has occur...";
CM_ SG_ 2365403390 Joystick4YAxisPosition "Joystick 4 Y-Axis Position: The position of the joystick in the relative motion of travel from the neutral position.  Position value of 0 is Neutral and position value 1000 (100%) is the end of linear zone.  Value of 1022 indicates an error has occur...";
CM_ SG_ 2365403390 Jstk4XAxsDtntPstnStts "Joystick 4 X-Axis Detent Position Status: Reports when the current joystick position is in the detent position for that axis of travel.00b = Not in the Detent Position01b = In the Detent Position10b = Error Indicator11b = Not Available";
CM_ SG_ 2365403390 Jstk4XAxsLvrLftNgtvPstnStts "Joystick 4 X-Axis Lever Left Negative Position Status: Reports when the current joystick position is on the negative travel side (back, left, counterclockwise, down) relative to the neutral position for that axis of travel. 00b = Not on negative side...";
CM_ SG_ 2365403390 Jstk4XAxsLvrRghtPstvPstnStts "Joystick 4 X-Axis Lever Right Positive Position Status: Reports when the current joystick position is on the positive travel side (forward, right, clockwise, up) relative to the neutral position for that axis of travel. 00b = Not on Positive side of ...";
CM_ SG_ 2365403390 Jstk4XAxsNtrlPstnStts "Joystick 4 X-Axis Neutral Position Status: Reports when the current joystick position is in the neutral position for that axis of travel.  The neutral position measurement must be determined from some mechanism other than the axis position measuremen...";
CM_ SG_ 2365403390 Jstk4YAxsDtntPstnStts "Joystick 4 Y-Axis Detent Position Status: Reports when the current joystick position is in the detent position for that axis of travel.00b = Not in the Detent Position01b = In the Detent Position10b = Error Indicator11b = Not Available";
CM_ SG_ 2365403390 Jstk4YAxsLvrBkNgtvPstnStts "Joystick 4 Y-Axis Lever Back Negative Position Status: Reports when the current joystick position is on the negative travel side (back, left, counterclockwise, down) relative to the neutral position for that axis of travel. 00b = Not on negative side...";
CM_ SG_ 2365403390 Jstk4YAxsLvrFrwrdPstvPstnStts "Joystick 4 Y-Axis Lever Forward Positive Position Status: Reports when the current joystick position is on the positive travel side (forward, right, clockwise, up) relative to the neutral position for that axis of travel. 00b = Not on Positive side o...";
CM_ SG_ 2365403390 Jstk4YAxsNtrlPstnStts "Joystick 4 Y-Axis Neutral Position Status: Reports when the current joystick position is in the neutral position for that axis of travel.  The neutral position measurement must be determined from some mechanism other than the axis position measuremen...";
CM_ BO_ 2365428478 "Engine Operating Information";
CM_ SG_ 2365428478 EngineControlledShutdownRequest "Engine Controlled Shutdown Request: A signal issued by the engine control system to a user or external system requesting for a controlled shutdown.  This request is made when engine protection diagnostics determine a condition warrants a shutdown soo...";
CM_ SG_ 2365428478 EngineCoolantPumpControl "Engine Coolant Pump Control: Control setting for an electrically actuated engine coolant circulating pump. 00b = Off01b = On10b = Reserved11b = Don't care / take no action.";
CM_ SG_ 2365428478 EngineDerateRequest "Engine Derate Request: This parameter is a derate request made from the engine control system to an external system, where the engine is requesting an external device to reduce the load being applied.  A zero value indicates that there is no derate b...";
CM_ SG_ 2365428478 EngineDesiredTorqueRequest "Engine Desired Torque Request: This is the torque that the ECM desires to provide. It is a request made from the ECM to an external system. A valid value within the operating range indicates the engine is requesting an external controller to change t...";
CM_ SG_ 2365428478 EngineFuelShutoff1Control "Engine Fuel Shutoff 1 Control: Control setting for fuel shutoff 1.  The second instance is SPN 2807.  For a single fuel shutoff system, this represents its commanded position.  For a dual fuel shutoff system, this SP is representative of the upstream...";
CM_ SG_ 2365428478 EngineFuelShutoff2Control "Engine Fuel Shutoff 2 Control: Control setting for fuel shutoff 2.  First instance is SPN 632.  For a dual fuel shutoff system, this SP is representative of the downstream fuel shutoff commanded position.  When fuel (gas) is desired at the engine, th...";
CM_ SG_ 2365428478 EngineFuelShutoffVentControl "Engine Fuel Shutoff Vent Control: Control setting for a fuel shutoff vent.  Typically, for a dual fuel shutoff system, the vent line is located between them and is plumbed to vent outside to atmosphere.  The vent control typically always actuates opp...";
CM_ SG_ 2365428478 EngineOilPreheaterControl "Engine Oil Pre-heater Control: Control setting for an electrically actuated oil pre-heating device.00b = Off01b = On10b = Reserved11b = Don't care / take no actionIn addition to communicating desired action of the electrically actuated oil pre-heater...";
CM_ SG_ 2365428478 EngineOilPrimingPumpControl "Engine Oil Priming Pump Control: This control is used to activate a pump that lubricates the engine, particularly prior to initial engine startup.00b = Off01b = On10b = Reserved11b = unavailable";
CM_ SG_ 2365428478 EngineOperatingState "Engine Operating State: This parameter is used to indicate the current state, or mode, of operation by the engine.  This is a status parameter.0000b = Engine Stopped0001b = Pre-Start0010b = Starting0011b = Warm-Up0100b = Running0101b = Cool-down0110b...";
CM_ SG_ 2365428478 EnginePreHeaterControl "Engine Pre-Heater Control: Control setting for an electrically actuated engine block or coolant pre-heating device.00b = Off 01b = On10b = Reserved11b = Unavailable";
CM_ SG_ 2365428478 EngineStarterMotorRelayControl "Engine Starter Motor Relay Control: Command signal used to energize or de-energize the engine starter motor relay.00b = Off01b = On10b = Reserved for SAE assignment11b = Don't care/take no action";
CM_ SG_ 2365428478 EngnCldAmntElvtdIdlStts "Engine Cold Ambient Elevated Idle Status: Indicates that the engine is elevating the idle speed due to cold strategies.00b = No Idle Elevation Active - standard idle speed01b = Idle Elevation Active10b = Reserved for SAE assignment11b = Unavailable...";
CM_ SG_ 2365428478 EngnEltrlSstmPwrCnsrvtnCntrl "Engine Electrical System Power Conservation Control: Control setting for cutting power to various devices when the engine is not in use.  Useful if it is desired to keep the engine in standby, with main control ECU still powered on and communictaing ...";
CM_ SG_ 2365428478 EngnEmrgnImmdtShtdwnIndtn "Engine Emergency (Immediate) Shutdown Indication: A signal issued by the engine control system to a user or external system indicating that it is immediately shutting the engine down.  This indication is made when engine protection diagnostics determ...";
CM_ SG_ 2365428478 EngnFlShtffVlvLkTstCntrl "Engine Fuel Shutoff Valve Leak Test Control: Control setting for fuel shutoff valve proving system test.  Typically, this type of system can only be used with a dual fuel shutoff system.  The test consists of a small pump to pressurize the chamber be...";
CM_ SG_ 2365428478 FuelPumpPrimerControl "Fuel Pump Primer Control: Parameter used to activate or deactivate a priming system on the fuel transfer system. The fuel priming system is a system that purges air in the fuel lines and may assist fuel delivery to a second pump at lower speeds.00b =...";
CM_ SG_ 2365428478 TmRmnngnEngnOprtngStt "Time Remaining in Engine Operating State: This parameter is used to indicate the time remaining in the current engine operating state, based on the state defined in the SP Engine Operating State (SPN 3543). For the states in which time remaining is n...";
CM_ BO_ 2365428734 "Generator Control 1";
CM_ SG_ 2365428734 EngineSpeedGovernorDroop "Engine Speed Governor Droop: This is the percent speed droop adjustment relative to rated speed setpoint. The Engine Speed Droop is equal to the following equation: 100*[(Engine Speed at no load - Engine Speed at full rated load)/ (Engine Speed at fu...";
CM_ SG_ 2365428734 EngineSpeedGovernorGainAdjust "Engine Speed Governor Gain Adjust: This parameter is used to adjust multiple gains at same time to attain engine stability across a broader range of applications.  -32128 is least responsive0 is normal+32127 is most responsive";
CM_ SG_ 2365428734 GeneratorAlternatorEfficiency "Generator Alternator Efficiency: Measured, calculated, and/or estimated operating efficiency of the generator alternator.  Percentage reflects ratio of power output divided by power input, multiplied by 100.";
CM_ SG_ 2365428734 GeneratorFrequencySelection "Generator Frequency Selection: Command from user and/or generator control system for the genset (engine) to target operations for 50 Hz, 60 Hz, or 400 Hz.0000b = 50 Hz0001b = 60 Hz0010b = 400 Hz0011b to 1101b = SAE Reserved1110b = Unknown1111b = Don'...";
CM_ SG_ 2365428734 GeneratorGoverningSpeedCommand "Generator Governing Speed Command: Command from user and/or generator control system for the genset (engine) to govern to low idle or rated base speed setpoints.  If this method of engine control is used, then the PGN 0 (TSC1) is not expected to be r...";
CM_ SG_ 2365428734 GnrtrCntrlNtInAtmtStrtStt "Generator Control Not In Automatic Start State: This parameter indicates whether or not the generator set is in a condition to automatically start up and provide power. If not, this status parameter is in the ACTIVE state.00b = inactive (ready to sta...";
CM_ SG_ 2365428734 GnrtrNtRdtAtmtllPrlllStt "Generator Not Ready to Automatically Parallel State: This parameter indicates whether or not all systems required to start the engine and close to the bus are prepared to operate automatically. If not, the generator is not ready to automatically para...";
CM_ SG_ 2365428734 RequestedEngineControlMode "Requested Engine Control Mode: This parameter is used to request a change to the engine control mode.  This is a status parameter.  0000b = Normal Engine Shutdown0001b = Rapid Engine Shutdown0010b = Emergency Engine Shutdown0011b = Normal Engine Star...";
CM_ BO_ 2365433598 "Voltage Regulator Excitation Status";
CM_ SG_ 2365433598 GeneratorExcitationFieldCurrent "Generator Excitation Field Current: Measured signal that represents the generator excitation field current.";
CM_ SG_ 2365433598 GeneratorExcitationFieldVoltage "Generator Excitation Field Voltage: Measured signal that represents the generator excitation field voltage.  Generator excitation field voltage is indicative of the amount of excitation current being supplied by the voltage regulator to the generator...";
CM_ SG_ 2365433598 GnrtrOtptVltgBsPrntg "Generator Output Voltage Bias Percentage: Measured signal that represents the voltage bias percentage of the generator ouptput voltage being requested by external to the voltage regulator.  Generator output voltage bias percentage is the amount of vo...";
CM_ BO_ 2365443326 "Operators External Light Controls Message";
CM_ SG_ 2365443326 HazardLightSwitch "Hazard Light Switch: A 2 bit parameter to indicate the selected position of the operator's hazard light switch.00b = Hazard Lamps to be Off01b = Hazard Lamps to be Flashing10b = Error11b = Not available (do not change)";
CM_ SG_ 2365443326 HighLowBeamSwitch "High-Low Beam Switch: A 2 bit parameter to indicate the selected position of the operator's high/low beam select switch.00b = Low Beam Selected01b = High Beam Selected10b = Error11b = Not available (do not change)";
CM_ SG_ 2365443326 MainLightSwitch "Main Light Switch: A 4 bit parameter to indicate the selected position of the operator's main light switch.0000b = Off - The position by which the operator selects that none of the lamps are to be on.0001b = Park On - The position by which the operat...";
CM_ SG_ 2365443326 OperatorsDesiredBacklight "Operators Desired Back-light: A 8 bit parameter to indicate the level of back lighting the operator has selected for displays.  This is to be differentiated from the Illumination Brightness Percent (SPN 1487 PGN 53248 Cab Illumination Message) which ...";
CM_ SG_ 2365443326 OprtrsDsrdDldLmpOffTm "Operators Desired - Delayed Lamp Off Time: A 16 bit parameter to be associated with Delayed Off position (1000b) of the Main Light Switch.  This parameter indicates the time the operator wishes to have elapse following the Main Light switch being pla...";
CM_ SG_ 2365443326 TurnSignalSwitch "Turn Signal Switch: A 4 bit parameter to indicate the selected position of the operator's turn signal switch.0000b = No Turn being signaled0001b = Left Turn to be Flashing0010b = Right turn to be Flashing0011b to 1101b = Reserved   1110b = Error (to ...";
CM_ SG_ 2365443326 WorkLightSwitch "Work Light Switch: A 4 bit parameter to indicate the selected position of the operator's work light switch. In Ag applications the work lights are often refereed to as field lights.  In on-highway applications the work lights are often referred to as...";
CM_ SG_ 2365443326 ExteriorLampCheckSwitch "Exterior Lamp Check Switch: Indicates the selected position of the operator's exterior lamp check switch.00b = Exterior lamp check inactive01b = Exterior lamp check active10b = Error11b = Not available";
CM_ SG_ 2365443326 HeadlampEmergencyFlashSwitch "Headlamp Emergency Flash Switch: Indicates the selected position of the headlamp emergency flash (wig-wag) switch.00b = Headlamp emergency flash inactive01b = Headlamp emergency flash active10b = Error11b = Not available";
CM_ BO_ 2365445886 "Basic Joystick Message 1";
CM_ SG_ 2365445886 Joystick1Button10PressedStatus "Joystick 1 Button 10 Pressed Status: Reports when the joystick button has been pressed.00b = Button not pressed01b = Button pressed10b = Error Indicator11b = Not Available";
CM_ SG_ 2365445886 Joystick1Button11PressedStatus "Joystick 1 Button 11 Pressed Status: Reports when the joystick button has been pressed.00b = Button not pressed01b = Button pressed10b = Error Indicator11b = Not Available";
CM_ SG_ 2365445886 Joystick1Button12PressedStatus "Joystick 1 Button 12 Pressed Status: Reports when the joystick button has been pressed.00b = Button not pressed01b = Button pressed10b = Error Indicator11b = Not Available";
CM_ SG_ 2365445886 Joystick1Button1PressedStatus "Joystick 1 Button 1 Pressed Status: Reports when the joystick button has been pressed.00b = Button not pressed01b = Button pressed10b = Error Indicator11b = Not Available";
CM_ SG_ 2365445886 Joystick1Button2PressedStatus "Joystick 1 Button 2 Pressed Status: Reports when the joystick button has been pressed.00b = Button not pressed01b = Button pressed10b = Error Indicator11b = Not Available";
CM_ SG_ 2365445886 Joystick1Button3PressedStatus "Joystick 1 Button 3 Pressed Status: Reports when the joystick button has been pressed.00b = Button not pressed01b = Button pressed10b = Error Indicator11b = Not Available";
CM_ SG_ 2365445886 Joystick1Button4PressedStatus "Joystick 1 Button 4 Pressed Status: Reports when the joystick button has been pressed.00b = Button not pressed01b = Button pressed10b = Error Indicator11b = Not Available";
CM_ SG_ 2365445886 Joystick1Button5PressedStatus "Joystick 1 Button 5 Pressed Status: Reports when the joystick button has been pressed.00b = Button not pressed01b = Button pressed10b = Error Indicator11b = Not Available";
CM_ SG_ 2365445886 Joystick1Button6PressedStatus "Joystick 1 Button 6 Pressed Status: Reports when the joystick button has been pressed.00b = Button not pressed01b = Button pressed10b = Error Indicator11b = Not Available";
CM_ SG_ 2365445886 Joystick1Button7PressedStatus "Joystick 1 Button 7 Pressed Status: Reports when the joystick button has been pressed.00b = Button not pressed01b = Button pressed10b = Error Indicator11b = Not Available";
CM_ SG_ 2365445886 Joystick1Button8PressedStatus "Joystick 1 Button 8 Pressed Status: Reports when the joystick button has been pressed.00b = Button not pressed01b = Button pressed10b = Error Indicator11b = Not Available";
CM_ SG_ 2365445886 Joystick1Button9PressedStatus "Joystick 1 Button 9 Pressed Status: Reports when the joystick button has been pressed.00b = Button not pressed01b = Button pressed10b = Error Indicator11b = Not Available";
CM_ SG_ 2365445886 Joystick1XAxisPosition "Joystick 1 X-Axis Position: The position of the joystick in the relative motion of travel from the neutral position.  Position value of 0 is Neutral and position value 1000 (100%) is the end of linear zone.  Value of 1022 indicates an error has occur...";
CM_ SG_ 2365445886 Joystick1YAxisPosition "Joystick 1 Y-Axis Position: The position of the joystick in the relative motion of travel from the neutral position.  Position value of 0 is Neutral and position value 1000 (100%) is the end of linear zone.  Value of 1022 indicates an error has occur...";
CM_ SG_ 2365445886 Jstk1XAxsDtntPstnStts "Joystick 1 X-Axis Detent Position Status: Reports when the current joystick position is in the detent position for that axis of travel.00b = Not in the Detent Position01b = In the Detent Position10b = Error Indicator11b = Not Available";
CM_ SG_ 2365445886 Jstk1XAxsLvrLftNgtvPstnStts "Joystick 1 X-Axis Lever Left Negative Position Status: Reports when the current joystick position is on the negative travel side (back, left, counterclockwise, down) relative to the neutral position for that axis of travel. 00b = Not on negative side...";
CM_ SG_ 2365445886 Jstk1XAxsLvrRghtPstvPstnStts "Joystick 1 X-Axis Lever Right Positive Position Status: Reports when the current joystick position is on the positive travel side (forward, right, clockwise, up) relative to the neutral position for that axis of travel. 00b = Not on Positive side of ...";
CM_ SG_ 2365445886 Jstk1XAxsNtrlPstnStts "Joystick 1 X-Axis Neutral Position Status: Reports when the current joystick position is in the neutral position for that axis of travel.  The neutral position measurement must be determined from some mechanism other than the axis position measuremen...";
CM_ SG_ 2365445886 Jstk1YAxsDtntPstnStts "Joystick 1 Y-Axis Detent Position Status: Reports when the current joystick position is in the detent position for that axis of travel.00b = Not in the Detent Position01b = In the Detent Position10b = Error Indicator11b = Not Available";
CM_ SG_ 2365445886 Jstk1YAxsLvrBkNgtvPstnStts "Joystick 1 Y-Axis Lever Back Negative Position Status: Reports when the current joystick position is on the negative travel side (back, left, counterclockwise, down) relative to the neutral position for that axis of travel. 00b = Not on negative side...";
CM_ SG_ 2365445886 Jstk1YAxsLvrFrwrdPstvPstnStts "Joystick 1 Y-Axis Lever Forward Positive Position Status: Reports when the current joystick position is on the positive travel side (forward, right, clockwise, up) relative to the neutral position for that axis of travel. 00b = Not on Positive side o...";
CM_ SG_ 2365445886 Jstk1YAxsNtrlPstnStts "Joystick 1 Y-Axis Neutral Position Status: Reports when the current joystick position is in the neutral position for that axis of travel.  The neutral position measurement must be determined from some mechanism other than the axis position measuremen...";
BA_DEF_ SG_  "SPN" INT 0 524287;
BA_DEF_ BO_  "VFrameFormat" ENUM  "StandardCAN","ExtendedCAN","reserved","J1939PG";
BA_DEF_DEF_  "SPN" 0;
BA_DEF_DEF_  "VFrameFormat" "J1939PG";
BA_ "SPN" SG_ 2365308158 DCDC4LwSdCrrntMxmmLmtRqst 9053;
BA_ "SPN" SG_ 2365308158 DCDC4LwSdVltgMnmmLmtRqst 9051;
BA_ "SPN" SG_ 2365308158 DCDC4LwSdVltgMxmmLmtRqst 9052;
BA_ "SPN" SG_ 2365308414 DCDC4HghSdCrrntMxmmLmtRqst 9056;
BA_ "SPN" SG_ 2365308414 DCDC4HghSdVltgMnmmLmtRqst 9054;
BA_ "SPN" SG_ 2365308414 DCDC4HghSdVltgMxmmLmtRqst 9055;
BA_ "SPN" SG_ 2365309182 DCDC3SLIBttrTmprtrMxmmLmtRqst 8990;
BA_ "SPN" SG_ 2365309182 DCDC3SLIBttTCCtMxLtRqst 8989;
BA_ "SPN" SG_ 2365309182 DCDC3SLIBttTVtMxLtRqst 8988;
BA_ "SPN" SG_ 2365309438 DCDC3CnvrtrEltrnFltrTmprtr 8992;
BA_ "SPN" SG_ 2365309438 DCDC3ConverterTemperature 8991;
BA_ "SPN" SG_ 2365309438 DCDC3CoolantInTemperature 8994;
BA_ "SPN" SG_ 2365309438 DCDC3CoolantOutTemperature 8995;
BA_ "SPN" SG_ 2365309438 DCDC3PwrEltrnsTmprtr 8993;
BA_ "SPN" SG_ 2365309694 DCDC3LwSdCrrntMxmmLmtRqst 8998;
BA_ "SPN" SG_ 2365309694 DCDC3LwSdVltgMnmmLmtRqst 8996;
BA_ "SPN" SG_ 2365309694 DCDC3LwSdVltgMxmmLmtRqst 8997;
BA_ "SPN" SG_ 2365309950 DCDC3HghSdCrrntMxmmLmtRqst 9001;
BA_ "SPN" SG_ 2365309950 DCDC3HghSdVltgMnmmLmtRqst 8999;
BA_ "SPN" SG_ 2365309950 DCDC3HghSdVltgMxmmLmtRqst 9000;
BA_ "SPN" SG_ 2365310718 DCDC2SLIBttrTmprtrMxmmLmtRqst 8935;
BA_ "SPN" SG_ 2365310718 DCDC2SLIBttTCCtMxLtRqst 8934;
BA_ "SPN" SG_ 2365310718 DCDC2SLIBttTVtMxLtRqst 8933;
BA_ "SPN" SG_ 2365310974 DCDC2CnvrtrEltrnFltrTmprtr 8937;
BA_ "SPN" SG_ 2365310974 DCDC2ConverterTemperature 8936;
BA_ "SPN" SG_ 2365310974 DCDC2CoolantInTemperature 8939;
BA_ "SPN" SG_ 2365310974 DCDC2CoolantOutTemperature 8940;
BA_ "SPN" SG_ 2365310974 DCDC2PwrEltrnsTmprtr 8938;
BA_ "SPN" SG_ 2365311230 DCDC2LwSdCrrntMxmmLmtRqst 8943;
BA_ "SPN" SG_ 2365311230 DCDC2LwSdVltgMnmmLmtRqst 8941;
BA_ "SPN" SG_ 2365311230 DCDC2LwSdVltgMxmmLmtRqst 8942;
BA_ "SPN" SG_ 2365311486 DCDC2HghSdCrrntMxmmLmtRqst 8946;
BA_ "SPN" SG_ 2365311486 DCDC2HghSdVltgMnmmLmtRqst 8944;
BA_ "SPN" SG_ 2365311486 DCDC2HghSdVltgMxmmLmtRqst 8945;
BA_ "SPN" SG_ 2365313534 DCDC1SLIBttrTmprtrMxmmLmtRqst 8819;
BA_ "SPN" SG_ 2365313534 DCDC1SLIBttTCCtMxLtRqst 8818;
BA_ "SPN" SG_ 2365313534 DCDC1SLIBttTVtMxLtRqst 8817;
BA_ "SPN" SG_ 2365315326 DCDC1CnvrtrEltrnFltrTmprtr 8593;
BA_ "SPN" SG_ 2365315326 DCDC1ConverterTemperature 8592;
BA_ "SPN" SG_ 2365315326 DCDC1CoolantInTemperature 8822;
BA_ "SPN" SG_ 2365315326 DCDC1CoolantOutTemperature 8823;
BA_ "SPN" SG_ 2365315326 DCDC1PwrEltrnsTmprtr 8594;
BA_ "SPN" SG_ 2365315582 DCDC1LwSdCrrntMxmmLmtRqst 8568;
BA_ "SPN" SG_ 2365315582 DCDC1LwSdVltgMnmmLmtRqst 8566;
BA_ "SPN" SG_ 2365315582 DCDC1LwSdVltgMxmmLmtRqst 8567;
BA_ "SPN" SG_ 2365315838 DCDC1HghSdCrrntMxmmLmtRqst 8565;
BA_ "SPN" SG_ 2365315838 DCDC1HghSdVltgMnmmLmtRqst 8563;
BA_ "SPN" SG_ 2365315838 DCDC1HghSdVltgMxmmLmtRqst 8564;
BA_ "SPN" SG_ 2365318910 HVESSFanEnableCommand 8384;
BA_ "SPN" SG_ 2365318910 HVESSFanPowerHold 8385;
BA_ "SPN" SG_ 2365318910 HVESSFanSpeedCommand 8386;
BA_ "SPN" SG_ 2365318910 HVESSFanPercentSpeedCommand 8387;
BA_ "SPN" SG_ 2365318910 HVESSFanInstance1 8388;
BA_ "SPN" SG_ 2365318910 HVESSFanInstance2 8389;
BA_ "SPN" SG_ 2365318910 HVESSFanInstance3 8390;
BA_ "SPN" SG_ 2365318910 HVESSFanInstance4 8391;
BA_ "SPN" SG_ 2365318910 HVESSFanInstance5 8392;
BA_ "SPN" SG_ 2365318910 HVESSFanInstance6 8393;
BA_ "SPN" SG_ 2365318910 HVESSFanInstance7 8394;
BA_ "SPN" SG_ 2365318910 HVESSFanInstance8 8395;
BA_ "SPN" SG_ 2365318910 HVESSFanInstance9 8396;
BA_ "SPN" SG_ 2365318910 HVESSFanInstance10 8397;
BA_ "SPN" SG_ 2365318910 HVESSFanInstance11 8398;
BA_ "SPN" SG_ 2365318910 HVESSFanInstance12 8399;
BA_ "SPN" SG_ 2365318910 HVESSFanInstance13 8400;
BA_ "SPN" SG_ 2365318910 HVESSFanInstance14 8401;
BA_ "SPN" SG_ 2365318910 HVESSFanInstance15 8402;
BA_ "SPN" SG_ 2365322238 DirectionalVehicleSpeed 8166;
BA_ "SPN" SG_ 2365346302 LiftAxle1Status 6843;
BA_ "SPN" SG_ 2365346302 LiftAxle2Status 6844;
BA_ "SPN" SG_ 2365346302 LiftAxle3Status 12298;
BA_ "SPN" SG_ 2365346302 LiftAxle4Status 12299;
BA_ "SPN" SG_ 2365348350 EngineLoadShareStatus 6794;
BA_ "SPN" SG_ 2365348350 EngineUnloadStatus 6793;
BA_ "SPN" SG_ 2365363710 EngnClndrPrssrMntr1PrlmnrFMI 6390;
BA_ "SPN" SG_ 2365363710 EngnClndrPrssrMntr2PrlmnrFMI 6391;
BA_ "SPN" SG_ 2365374206 DlClthTrnsmssnCrrntPrsltnGr 5958;
BA_ "SPN" SG_ 2365374206 DlClthTrnsmssnInptShft1Spd 5960;
BA_ "SPN" SG_ 2365374206 DlClthTrnsmssnInptShft2Spd 5961;
BA_ "SPN" SG_ 2365374206 DlClthTrnsmssnSltdPrsltnGr 5957;
BA_ "SPN" SG_ 2365393662 Aftrtrtmnt2OtltCrrtdNOx 7352;
BA_ "SPN" SG_ 2365393662 Aftrtrtmnt2OtltNOxSnsrNH3Crrtn 5051;
BA_ "SPN" SG_ 2365393662 Aftrtrtmnt2OtltNOxSnsrNO2Crrtn 5050;
BA_ "SPN" SG_ 2365393662 Atttt2OttNOxSsNOxPssCt 5049;
BA_ "SPN" SG_ 2365393662 Atttt2OttNOxSsO2PssCt 5048;
BA_ "SPN" SG_ 2365393662 Atttt2OttNOxSsSdssFRst 5719;
BA_ "SPN" SG_ 2365393918 Aftrtrtmnt2OtltNOxSnsrHtrRt 5045;
BA_ "SPN" SG_ 2365393918 Aftrtrtmnt2OtltNOxSnsrOprtnHrs 5723;
BA_ "SPN" SG_ 2365393918 Atttt2OttNOxSsNwptdvtNOxG 5046;
BA_ "SPN" SG_ 2365393918 Atttt2OttNOxSsNwptdvtNOxOst 5047;
BA_ "SPN" SG_ 2365394174 EngineExhaust2CorrectedNox 7354;
BA_ "SPN" SG_ 2365394174 EngnExhst2NOxSnsrO2PrssrCrrtn 5041;
BA_ "SPN" SG_ 2365394174 EngnExhst2NOxSnsrNOxPrssrCrrtn 5042;
BA_ "SPN" SG_ 2365394174 EngnExhst2NOxSnsrNO2Crrtn 5043;
BA_ "SPN" SG_ 2365394174 EngnExhst2NOxSnsrNH3Crrtn 5044;
BA_ "SPN" SG_ 2365394174 EExst2NOxSsSdssFRst 5720;
BA_ "SPN" SG_ 2365394430 EngnExhst2NOxSnsrHtrRt 5038;
BA_ "SPN" SG_ 2365394430 EngnExhst2NOxSnsrNwPrtDvtnNOxGn 5039;
BA_ "SPN" SG_ 2365394430 EExst2NOxSsNwPtDvtNOxOst 5040;
BA_ "SPN" SG_ 2365394430 EngnExhst2NOxSnsrOprtnHrs 5724;
BA_ "SPN" SG_ 2365394686 Aftrtrtmnt1OtltCrrtdNOx 7351;
BA_ "SPN" SG_ 2365394686 Aftrtrtmnt1OtltNOxSnsrNH3Crrtn 5037;
BA_ "SPN" SG_ 2365394686 Aftrtrtmnt1OtltNOxSnsrNO2Crrtn 5036;
BA_ "SPN" SG_ 2365394686 Atttt1OttNOxSsNOxPssCt 5035;
BA_ "SPN" SG_ 2365394686 Atttt1OttNOxSsO2PssCt 5034;
BA_ "SPN" SG_ 2365394686 Atttt1OttNOxSsSdssFRst 5717;
BA_ "SPN" SG_ 2365394942 Aftrtrtmnt1OtltNOxSnsrHtrRt 5031;
BA_ "SPN" SG_ 2365394942 Aftrtrtmnt1OtltNOxSnsrOprtnHrs 5721;
BA_ "SPN" SG_ 2365394942 Atttt1OttNOxSsNwptdvtNOxG 5032;
BA_ "SPN" SG_ 2365394942 Atttt1OttNOxSsNwptdvtNOxOst 5033;
BA_ "SPN" SG_ 2365395198 EExst1NOxSsSdssFRst 5718;
BA_ "SPN" SG_ 2365395198 EngineExhaust1CorrectedNox 7353;
BA_ "SPN" SG_ 2365395198 EngnExhst1NOxSnsrNH3Crrtn 5030;
BA_ "SPN" SG_ 2365395198 EngnExhst1NOxSnsrNO2Crrtn 5029;
BA_ "SPN" SG_ 2365395198 EngnExhst1NOxSnsrNOxPrssrCrrtn 5028;
BA_ "SPN" SG_ 2365395198 EngnExhst1NOxSnsrO2PrssrCrrtn 5027;
BA_ "SPN" SG_ 2365395454 EExst1NOxSsNwptdvtNOxOst 5026;
BA_ "SPN" SG_ 2365395454 EngnExhst1NOxSnsrHtrRt 5024;
BA_ "SPN" SG_ 2365395454 EngnExhst1NOxSnsrNwprtdvtnNOxGn 5025;
BA_ "SPN" SG_ 2365395454 EngnExhst1NOxSnsrOprtnHrs 5722;
BA_ "SPN" SG_ 2365400062 Joystick10Button13PressedStatus 6767;
BA_ "SPN" SG_ 2365400062 Joystick10Button14PressedStatus 6768;
BA_ "SPN" SG_ 2365400062 Joystick10Button15PressedStatus 6769;
BA_ "SPN" SG_ 2365400062 Joystick10Button16PressedStatus 6770;
BA_ "SPN" SG_ 2365400062 Joystick10GripXAxisPosition 4738;
BA_ "SPN" SG_ 2365400062 Joystick10GripYAxisPosition 4742;
BA_ "SPN" SG_ 2365400062 Joystick10ThetaAxisPosition 4746;
BA_ "SPN" SG_ 2365400062 Jst10GpXAxsLvRtPstvPstStts 4737;
BA_ "SPN" SG_ 2365400062 Jst10GpYAxsLvFwdPstvPstStts 4741;
BA_ "SPN" SG_ 2365400062 Jst10TtAxsCtCwsNtvPstStts 4744;
BA_ "SPN" SG_ 2365400062 Jstk10GrpXAxsDtntPstnStts 4749;
BA_ "SPN" SG_ 2365400062 Jstk10GrpXAxsLvrLftNgtvPstnStts 4736;
BA_ "SPN" SG_ 2365400062 Jstk10GrpXAxsNtrlPstnStts 4735;
BA_ "SPN" SG_ 2365400062 Jstk10GrpYAxsDtntPstnStts 4748;
BA_ "SPN" SG_ 2365400062 Jstk10GrpYAxsLvrBkNgtvPstnStts 4740;
BA_ "SPN" SG_ 2365400062 Jstk10GrpYAxsNtrlPstnStts 4739;
BA_ "SPN" SG_ 2365400062 Jstk10ThtAxsClkwsPstvPstnStts 4745;
BA_ "SPN" SG_ 2365400062 Jstk10ThtAxsDtntPstnStts 4747;
BA_ "SPN" SG_ 2365400062 Jstk10ThtAxsNtrlPstnStts 4743;
BA_ "SPN" SG_ 2365400318 Joystick10Button10PressedStatus 4733;
BA_ "SPN" SG_ 2365400318 Joystick10Button11PressedStatus 4732;
BA_ "SPN" SG_ 2365400318 Joystick10Button12PressedStatus 4731;
BA_ "SPN" SG_ 2365400318 Joystick10Button1PressedStatus 4726;
BA_ "SPN" SG_ 2365400318 Joystick10Button2PressedStatus 4725;
BA_ "SPN" SG_ 2365400318 Joystick10Button3PressedStatus 4724;
BA_ "SPN" SG_ 2365400318 Joystick10Button4PressedStatus 4723;
BA_ "SPN" SG_ 2365400318 Joystick10Button5PressedStatus 4730;
BA_ "SPN" SG_ 2365400318 Joystick10Button6PressedStatus 4729;
BA_ "SPN" SG_ 2365400318 Joystick10Button7PressedStatus 4728;
BA_ "SPN" SG_ 2365400318 Joystick10Button8PressedStatus 4727;
BA_ "SPN" SG_ 2365400318 Joystick10Button9PressedStatus 4734;
BA_ "SPN" SG_ 2365400318 Joystick10XAxisPosition 4716;
BA_ "SPN" SG_ 2365400318 Joystick10YAxisPosition 4720;
BA_ "SPN" SG_ 2365400318 Jstk10XAxsDtntPstnStts 4722;
BA_ "SPN" SG_ 2365400318 Jstk10XAxsLvrLftNgtvPstnStts 4714;
BA_ "SPN" SG_ 2365400318 Jstk10XAxsLvrRghtPstvPstnStts 4715;
BA_ "SPN" SG_ 2365400318 Jstk10XAxsNtrlPstnStts 4713;
BA_ "SPN" SG_ 2365400318 Jstk10YAxsDtntPstnStts 4721;
BA_ "SPN" SG_ 2365400318 Jstk10YAxsLvrBkNgtvPstnStts 4718;
BA_ "SPN" SG_ 2365400318 Jstk10YAxsLvrFrwrdPstvPstnStts 4719;
BA_ "SPN" SG_ 2365400318 Jstk10YAxsNtrlPstnStts 4717;
BA_ "SPN" SG_ 2365400574 Joystick9Button13PressedStatus 6763;
BA_ "SPN" SG_ 2365400574 Joystick9Button14PressedStatus 6764;
BA_ "SPN" SG_ 2365400574 Joystick9Button15PressedStatus 6765;
BA_ "SPN" SG_ 2365400574 Joystick9Button16PressedStatus 6766;
BA_ "SPN" SG_ 2365400574 Joystick9GripXAxisPosition 4701;
BA_ "SPN" SG_ 2365400574 Joystick9GripYAxisPosition 4705;
BA_ "SPN" SG_ 2365400574 Joystick9ThetaAxisPosition 4709;
BA_ "SPN" SG_ 2365400574 Jst9GpYAxsLvFwdPstvPstStts 4704;
BA_ "SPN" SG_ 2365400574 Jst9TtAxsCtCwsNtvPstStts 4707;
BA_ "SPN" SG_ 2365400574 Jstk9GrpXAxsDtntPstnStts 4712;
BA_ "SPN" SG_ 2365400574 Jstk9GrpXAxsLvrLftNgtvPstnStts 4699;
BA_ "SPN" SG_ 2365400574 Jstk9GrpXAxsLvrRghtPstvPstnStts 4700;
BA_ "SPN" SG_ 2365400574 Jstk9GrpXAxsNtrlPstnStts 4698;
BA_ "SPN" SG_ 2365400574 Jstk9GrpYAxsDtntPstnStts 4711;
BA_ "SPN" SG_ 2365400574 Jstk9GrpYAxsLvrBkNgtvPstnStts 4703;
BA_ "SPN" SG_ 2365400574 Jstk9GrpYAxsNtrlPstnStts 4702;
BA_ "SPN" SG_ 2365400574 Jstk9ThtAxsClkwsPstvPstnStts 4708;
BA_ "SPN" SG_ 2365400574 Jstk9ThtAxsDtntPstnStts 4710;
BA_ "SPN" SG_ 2365400574 Jstk9ThtAxsNtrlPstnStts 4706;
BA_ "SPN" SG_ 2365400830 Joystick9Button10PressedStatus 4696;
BA_ "SPN" SG_ 2365400830 Joystick9Button11PressedStatus 4695;
BA_ "SPN" SG_ 2365400830 Joystick9Button12PressedStatus 4694;
BA_ "SPN" SG_ 2365400830 Joystick9Button1PressedStatus 4689;
BA_ "SPN" SG_ 2365400830 Joystick9Button2PressedStatus 4688;
BA_ "SPN" SG_ 2365400830 Joystick9Button3PressedStatus 4687;
BA_ "SPN" SG_ 2365400830 Joystick9Button4PressedStatus 4686;
BA_ "SPN" SG_ 2365400830 Joystick9Button5PressedStatus 4693;
BA_ "SPN" SG_ 2365400830 Joystick9Button6PressedStatus 4692;
BA_ "SPN" SG_ 2365400830 Joystick9Button7PressedStatus 4691;
BA_ "SPN" SG_ 2365400830 Joystick9Button8PressedStatus 4690;
BA_ "SPN" SG_ 2365400830 Joystick9Button9PressedStatus 4697;
BA_ "SPN" SG_ 2365400830 Joystick9XAxisPosition 4679;
BA_ "SPN" SG_ 2365400830 Joystick9YAxisPosition 4683;
BA_ "SPN" SG_ 2365400830 Jstk9XAxsDtntPstnStts 4685;
BA_ "SPN" SG_ 2365400830 Jstk9XAxsLvrLftNgtvPstnStts 4677;
BA_ "SPN" SG_ 2365400830 Jstk9XAxsLvrRghtPstvPstnStts 4678;
BA_ "SPN" SG_ 2365400830 Jstk9XAxsNtrlPstnStts 4676;
BA_ "SPN" SG_ 2365400830 Jstk9YAxsDtntPstnStts 4684;
BA_ "SPN" SG_ 2365400830 Jstk9YAxsLvrBkNgtvPstnStts 4681;
BA_ "SPN" SG_ 2365400830 Jstk9YAxsLvrFrwrdPstvPstnStts 4682;
BA_ "SPN" SG_ 2365400830 Jstk9YAxsNtrlPstnStts 4680;
BA_ "SPN" SG_ 2365401086 Joystick8Button13PressedStatus 6759;
BA_ "SPN" SG_ 2365401086 Joystick8Button14PressedStatus 6760;
BA_ "SPN" SG_ 2365401086 Joystick8Button15PressedStatus 6761;
BA_ "SPN" SG_ 2365401086 Joystick8Button16PressedStatus 6762;
BA_ "SPN" SG_ 2365401086 Joystick8GripXAxisPosition 4664;
BA_ "SPN" SG_ 2365401086 Joystick8GripYAxisPosition 4668;
BA_ "SPN" SG_ 2365401086 Joystick8ThetaAxisPosition 4672;
BA_ "SPN" SG_ 2365401086 Jst8GpYAxsLvFwdPstvPstStts 4667;
BA_ "SPN" SG_ 2365401086 Jst8TtAxsCtCwsNtvPstStts 4670;
BA_ "SPN" SG_ 2365401086 Jstk8GrpXAxsDtntPstnStts 4675;
BA_ "SPN" SG_ 2365401086 Jstk8GrpXAxsLvrLftNgtvPstnStts 4662;
BA_ "SPN" SG_ 2365401086 Jstk8GrpXAxsLvrRghtPstvPstnStts 4663;
BA_ "SPN" SG_ 2365401086 Jstk8GrpXAxsNtrlPstnStts 4661;
BA_ "SPN" SG_ 2365401086 Jstk8GrpYAxsDtntPstnStts 4674;
BA_ "SPN" SG_ 2365401086 Jstk8GrpYAxsLvrBkNgtvPstnStts 4666;
BA_ "SPN" SG_ 2365401086 Jstk8GrpYAxsNtrlPstnStts 4665;
BA_ "SPN" SG_ 2365401086 Jstk8ThtAxsClkwsPstvPstnStts 4671;
BA_ "SPN" SG_ 2365401086 Jstk8ThtAxsDtntPstnStts 4673;
BA_ "SPN" SG_ 2365401086 Jstk8ThtAxsNtrlPstnStts 4669;
BA_ "SPN" SG_ 2365401342 Joystick8Button10PressedStatus 4659;
BA_ "SPN" SG_ 2365401342 Joystick8Button11PressedStatus 4658;
BA_ "SPN" SG_ 2365401342 Joystick8Button12PressedStatus 4657;
BA_ "SPN" SG_ 2365401342 Joystick8Button1PressedStatus 4652;
BA_ "SPN" SG_ 2365401342 Joystick8Button2PressedStatus 4651;
BA_ "SPN" SG_ 2365401342 Joystick8Button3PressedStatus 4650;
BA_ "SPN" SG_ 2365401342 Joystick8Button4PressedStatus 4649;
BA_ "SPN" SG_ 2365401342 Joystick8Button5PressedStatus 4656;
BA_ "SPN" SG_ 2365401342 Joystick8Button6PressedStatus 4655;
BA_ "SPN" SG_ 2365401342 Joystick8Button7PressedStatus 4654;
BA_ "SPN" SG_ 2365401342 Joystick8Button8PressedStatus 4653;
BA_ "SPN" SG_ 2365401342 Joystick8Button9PressedStatus 4660;
BA_ "SPN" SG_ 2365401342 Joystick8XAxisPosition 4642;
BA_ "SPN" SG_ 2365401342 Joystick8YAxisPosition 4646;
BA_ "SPN" SG_ 2365401342 Jstk8XAxsDtntPstnStts 4648;
BA_ "SPN" SG_ 2365401342 Jstk8XAxsLvrLftNgtvPstnStts 4640;
BA_ "SPN" SG_ 2365401342 Jstk8XAxsLvrRghtPstvPstnStts 4641;
BA_ "SPN" SG_ 2365401342 Jstk8XAxsNtrlPstnStts 4639;
BA_ "SPN" SG_ 2365401342 Jstk8YAxsDtntPstnStts 4647;
BA_ "SPN" SG_ 2365401342 Jstk8YAxsLvrBkNgtvPstnStts 4644;
BA_ "SPN" SG_ 2365401342 Jstk8YAxsLvrFrwrdPstvPstnStts 4645;
BA_ "SPN" SG_ 2365401342 Jstk8YAxsNtrlPstnStts 4643;
BA_ "SPN" SG_ 2365401598 Joystick7Button13PressedStatus 6755;
BA_ "SPN" SG_ 2365401598 Joystick7Button14PressedStatus 6756;
BA_ "SPN" SG_ 2365401598 Joystick7Button15PressedStatus 6757;
BA_ "SPN" SG_ 2365401598 Joystick7Button16PressedStatus 6758;
BA_ "SPN" SG_ 2365401598 Joystick7GripXAxisPosition 4627;
BA_ "SPN" SG_ 2365401598 Joystick7GripYAxisPosition 4631;
BA_ "SPN" SG_ 2365401598 Joystick7ThetaAxisPosition 4635;
BA_ "SPN" SG_ 2365401598 Jst7GpYAxsLvFwdPstvPstStts 4630;
BA_ "SPN" SG_ 2365401598 Jst7TtAxsCtCwsNtvPstStts 4633;
BA_ "SPN" SG_ 2365401598 Jstk7GrpXAxsDtntPstnStts 4638;
BA_ "SPN" SG_ 2365401598 Jstk7GrpXAxsLvrLftNgtvPstnStts 4625;
BA_ "SPN" SG_ 2365401598 Jstk7GrpXAxsLvrRghtPstvPstnStts 4626;
BA_ "SPN" SG_ 2365401598 Jstk7GrpXAxsNtrlPstnStts 4624;
BA_ "SPN" SG_ 2365401598 Jstk7GrpYAxsDtntPstnStts 4637;
BA_ "SPN" SG_ 2365401598 Jstk7GrpYAxsLvrBkNgtvPstnStts 4629;
BA_ "SPN" SG_ 2365401598 Jstk7GrpYAxsNtrlPstnStts 4628;
BA_ "SPN" SG_ 2365401598 Jstk7ThtAxsClkwsPstvPstnStts 4634;
BA_ "SPN" SG_ 2365401598 Jstk7ThtAxsDtntPstnStts 4636;
BA_ "SPN" SG_ 2365401598 Jstk7ThtAxsNtrlPstnStts 4632;
BA_ "SPN" SG_ 2365401854 Joystick7Button10PressedStatus 4622;
BA_ "SPN" SG_ 2365401854 Joystick7Button11PressedStatus 4621;
BA_ "SPN" SG_ 2365401854 Joystick7Button12PressedStatus 4620;
BA_ "SPN" SG_ 2365401854 Joystick7Button1PressedStatus 4615;
BA_ "SPN" SG_ 2365401854 Joystick7Button2PressedStatus 4614;
BA_ "SPN" SG_ 2365401854 Joystick7Button3PressedStatus 4613;
BA_ "SPN" SG_ 2365401854 Joystick7Button4PressedStatus 4612;
BA_ "SPN" SG_ 2365401854 Joystick7Button5PressedStatus 4619;
BA_ "SPN" SG_ 2365401854 Joystick7Button6PressedStatus 4618;
BA_ "SPN" SG_ 2365401854 Joystick7Button7PressedStatus 4617;
BA_ "SPN" SG_ 2365401854 Joystick7Button8PressedStatus 4616;
BA_ "SPN" SG_ 2365401854 Joystick7Button9PressedStatus 4623;
BA_ "SPN" SG_ 2365401854 Joystick7XAxisPosition 4605;
BA_ "SPN" SG_ 2365401854 Joystick7YAxisPosition 4609;
BA_ "SPN" SG_ 2365401854 Jstk7XAxsDtntPstnStts 4611;
BA_ "SPN" SG_ 2365401854 Jstk7XAxsLvrLftNgtvPstnStts 4603;
BA_ "SPN" SG_ 2365401854 Jstk7XAxsLvrRghtPstvPstnStts 4604;
BA_ "SPN" SG_ 2365401854 Jstk7XAxsNtrlPstnStts 4602;
BA_ "SPN" SG_ 2365401854 Jstk7YAxsDtntPstnStts 4610;
BA_ "SPN" SG_ 2365401854 Jstk7YAxsLvrBkNgtvPstnStts 4607;
BA_ "SPN" SG_ 2365401854 Jstk7YAxsLvrFrwrdPstvPstnStts 4608;
BA_ "SPN" SG_ 2365401854 Jstk7YAxsNtrlPstnStts 4606;
BA_ "SPN" SG_ 2365402110 Joystick6Button13PressedStatus 6751;
BA_ "SPN" SG_ 2365402110 Joystick6Button14PressedStatus 6752;
BA_ "SPN" SG_ 2365402110 Joystick6Button15PressedStatus 6753;
BA_ "SPN" SG_ 2365402110 Joystick6Button16PressedStatus 6754;
BA_ "SPN" SG_ 2365402110 Joystick6GripXAxisPosition 4590;
BA_ "SPN" SG_ 2365402110 Joystick6GripYAxisPosition 4594;
BA_ "SPN" SG_ 2365402110 Joystick6ThetaAxisPosition 4598;
BA_ "SPN" SG_ 2365402110 Jst6GpYAxsLvFwdPstvPstStts 4593;
BA_ "SPN" SG_ 2365402110 Jst6TtAxsCtCwsNtvPstStts 4596;
BA_ "SPN" SG_ 2365402110 Jstk6GrpXAxsDtntPstnStts 4601;
BA_ "SPN" SG_ 2365402110 Jstk6GrpXAxsLvrLftNgtvPstnStts 4588;
BA_ "SPN" SG_ 2365402110 Jstk6GrpXAxsLvrRghtPstvPstnStts 4589;
BA_ "SPN" SG_ 2365402110 Jstk6GrpXAxsNtrlPstnStts 4587;
BA_ "SPN" SG_ 2365402110 Jstk6GrpYAxsDtntPstnStts 4600;
BA_ "SPN" SG_ 2365402110 Jstk6GrpYAxsLvrBkNgtvPstnStts 4592;
BA_ "SPN" SG_ 2365402110 Jstk6GrpYAxsNtrlPstnStts 4591;
BA_ "SPN" SG_ 2365402110 Jstk6ThtAxsClkwsPstvPstnStts 4597;
BA_ "SPN" SG_ 2365402110 Jstk6ThtAxsDtntPstnStts 4599;
BA_ "SPN" SG_ 2365402110 Jstk6ThtAxsNtrlPstnStts 4595;
BA_ "SPN" SG_ 2365402366 Joystick6Button10PressedStatus 4585;
BA_ "SPN" SG_ 2365402366 Joystick6Button11PressedStatus 4584;
BA_ "SPN" SG_ 2365402366 Joystick6Button12PressedStatus 4583;
BA_ "SPN" SG_ 2365402366 Joystick6Button1PressedStatus 4578;
BA_ "SPN" SG_ 2365402366 Joystick6Button2PressedStatus 4577;
BA_ "SPN" SG_ 2365402366 Joystick6Button3PressedStatus 4576;
BA_ "SPN" SG_ 2365402366 Joystick6Button4PressedStatus 4575;
BA_ "SPN" SG_ 2365402366 Joystick6Button5PressedStatus 4582;
BA_ "SPN" SG_ 2365402366 Joystick6Button6PressedStatus 4581;
BA_ "SPN" SG_ 2365402366 Joystick6Button7PressedStatus 4580;
BA_ "SPN" SG_ 2365402366 Joystick6Button8PressedStatus 4579;
BA_ "SPN" SG_ 2365402366 Joystick6Button9PressedStatus 4586;
BA_ "SPN" SG_ 2365402366 Joystick6XAxisPosition 4568;
BA_ "SPN" SG_ 2365402366 Joystick6YAxisPosition 4572;
BA_ "SPN" SG_ 2365402366 Jstk6XAxsDtntPstnStts 4574;
BA_ "SPN" SG_ 2365402366 Jstk6XAxsLvrLftNgtvPstnStts 4566;
BA_ "SPN" SG_ 2365402366 Jstk6XAxsLvrRghtPstvPstnStts 4567;
BA_ "SPN" SG_ 2365402366 Jstk6XAxsNtrlPstnStts 4565;
BA_ "SPN" SG_ 2365402366 Jstk6YAxsDtntPstnStts 4573;
BA_ "SPN" SG_ 2365402366 Jstk6YAxsLvrBkNgtvPstnStts 4570;
BA_ "SPN" SG_ 2365402366 Jstk6YAxsLvrFrwrdPstvPstnStts 4571;
BA_ "SPN" SG_ 2365402366 Jstk6YAxsNtrlPstnStts 4569;
BA_ "SPN" SG_ 2365402622 Joystick5Button13PressedStatus 6747;
BA_ "SPN" SG_ 2365402622 Joystick5Button14PressedStatus 6748;
BA_ "SPN" SG_ 2365402622 Joystick5Button15PressedStatus 6749;
BA_ "SPN" SG_ 2365402622 Joystick5Button16PressedStatus 6750;
BA_ "SPN" SG_ 2365402622 Joystick5GripXAxisPosition 4553;
BA_ "SPN" SG_ 2365402622 Joystick5GripYAxisPosition 4557;
BA_ "SPN" SG_ 2365402622 Joystick5ThetaAxisPosition 4561;
BA_ "SPN" SG_ 2365402622 Jst5GpYAxsLvFwdPstvPstStts 4556;
BA_ "SPN" SG_ 2365402622 Jst5TtAxsCtCwsNtvPstStts 4559;
BA_ "SPN" SG_ 2365402622 Jstk5GrpXAxsDtntPstnStts 4564;
BA_ "SPN" SG_ 2365402622 Jstk5GrpXAxsLvrLftNgtvPstnStts 4551;
BA_ "SPN" SG_ 2365402622 Jstk5GrpXAxsLvrRghtPstvPstnStts 4552;
BA_ "SPN" SG_ 2365402622 Jstk5GrpXAxsNtrlPstnStts 4550;
BA_ "SPN" SG_ 2365402622 Jstk5GrpYAxsDtntPstnStts 4563;
BA_ "SPN" SG_ 2365402622 Jstk5GrpYAxsLvrBkNgtvPstnStts 4555;
BA_ "SPN" SG_ 2365402622 Jstk5GrpYAxsNtrlPstnStts 4554;
BA_ "SPN" SG_ 2365402622 Jstk5ThtAxsClkwsPstvPstnStts 4560;
BA_ "SPN" SG_ 2365402622 Jstk5ThtAxsDtntPstnStts 4562;
BA_ "SPN" SG_ 2365402622 Jstk5ThtAxsNtrlPstnStts 4558;
BA_ "SPN" SG_ 2365402878 Joystick5Button10PressedStatus 4548;
BA_ "SPN" SG_ 2365402878 Joystick5Button11PressedStatus 4547;
BA_ "SPN" SG_ 2365402878 Joystick5Button12PressedStatus 4546;
BA_ "SPN" SG_ 2365402878 Joystick5Button1PressedStatus 4541;
BA_ "SPN" SG_ 2365402878 Joystick5Button2PressedStatus 4540;
BA_ "SPN" SG_ 2365402878 Joystick5Button3PressedStatus 4539;
BA_ "SPN" SG_ 2365402878 Joystick5Button4PressedStatus 4538;
BA_ "SPN" SG_ 2365402878 Joystick5Button5PressedStatus 4545;
BA_ "SPN" SG_ 2365402878 Joystick5Button6PressedStatus 4544;
BA_ "SPN" SG_ 2365402878 Joystick5Button7PressedStatus 4543;
BA_ "SPN" SG_ 2365402878 Joystick5Button8PressedStatus 4542;
BA_ "SPN" SG_ 2365402878 Joystick5Button9PressedStatus 4549;
BA_ "SPN" SG_ 2365402878 Joystick5XAxisPosition 4531;
BA_ "SPN" SG_ 2365402878 Joystick5YAxisPosition 4535;
BA_ "SPN" SG_ 2365402878 Jstk5XAxsDtntPstnStts 4537;
BA_ "SPN" SG_ 2365402878 Jstk5XAxsLvrLftNgtvPstnStts 4529;
BA_ "SPN" SG_ 2365402878 Jstk5XAxsLvrRghtPstvPstnStts 4530;
BA_ "SPN" SG_ 2365402878 Jstk5XAxsNtrlPstnStts 4528;
BA_ "SPN" SG_ 2365402878 Jstk5YAxsDtntPstnStts 4536;
BA_ "SPN" SG_ 2365402878 Jstk5YAxsLvrBkNgtvPstnStts 4533;
BA_ "SPN" SG_ 2365402878 Jstk5YAxsLvrFrwrdPstvPstnStts 4534;
BA_ "SPN" SG_ 2365402878 Jstk5YAxsNtrlPstnStts 4532;
BA_ "SPN" SG_ 2365403134 Joystick4Button13PressedStatus 6743;
BA_ "SPN" SG_ 2365403134 Joystick4Button14PressedStatus 6744;
BA_ "SPN" SG_ 2365403134 Joystick4Button15PressedStatus 6745;
BA_ "SPN" SG_ 2365403134 Joystick4Button16PressedStatus 6746;
BA_ "SPN" SG_ 2365403134 Joystick4GripXAxisPosition 4516;
BA_ "SPN" SG_ 2365403134 Joystick4GripYAxisPosition 4520;
BA_ "SPN" SG_ 2365403134 Joystick4ThetaAxisPosition 4524;
BA_ "SPN" SG_ 2365403134 Jst4GpYAxsLvFwdPstvPstStts 4519;
BA_ "SPN" SG_ 2365403134 Jst4TtAxsCtCwsNtvPstStts 4522;
BA_ "SPN" SG_ 2365403134 Jstk4GrpXAxsDtntPstnStts 4527;
BA_ "SPN" SG_ 2365403134 Jstk4GrpXAxsLvrLftNgtvPstnStts 4514;
BA_ "SPN" SG_ 2365403134 Jstk4GrpXAxsLvrRghtPstvPstnStts 4515;
BA_ "SPN" SG_ 2365403134 Jstk4GrpXAxsNtrlPstnStts 4513;
BA_ "SPN" SG_ 2365403134 Jstk4GrpYAxsDtntPstnStts 4526;
BA_ "SPN" SG_ 2365403134 Jstk4GrpYAxsLvrBkNgtvPstnStts 4518;
BA_ "SPN" SG_ 2365403134 Jstk4GrpYAxsNtrlPstnStts 4517;
BA_ "SPN" SG_ 2365403134 Jstk4ThtAxsClkwsPstvPstnStts 4523;
BA_ "SPN" SG_ 2365403134 Jstk4ThtAxsDtntPstnStts 4525;
BA_ "SPN" SG_ 2365403134 Jstk4ThtAxsNtrlPstnStts 4521;
BA_ "SPN" SG_ 2365403390 Joystick4Button10PressedStatus 4511;
BA_ "SPN" SG_ 2365403390 Joystick4Button11PressedStatus 4510;
BA_ "SPN" SG_ 2365403390 Joystick4Button12PressedStatus 4509;
BA_ "SPN" SG_ 2365403390 Joystick4Button1PressedStatus 4504;
BA_ "SPN" SG_ 2365403390 Joystick4Button2PressedStatus 4503;
BA_ "SPN" SG_ 2365403390 Joystick4Button3PressedStatus 4502;
BA_ "SPN" SG_ 2365403390 Joystick4Button4PressedStatus 4501;
BA_ "SPN" SG_ 2365403390 Joystick4Button5PressedStatus 4508;
BA_ "SPN" SG_ 2365403390 Joystick4Button6PressedStatus 4507;
BA_ "SPN" SG_ 2365403390 Joystick4Button7PressedStatus 4506;
BA_ "SPN" SG_ 2365403390 Joystick4Button8PressedStatus 4505;
BA_ "SPN" SG_ 2365403390 Joystick4Button9PressedStatus 4512;
BA_ "SPN" SG_ 2365403390 Joystick4XAxisPosition 4494;
BA_ "SPN" SG_ 2365403390 Joystick4YAxisPosition 4498;
BA_ "SPN" SG_ 2365403390 Jstk4XAxsDtntPstnStts 4500;
BA_ "SPN" SG_ 2365403390 Jstk4XAxsLvrLftNgtvPstnStts 4492;
BA_ "SPN" SG_ 2365403390 Jstk4XAxsLvrRghtPstvPstnStts 4493;
BA_ "SPN" SG_ 2365403390 Jstk4XAxsNtrlPstnStts 4491;
BA_ "SPN" SG_ 2365403390 Jstk4YAxsDtntPstnStts 4499;
BA_ "SPN" SG_ 2365403390 Jstk4YAxsLvrBkNgtvPstnStts 4496;
BA_ "SPN" SG_ 2365403390 Jstk4YAxsLvrFrwrdPstvPstnStts 4497;
BA_ "SPN" SG_ 2365403390 Jstk4YAxsNtrlPstnStts 4495;
BA_ "SPN" SG_ 2365428478 EngineControlledShutdownRequest 3606;
BA_ "SPN" SG_ 2365428478 EngineCoolantPumpControl 3605;
BA_ "SPN" SG_ 2365428478 EngineDerateRequest 3644;
BA_ "SPN" SG_ 2365428478 EngineDesiredTorqueRequest 6807;
BA_ "SPN" SG_ 2365428478 EngineFuelShutoff1Control 632;
BA_ "SPN" SG_ 2365428478 EngineFuelShutoff2Control 2807;
BA_ "SPN" SG_ 2365428478 EngineFuelShutoffVentControl 3608;
BA_ "SPN" SG_ 2365428478 EngineOilPreheaterControl 3602;
BA_ "SPN" SG_ 2365428478 EngineOilPrimingPumpControl 3589;
BA_ "SPN" SG_ 2365428478 EngineOperatingState 3543;
BA_ "SPN" SG_ 2365428478 EnginePreHeaterControl 3604;
BA_ "SPN" SG_ 2365428478 EngineStarterMotorRelayControl 6385;
BA_ "SPN" SG_ 2365428478 EngnCldAmntElvtdIdlStts 6884;
BA_ "SPN" SG_ 2365428478 EngnEltrlSstmPwrCnsrvtnCntrl 3603;
BA_ "SPN" SG_ 2365428478 EngnEmrgnImmdtShtdwnIndtn 3607;
BA_ "SPN" SG_ 2365428478 EngnFlShtffVlvLkTstCntrl 3601;
BA_ "SPN" SG_ 2365428478 FuelPumpPrimerControl 4082;
BA_ "SPN" SG_ 2365428478 TmRmnngnEngnOprtngStt 3544;
BA_ "SPN" SG_ 2365428734 EngineSpeedGovernorDroop 5568;
BA_ "SPN" SG_ 2365428734 EngineSpeedGovernorGainAdjust 5567;
BA_ "SPN" SG_ 2365428734 GeneratorAlternatorEfficiency 4078;
BA_ "SPN" SG_ 2365428734 GeneratorFrequencySelection 4080;
BA_ "SPN" SG_ 2365428734 GeneratorGoverningSpeedCommand 4079;
BA_ "SPN" SG_ 2365428734 GnrtrCntrlNtInAtmtStrtStt 3567;
BA_ "SPN" SG_ 2365428734 GnrtrNtRdtAtmtllPrlllStt 3568;
BA_ "SPN" SG_ 2365428734 RequestedEngineControlMode 3542;
BA_ "SPN" SG_ 2365433598 GeneratorExcitationFieldCurrent 3381;
BA_ "SPN" SG_ 2365433598 GeneratorExcitationFieldVoltage 3380;
BA_ "SPN" SG_ 2365433598 GnrtrOtptVltgBsPrntg 3382;
BA_ "SPN" SG_ 2365443326 HazardLightSwitch 2875;
BA_ "SPN" SG_ 2365443326 HighLowBeamSwitch 2874;
BA_ "SPN" SG_ 2365443326 MainLightSwitch 2872;
BA_ "SPN" SG_ 2365443326 OperatorsDesiredBacklight 2878;
BA_ "SPN" SG_ 2365443326 OprtrsDsrdDldLmpOffTm 2877;
BA_ "SPN" SG_ 2365443326 TurnSignalSwitch 2876;
BA_ "SPN" SG_ 2365443326 WorkLightSwitch 2873;
BA_ "SPN" SG_ 2365443326 ExteriorLampCheckSwitch 4004;
BA_ "SPN" SG_ 2365443326 HeadlampEmergencyFlashSwitch 12308;
BA_ "SPN" SG_ 2365445886 Joystick1Button10PressedStatus 2694;
BA_ "SPN" SG_ 2365445886 Joystick1Button11PressedStatus 2695;
BA_ "SPN" SG_ 2365445886 Joystick1Button12PressedStatus 2696;
BA_ "SPN" SG_ 2365445886 Joystick1Button1PressedStatus 2685;
BA_ "SPN" SG_ 2365445886 Joystick1Button2PressedStatus 2686;
BA_ "SPN" SG_ 2365445886 Joystick1Button3PressedStatus 2687;
BA_ "SPN" SG_ 2365445886 Joystick1Button4PressedStatus 2688;
BA_ "SPN" SG_ 2365445886 Joystick1Button5PressedStatus 2689;
BA_ "SPN" SG_ 2365445886 Joystick1Button6PressedStatus 2690;
BA_ "SPN" SG_ 2365445886 Joystick1Button7PressedStatus 2691;
BA_ "SPN" SG_ 2365445886 Joystick1Button8PressedStatus 2692;
BA_ "SPN" SG_ 2365445886 Joystick1Button9PressedStatus 2693;
BA_ "SPN" SG_ 2365445886 Joystick1XAxisPosition 2660;
BA_ "SPN" SG_ 2365445886 Joystick1YAxisPosition 2661;
BA_ "SPN" SG_ 2365445886 Jstk1XAxsDtntPstnStts 2680;
BA_ "SPN" SG_ 2365445886 Jstk1XAxsLvrLftNgtvPstnStts 2670;
BA_ "SPN" SG_ 2365445886 Jstk1XAxsLvrRghtPstvPstnStts 2665;
BA_ "SPN" SG_ 2365445886 Jstk1XAxsNtrlPstnStts 2675;
BA_ "SPN" SG_ 2365445886 Jstk1YAxsDtntPstnStts 2681;
BA_ "SPN" SG_ 2365445886 Jstk1YAxsLvrBkNgtvPstnStts 2671;
BA_ "SPN" SG_ 2365445886 Jstk1YAxsLvrFrwrdPstvPstnStts 2666;
BA_ "SPN" SG_ 2365445886 Jstk1YAxsNtrlPstnStts 2676;
